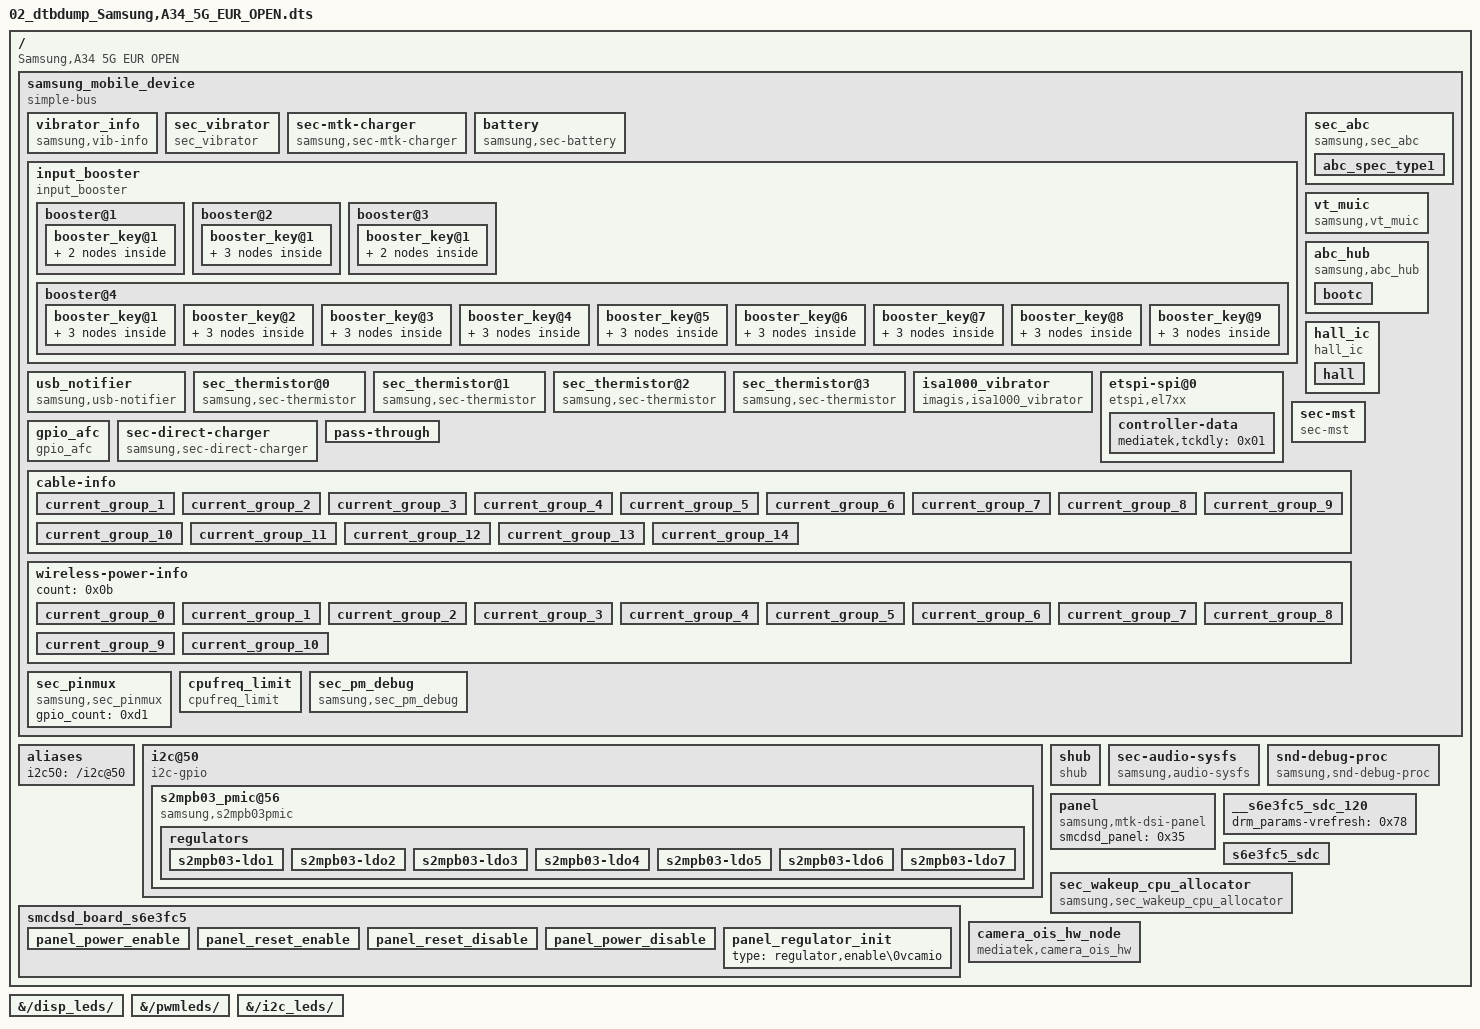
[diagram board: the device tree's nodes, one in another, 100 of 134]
/dts-v1/;

/ {
	compatible = "Samsung,A34 5G EUR OPEN\0Mediatek,MT6877";
	dtbo-hw_rev = <0x05>;
	dtbo-hw_rev_end = <0x20>;

	fragment@smd {
		target-path = "/";

		__overlay__ {

			samsung_mobile_device {
				compatible = "simple-bus";
				#address-cells = <0x01>;
				#size-cells = <0x00>;

				vibrator_info {
					status = "okay";
					compatible = "samsung,vib-info";
					functions = "INTENSITY\0HAPTIC_ENGINE";
					samsung,intensities = <0x00 0x7d0 0xfa0 0x1770 0x1f40 0x2710>;
					samsung,haptic_intensities = <0x00 0xbb8 0xfa0 0x1770 0x1f40 0x2710>;
				};

				sec_vibrator {
					status = "okay";
					compatible = "sec_vibrator";
					haptic,normal_ratio = <0x54>;
					haptic,high_temp_ref = <0x30>;
					haptic,high_temp_ratio = <0x47>;
				};

				sec-mtk-charger {
					compatible = "samsung,sec-mtk-charger";
					charger,vbus_min_charger_voltage = <0x432380>;
					charger,vbus_normal_mivr_voltage = <0x432380>;
					charger,gpio_chgenb = <0xffffffff 0x1b 0x00>;
					charger,max_icl = <0xc99>;
					charger,ib_fcc = <0x64>;
					charger,mt6360_charger = <0x01>;
				};

				battery {
					battery,otg_name = "mtk-otg";
					battery,fuelgauge_name = "mtk-fg-battery";
					status = "okay";
					compatible = "samsung,sec-battery";
					battery,vendor = "Battery";
					battery,charger_name = "sec-direct-charger";
					battery,technology = <0x02>;
					battery,chip_vendor = "MTK";
					battery,batt_data_version = <0x01>;
					battery,adc_check_count = <0x05>;
					battery,temp_check_type = <0x01>;
					battery,usb_temp_check_type = <0x00>;
					battery,chg_temp_check_type = <0x01>;
					battery,wpc_temp_check_type = <0x00>;
					battery,lrp_temp_check_type = <0x02>;
					battery,thermal_source = <0x05>;
					battery,usb_thermal_source = <0x00>;
					battery,chg_thermal_source = <0x02>;
					battery,wpc_thermal_source = <0x00>;
					battery,inbat_ocv_type = <0x04>;
					battery,polling_time = <0x0a 0x1e 0x1e 0x1e 0xe10>;
					battery,cable_check_type = <0x04>;
					battery,cable_source_type = <0x01>;
					battery,polling_type = <0x01>;
					battery,monitor_initial_count = <0x00>;
					battery,battery_check_type = <0x00>;
					battery,ovp_uvlo_check_type = <0x03>;
					battery,temp_check_count = <0x01>;
					battery,usb_protection_temp = <0x262>;
					battery,temp_gap_bat_usb = <0xc8>;
					battery,overheatlimit_threshold = <0x2bc>;
					battery,overheatlimit_recovery = <0x2a8>;
					battery,wire_warm_overheat_thresh = <0x1f4>;
					battery,wire_normal_warm_thresh = <0x1a4>;
					battery,wire_cool1_normal_thresh = <0xb4>;
					battery,wire_cool2_cool1_thresh = <0x96>;
					battery,wire_cool3_cool2_thresh = <0x32>;
					battery,wire_cold_cool3_thresh = <0x00>;
					battery,wireless_warm_overheat_thresh = <0x1f4>;
					battery,wireless_normal_warm_thresh = <0x1a4>;
					battery,wireless_cool1_normal_thresh = <0xb4>;
					battery,wireless_cool2_cool1_thresh = <0x96>;
					battery,wireless_cool3_cool2_thresh = <0x32>;
					battery,wireless_cold_cool3_thresh = <0x00>;
					battery,tx_high_threshold = <0x1f4>;
					battery,tx_high_recovery = <0x1c2>;
					battery,tx_low_threshold = <0x00>;
					battery,tx_low_recovery = <0x32>;
					battery,wire_warm_current = <0xdac>;
					battery,wire_cool1_current = <0xbb8>;
					battery,wire_cool2_current = <0x47e>;
					battery,wire_cool3_current = <0x1c2>;
					battery,wireless_warm_current = <0x418>;
					battery,wireless_cool1_current = <0xc4a>;
					battery,wireless_cool2_current = <0x418>;
					battery,wireless_cool3_current = <0x1b5>;
					battery,full_check_type = <0x02>;
					battery,full_check_type_2nd = <0x02>;
					battery,full_check_count = <0x01>;
					battery,chg_gpio_full_check = <0x00>;
					battery,chg_polarity_full_check = <0x01>;
					battery,chg_high_temp = <0x24e>;
					battery,chg_high_temp_recovery = <0x226>;
					battery,chg_input_limit_current = <0x3e8>;
					battery,chg_charging_limit_current = <0x76c>;
					battery,dchg_high_temp = <0x3e8 0x3e8 0x24e 0x24e>;
					battery,dchg_high_temp_recovery = <0x3e8 0x3e8 0x226 0x226>;
					battery,dchg_high_batt_temp = <0x3e8 0x3e8 0x3e8 0x3e8>;
					battery,dchg_high_batt_temp_recovery = <0x3e8 0x3e8 0x3e8 0x3e8>;
					battery,dchg_input_limit_current = <0x44c>;
					battery,dchg_charging_limit_current = <0x898>;
					battery,wpc_temp_control_source = <0x01>;
					battery,wpc_high_temp = <0x190>;
					battery,wpc_high_temp_recovery = <0x17c>;
					battery,wpc_input_limit_current = <0x320>;
					battery,wpc_charging_limit_current = <0x3e8>;
					battery,wpc_temp_lcd_on_control_source = <0x01>;
					battery,wpc_lcd_on_input_limit_current = <0x320>;
					battery,wpc_store_high_temp = <0x168>;
					battery,wpc_store_high_temp_recovery = <0x154>;
					battery,wpc_store_charging_limit_current = <0x190>;
					battery,wpc_store_lcd_on_high_temp = <0x168>;
					battery,wpc_store_lcd_on_high_temp_rec = <0x12c>;
					battery,wpc_store_lcd_on_charging_limit_current = <0x190>;
					battery,fcc_by_tx = <0x4b0>;
					battery,sleep_mode_limit_current = <0x320>;
					battery,wc_full_input_limit_current = <0x64>;
					battery,ta_alert_wa;
					battery,mix_high_temp = <0x1a4>;
					battery,mix_high_chg_temp = <0x1f4>;
					battery,mix_high_temp_recovery = <0x186>;
					battery,mix_v2_lrp_recov = <0x1cc>;
					battery,mix_v2_lrp_cond = <0x1e0>;
					battery,mix_v2_bat_cond = <0x1e0>;
					battery,mix_v2_chg_cond = <0x00>;
					battery,mix_v2_dchg_cond = <0x00>;
					battery,full_condition_type = <0x09>;
					battery,full_condition_soc = <0x5d>;
					battery,recharge_check_count = <0x01>;
					battery,recharge_condition_type = <0x04>;
					battery,recharge_condition_soc = <0x62>;
					battery,charging_reset_time = <0x00>;
					battery,chg_float_voltage = <0x1144>;
					battery,pre_afc_work_delay = <0x7d0>;
					battery,pre_wc_afc_work_delay = <0xfa0>;
					battery,pre_afc_input_current = <0x1f4>;
					battery,pre_wc_afc_input_current = <0x1f4>;
					battery,swelling_high_rechg_voltage = <0xfd2>;
					battery,siop_icl = <0x4b0>;
					battery,siop_fcc = <0x708>;
					battery,siop_hv_icl = <0x2bc>;
					battery,siop_hv_icl_2nd = <0x226>;
					battery,siop_hv_fcc = <0x708>;
					battery,siop_apdo_icl = <0x3e8>;
					battery,siop_apdo_fcc = <0x7d0>;
					battery,siop_wpc_icl = <0x258>;
					battery,siop_wpc_fcc = <0x3e8 0x1f4 0x64>;
					battery,siop_hv_wpc_icl = <0x2bc>;
					battery,siop_hv_wpc_fcc = <0x3e8 0x1f4 0x64>;
					battery,siop_store_hv_wpc_icl = <0x1c2>;
					battery,store_mode_buckoff;
					battery,temp_table_LRP_45W = <0x181 0x16d>;
					battery,rp_current_rp1 = <0x1f4>;
					battery,rp_current_rp2 = <0x5dc>;
					battery,rp_current_rp3 = <0xbb8>;
					battery,rp_current_rdu_rp3 = <0x834>;
					battery,rp_current_abnormal_rp3 = <0x708>;
					battery,pd_charging_charge_power = <0x3a98>;
					battery,max_charging_current = <0xbb8>;
					battery,store_mode_charging_max = <0x46>;
					battery,store_mode_charging_min = <0x3c>;
					battery,wireless_cc_cv = <0x55>;
					battery,wireless_otg_input_current = <0x384>;
					battery,age_data_cycle = <0x00 0x12c 0x190 0x2bc 0x3e9>;
					battery,age_data_full_condition_soc = <0x5d 0x5c 0x5b 0x5a 0x59>;
					battery,age_data_common_offset = <0x00 0x14 0x28 0x3c 0x6e>;
					battery,age_data = <0x00 0x10fe 0x10b8 0x109a 0x5d 0x12c 0x10ea 0x10a4 0x1086 0x5c 0x190 0x10d6 0x1090 0x1072 0x5b 0x2bc 0x10c2 0x107c 0x105e 0x5a 0x3e8 0x1090 0x104a 0x102c 0x59>;
					battery,health_condition_cycle = <0x384 0x4b0 0x5dc>;
					battery,health_condition_asoc = <0x00 0x00 0x00>;
					battery,max_input_voltage = <0x2328>;
					battery,max_input_current = <0xbb8>;
					battery,cisd_alg_index = <0x08>;
					battery,cisd_max_voltage_thr = <0x1388>;
					battery,ignore_cisd_index = <0x00 0x00>;
					battery,ignore_cisd_index_d = <0x00 0x50>;
					battery,expired_time = <0x2670>;
					battery,recharging_expired_time = <0x1518>;
					battery,battery_full_capacity = <0x1388>;
					battery,ttf_capacity = <0xf23>;
					battery,cv_data = <0xe06 0x33e 0x6b1 0xcaf 0x352 0x63f 0xaa0 0x366 0x5c3 0x876 0x37a 0x527 0x6a5 0x38e 0x477 0x4ed 0x3a2 0x39e 0x3ac 0x3b6 0x2a4 0x29f 0x3ca 0x17d 0x22a 0x3de 0x5d 0x205 0x3e8 0x00>;
					io-channels = <0xffffffff 0x03>;
					io-channel-names = "adc-chg-temp\0n/a\0n/a\0n/a\0n/a\0n/a\0n/a\0n/a";
					pinctrl-names = "default";
					battery,adc_read_type = <0x01>;
					battery,dchg_temp_check_type = <0x02>;
					battery,dchg_thermal_source = <0x02>;
					battery,dctp_by_cgtp;
					battery,temp_table_adc = <0xe5 0xff 0x119 0x14c 0x17c 0x1bd 0x1f9 0x24f 0x2b2 0x33f 0x3a5 0x420 0x4b2 0x54b 0x5e7 0x69f 0x72a 0x7cb 0x855 0x8d5 0x93f 0x9a0 0x9fe>;
					battery,temp_table_data = <0x384 0x352 0x320 0x2ee 0x2bc 0x28a 0x258 0x226 0x1f4 0x1c2 0x190 0x15e 0x12c 0xfa 0xc8 0x96 0x64 0x32 0x00 0xffffffce 0xffffff9c 0xffffff6a 0xffffff38>;
					battery,chg_temp_table_adc = <0x140 0x182 0x1cc 0x221 0x25f 0x2d0 0x326 0x3a9 0x473 0x52c 0x614 0x6f4 0x7ed 0x8ed 0xa1d 0xb4c 0xc53 0xd00 0xe06 0xef4 0xfbd 0xff1 0xfff>;
					battery,chg_temp_table_data = <0x384 0x352 0x320 0x2ee 0x2bc 0x28a 0x258 0x226 0x1f4 0x1c2 0x190 0x15e 0x12c 0xfa 0xc8 0x96 0x64 0x32 0x00 0xffffffce 0xffffff9c 0xffffff6a 0xffffff38>;
					battery,usb_protection;
					battery,high_temp_topoff = <0xfa>;
					battery,low_temp_topoff = <0xfa>;
					battery,high_temp_float = <0x1068>;
					battery,low_temp_float = <0x1144>;
					battery,dchg_dc_in_swelling;
					battery,temp_table_LRP_NORMAL = <0x190 0x186 0x186 0x17c 0x186 0x17c 0x17c 0x172 0x3e8 0x960 0x4b0 0x708>;
					battery,temp_table_LRP_25W = <0x19a 0x190 0x186 0x17c 0x190 0x186 0x17c 0x172 0x6a4 0xd48 0x44c 0x898>;
					battery,swelling_low_rechg_voltage = <0x10ae>;
					battery,max_charging_charge_power = <0x61a8>;
					battery,age_data_by_common_offset;
					battery,dc_step_chg_type = <0xe9>;
					battery,dc_step_chg_charge_power = <0x55f0>;
					battery,dc_step_chg_step = <0x03>;
					battery,dc_step_chg_cond_v_margin = <0x50>;
					battery,dc_step_chg_cond_vol = <0x1022 0x109a 0x1144>;
					battery,dc_step_chg_cond_iin = <0x8f2 0x721 0x00>;
					battery,dc_step_chg_iin_check_cnt = <0x03>;
					battery,dc_step_chg_cond_soc = <0x2f 0x41 0x64>;
					battery,dc_step_chg_val_vfloat = <0x1022 0x109a 0x1144>;
					battery,dc_step_chg_val_iout = <0x15a4 0x11e4 0xe42>;
					battery,siop_scenarios = <0x14 0x00>;
					battery,siop_curr_type_num = <0x03>;
					battery,siop_icl_20 = <0x3e8 0x3e8 0x3e8>;
					battery,siop_fcc_20 = <0xffff 0xffff 0xffff>;
					battery,siop_icl_0 = <0x3e8 0x3e8 0x3e8>;
					battery,siop_fcc_0 = <0xffff 0xffff 0xffff>;
					battery,standard_curr = <0xe6a>;
					battery,slowcharging_usb_bootcomplete;
					battery,dynamic_cv_factor;
					battery,change_FV_after_full = <0x1144>;
					battery,ttf_hv_charge_current = <0x825>;
					battery,ttf_dc25_charge_current = <0xe10>;
					battery,boosting_voltage_aicl;
				};

				input_booster {
					status = "okay";
					compatible = "input_booster";
					resValcount = "2";
					max_resource_count = "2";
					max_cluster_count = "3";
					#address-cells = <0x01>;
					#size-cells = <0x00>;
					cpu_cluster_policy = "6,0";
					ib_release_values = "-1,16";
					allowed_resources = "0,1";

					booster@1 {
						booster,label = "Disable_Mode";
						booster,mode = "1";

						booster_key@1 {
							input_booster,label = "Touch_Disable";
							input_booster,type = <0x02>;
							input_booster,head_time = <0x00>;
							input_booster,tail_time = <0x00>;

							input_booster,resource {
								compatible = "resource";

								resource@1 {
									resource,label = "CPU";
									resource,id = "0";
									resource,value = <0x00 0x00>;
								};
							};
						};
					};

					booster@2 {
						booster,label = "Sip_Mode";
						booster,mode = "2";

						booster_key@1 {
							input_booster,label = "sip_touch";
							input_booster,type = <0x02>;
							input_booster,head_time = <0x78>;
							input_booster,tail_time = <0x00>;

							input_booster,resource {
								compatible = "resource";

								resource@1 {
									resource,label = "CPU";
									resource,id = "0";
									resource,value = <0x116520 0x00>;
								};

								resource@2 {
									resource,label = "DDR";
									resource,id = "1";
									resource,value = <0x10aa 0x10aa>;
								};
							};
						};
					};

					booster@3 {
						booster,label = "Game_Mode";
						booster,mode = "3";

						booster_key@1 {
							input_booster,label = "GAME_MT";
							input_booster,type = <0x03>;
							input_booster,head_time = <0x00>;
							input_booster,tail_time = <0x00>;

							input_booster,resource {
								compatible = "resource";

								resource@1 {
									resource,label = "CPU";
									resource,id = "0";
									resource,value = <0x00 0x00>;
								};
							};
						};
					};

					booster@4 {
						booster,label = "input_booster";
						booster,mode = "0";

						booster_key@1 {
							input_booster,label = "key";
							input_booster,type = <0x00>;
							input_booster,head_time = <0xc8>;
							input_booster,tail_time = <0x00>;

							inputbooster,resource {
								compatible = "resource";

								resource@1 {
									resource,label = "CPU";
									resource,id = "0";
									resource,value = <0x177fa0 0x00>;
								};

								resource@2 {
									resource,label = "DDR";
									resource,id = "1";
									resource,value = <0x00 0x00>;
								};
							};
						};

						booster_key@2 {
							input_booster,label = "touchkey";
							input_booster,type = <0x01>;
							input_booster,head_time = <0x01>;
							input_booster,tail_time = <0x12c>;

							inputbooster,resource {
								compatible = "resource";

								resource@1 {
									resource,label = "CPU";
									resource,id = "0";
									resource,value = <0x00 0x00>;
								};

								resource@2 {
									resource,label = "DDR";
									resource,id = "1";
									resource,value = <0x00 0x00>;
								};
							};
						};

						booster_key@3 {
							input_booster,label = "touch";
							input_booster,type = <0x02>;
							input_booster,head_time = <0x82>;
							input_booster,tail_time = <0x1f4>;

							inputbooster,resource {
								compatible = "resource";

								resource@1 {
									resource,label = "CPU";
									resource,id = "0";
									resource,value = <0x116520 0x106800>;
								};

								resource@2 {
									resource,label = "DDR";
									resource,id = "1";
									resource,value = <0x10aa 0x10aa>;
								};
							};
						};

						booster_key@4 {
							input_booster,label = "multitouch";
							input_booster,type = <0x03>;
							input_booster,head_time = <0x3e8>;
							input_booster,tail_time = <0x1f4>;

							inputbooster,resource {
								compatible = "resource";

								resource@1 {
									resource,label = "CPU";
									resource,id = "0";
									resource,value = <0x116520 0x106800>;
								};

								resource@2 {
									resource,label = "DDR";
									resource,id = "1";
									resource,value = <0x10aa 0x10aa>;
								};
							};
						};

						booster_key@5 {
							input_booster,label = "keyboard";
							input_booster,type = <0x04>;
							input_booster,head_time = <0x82>;
							input_booster,tail_time = <0x82>;

							inputbooster,resource {
								compatible = "resource";

								resource@1 {
									resource,label = "CPU";
									resource,id = "0";
									resource,value = <0x15d1f0 0xfde80>;
								};

								resource@2 {
									resource,label = "DDR";
									resource,id = "1";
									resource,value = <0x10aa 0x10aa>;
								};
							};
						};

						booster_key@6 {
							input_booster,label = "MOUSE";
							input_booster,type = <0x05>;
							input_booster,head_time = <0xc8>;
							input_booster,tail_time = <0x12c>;

							inputbooster,resource {
								compatible = "resource";

								resource@1 {
									resource,label = "CPU";
									resource,id = "0";
									resource,value = <0x15d1f0 0xfde80>;
								};

								resource@2 {
									resource,label = "DDR";
									resource,id = "1";
									resource,value = <0x10aa 0x10aa>;
								};
							};
						};

						booster_key@7 {
							input_booster,label = "mouse_wheel";
							input_booster,type = <0x06>;
							input_booster,head_time = <0xc8>;
							input_booster,tail_time = <0x00>;

							inputbooster,resource {
								compatible = "resource";

								resource@1 {
									resource,label = "CPU";
									resource,id = "0";
									resource,value = <0x15d1f0 0x00>;
								};

								resource@2 {
									resource,label = "DDR";
									resource,id = "1";
									resource,value = <0x10aa 0x00>;
								};
							};
						};

						booster_key@8 {
							input_booster,label = "pen_hover";
							input_booster,type = <0x07>;
							input_booster,head_time = <0xc8>;
							input_booster,tail_time = <0x12c>;

							inputbooster,resource {
								compatible = "resource";

								resource@1 {
									resource,label = "CPU";
									resource,id = "0";
									resource,value = <0x15d1f0 0xfde80>;
								};

								resource@2 {
									resource,label = "DDR";
									resource,id = "1";
									resource,value = <0x00 0x00>;
								};
							};
						};

						booster_key@9 {
							input_booster,label = "pen";
							input_booster,type = <0x08>;
							input_booster,head_time = <0xc8>;
							input_booster,tail_time = <0x258>;

							inputbooster,resource {
								compatible = "resource";

								resource@1 {
									resource,label = "CPU";
									resource,id = "0";
									resource,value = <0x1b7740 0xfde80>;
								};

								resource@2 {
									resource,label = "DDR";
									resource,id = "1";
									resource,value = <0x10aa 0x10aa>;
								};
							};
						};
					};
				};

				sec_abc {
					compatible = "samsung,sec_abc";
					status = "okay";

					abc_spec_type1 {
						module_list = "gpu\0gpu_qc\0gpu_qc\0camera\0camera\0vib\0tsp\0tsp_sub\0mm\0camera\0camera\0camera\0camera\0camera\0camera\0camera\0camera\0camera\0gpu";
						name_list = "gpu_fault\0gpu_fault\0gpu_page_fault\0mipi_overflow\0i2c_fail\0int_gnd_short\0tsp_int_fault\0tsp_int_fault\0venus_hung\0mipi_error_rw1\0mipi_error_rs1\0mipi_error_rt1\0mipi_error_fw1\0mipi_error_rt2\0mipi_error_uw1\0mipi_error_rm1\0mipi_error_rb1\0mipi_error_fs1\0gpu_job_timeout";
						threshold_cnt = <0x14 0x02 0x14 0x01 0x01 0x19 0x02 0x02 0x0a 0x01 0x01 0x01 0x01 0x01 0x01 0x01 0x01 0x01 0x01>;
						threshold_time = <0x4b0 0x4b0 0x4b0 0x00 0x00 0x05 0x05 0x05 0x03 0x00 0x00 0x00 0x00 0x00 0x00 0x00 0x00 0x00 0x00>;
					};
				};

				vt_muic {
					compatible = "samsung,vt_muic";
					status = "okay";
					use_battery_notifier_callback;
					use_manager_notifier_callback;
				};

				abc_hub {
					compatible = "samsung,abc_hub";
					status = "okay";

					bootc {
						bootc,time_spec_user = <0x186a0>;
						bootc,time_spec_eng = <0x249f0>;
						bootc,time_spec_fac = <0x186a0>;
					};
				};

				usb_notifier {
					compatible = "samsung,usb-notifier";
					status = "okay";
				};

				sec_thermistor@0 {
					compatible = "samsung,sec-thermistor";
					status = "okay";
					thermistor_name = "sec-cp-thermistor";
					id = <0x00>;
					io-channels = <0xffffffff 0x02>;
					io-channel-names = "cp_therm";
					io-channel-ranges;
					adc_array = <0x14f 0x18f 0x1d5 0x22d 0x27c 0x2f2 0x34e 0x3d1 0x472 0x525 0x60c 0x6e4 0x7d9 0x8e5 0x984 0xad2 0xbd5 0xd50 0xe51 0xf37 0xfba 0xfff 0xfff>;
					temp_array = <0x384 0x352 0x320 0x2ee 0x2bc 0x28a 0x258 0x226 0x1f4 0x1c2 0x190 0x15e 0x12c 0xfa 0xc8 0x96 0x64 0x32 0x00 0xffffffce 0xffffff9c 0xffffff6a 0xffffff38>;
				};

				sec_thermistor@1 {
					compatible = "samsung,sec-thermistor";
					status = "okay";
					thermistor_name = "sec-pa-thermistor";
					id = <0x01>;
					io-channels = <0xffffffff 0x01>;
					io-channel-names = "pa_therm";
					io-channel-ranges;
					adc_array = <0x14c 0x18d 0x1d4 0x22b 0x27a 0x2f0 0x36f 0x3d1 0x470 0x524 0x608 0x6e6 0x7e3 0x8e4 0xa07 0xb36 0xc45 0xd52 0xe4c 0xf34 0xfba 0xfff 0xfff>;
					temp_array = <0x384 0x352 0x320 0x2ee 0x2bc 0x28a 0x258 0x226 0x1f4 0x1c2 0x190 0x15e 0x12c 0xfa 0xc8 0x96 0x64 0x32 0x00 0xffffffce 0xffffff9c 0xffffff6a 0xffffff38>;
				};

				sec_thermistor@2 {
					compatible = "samsung,sec-thermistor";
					status = "okay";
					thermistor_name = "sec-ap-thermistor";
					id = <0x02>;
					io-channels = <0xffffffff 0x00>;
					io-channel-names = "ap_therm";
					io-channel-ranges;
					adc_array = <0x54 0x66 0x7c 0x95 0xae 0xd2 0xf0 0x11f 0x164 0x19b 0x1fb 0x25d 0x2dd 0x36b 0x425 0x505 0x5ef 0x6f9 0x826 0x968 0xab5 0xba6 0xd26>;
					temp_array = <0x384 0x352 0x320 0x2ee 0x2bc 0x28a 0x258 0x226 0x1f4 0x1c2 0x190 0x15e 0x12c 0xfa 0xc8 0x96 0x64 0x32 0x00 0xffffffce 0xffffff9c 0xffffff6a 0xffffff38>;
				};

				sec_thermistor@3 {
					compatible = "samsung,sec-thermistor";
					status = "okay";
					thermistor_name = "sec-lp-thermistor";
					id = <0x03>;
					io-channels = <0xffffffff 0x04>;
					io-channel-names = "lp_therm";
					io-channel-ranges;
					adc_array = <0x144 0x186 0x1cf 0x224 0x250 0x2bd 0x322 0x392 0x433 0x4c9 0x5aa 0x67e 0x774 0x86b 0x993 0xac2 0xbd2 0xcc8 0xdcd 0xec0 0xf94 0xfff 0xfff>;
					temp_array = <0x384 0x352 0x320 0x2ee 0x2bc 0x28a 0x258 0x226 0x1f4 0x1c2 0x190 0x15e 0x12c 0xfa 0xc8 0x96 0x64 0x32 0x00 0xffffffce 0xffffff9c 0xffffff6a 0xffffff38>;
				};

				isa1000_vibrator {
					status = "okay";
					compatible = "imagis,isa1000_vibrator";
					isa1000,duty_ratio = <0x54>;
					isa1000,gpio_en = <0xffffffff 0xc3 0x00>;
					isa1000,motor_type = "LINEAR_1040";
					isa1000,multi_frequency = <0x01>;
					isa1000,frequency = <0x802>;
					pinctrl-names = "default";
					pinctrl-0 = <0x01 0x02>;
					samsung,steps = <0x06>;
					samsung,intensities = <0x00 0xbb8 0xfa0 0x1770 0x1f40 0x2710>;
					samsung,haptic_intensities = <0x00 0x7d0 0xfa0 0x1770 0x1f40 0x2710>;
				};

				hall_ic {
					status = "okay";
					compatible = "hall_ic";
					pinctrl-names = "default";
					pinctrl-0 = <0x03>;
					hall_ic,debounce-interval = <0x32>;

					hall {
						event = <0x15>;
						gpios = <0xffffffff 0x06 0x01>;
						flags = <0x01>;
					};
				};

				etspi-spi@0 {
					compatible = "etspi,el7xx";
					reg = <0x00>;
					spi-max-frequency = <0x17d7840>;
					clocks = <0xffffffff 0x09 0xffffffff 0x90 0xffffffff 0x2f>;
					clock-names = "parent-clk\0sel-clk\0spi-clk";
					pinctrl-names = "default\0pins_poweron\0pins_poweroff";
					pinctrl-0 = <0x04 0x05>;
					pinctrl-1 = <0x06 0x07 0x08 0x09>;
					pinctrl-2 = <0x0a 0x0b 0x0c 0x0d>;
					gpio-controller;
					#gpio-cells = <0x02>;
					etspi-sleepPin = <0xffffffff 0x79 0x00>;
					etspi-ldoPin = <0xffffffff 0x60 0x00>;
					etspi-chipid = "EL721";
					etspi-modelinfo = "A346";
					etspi-position = "11.69,0.00,9.10,9.10,14.80,14.80,12.00,12.00,5.00";
					etspi-rb = "588,-1,-1,FFFFFF";

					controller-data {
						mediatek,tckdly = <0x01>;
					};
				};

				sec-mst {
					compatible = "sec-mst";
					sec-mst,mst-pwr-gpio = <0xffffffff 0x6d 0x00>;
					pinctrl-names = "default";
					pinctrl-0 = <0x0e>;
				};

				gpio_afc {
					compatible = "gpio_afc";
					pinctrl-names = "default";
					pinctrl-0 = <0x0f 0x10 0x11>;
					status = "okay";
					gpio_afc_data = <0xffffffff 0x0c 0x00>;
					gpio_afc_switch = <0xffffffff 0x4c 0x00>;
					gpio_hiccup = <0xffffffff 0x61 0x00>;
				};

				sec-direct-charger {
					status = "okay";
					compatible = "samsung,sec-direct-charger";
					charger,battery_name = "battery";
					charger,main_charger = "sec-mtk-charger";
					charger,direct_charger = "sm5451-charger";
					charger,dchg_min_current = <0x7d0>;
					charger,ta_alert_wa;
				};

				pass-through {
					start_delay = <0x1388>;
					init_delay = <0x1388>;
					min_cap = <0xc8>;
					fixed_sc_cap = <0x384>;
					max_icl = <0xbb8>;
				};

				cable-info {
					default_input_current = <0x708>;
					default_charging_current = <0x834>;
					full_check_current_1st = <0x1ea>;
					full_check_current_2nd = <0xfa>;

					current_group_1 {
						cable_number = <0x02 0x13 0x15 0x16 0x17>;
						input_current = <0x1f4>;
						charging_current = <0x1f4>;
					};

					current_group_2 {
						cable_number = <0x19 0x1f>;
						input_current = <0x3e8>;
						charging_current = <0x3e8>;
					};

					current_group_3 {
						cable_number = <0x05 0x20>;
						input_current = <0x5dc>;
						charging_current = <0x5dc>;
					};

					current_group_4 {
						cable_number = <0x06 0x07 0x08 0x11 0x12>;
						input_current = <0x672>;
						charging_current = <0xbb8>;
					};

					current_group_5 {
						cable_number = <0x09>;
						input_current = <0x672>;
						charging_current = <0xbb8>;
					};

					current_group_6 {
						cable_number = <0x0a 0x0c 0x0f 0x1b 0x24>;
						input_current = <0x320>;
						charging_current = <0xbb8>;
					};

					current_group_7 {
						cable_number = <0x0d>;
						input_current = <0x2bc>;
						charging_current = <0xbb8>;
					};

					current_group_8 {
						cable_number = <0x18>;
						input_current = <0x3e8>;
						charging_current = <0x1c2>;
					};

					current_group_9 {
						cable_number = <0x1a>;
						input_current = <0x708>;
						charging_current = <0x708>;
					};

					current_group_10 {
						cable_number = <0x0b 0x0e 0x10 0x1c 0x23>;
						input_current = <0x28a>;
						charging_current = <0xbb8>;
					};

					current_group_11 {
						cable_number = <0x1d 0x25>;
						input_current = <0x1f4>;
						charging_current = <0x4b0>;
					};

					current_group_12 {
						cable_number = <0x01 0x04 0x1e>;
						input_current = <0x1db>;
						charging_current = <0x226>;
					};

					current_group_13 {
						cable_number = <0x22>;
						input_current = <0x4b0>;
						charging_current = <0x92e>;
					};

					current_group_14 {
						cable_number = <0x21>;
						input_current = <0x320>;
						charging_current = <0x92e>;
					};
				};

				wireless-power-info {
					count = <0x0b>;

					current_group_0 {
						wireless_power_class = <0x02>;
						vout = <0x2328>;
						input_current_limit = <0x33e>;
						fast_charging_current = <0xc4e>;
						ttf_charge_current = <0x5dc>;
						rx_power = <0x1d4c>;
					};

					current_group_1 {
						wireless_power_class = <0x02>;
						vout = <0x2710>;
						input_current_limit = <0x2ee>;
						fast_charging_current = <0xc4e>;
						ttf_charge_current = <0x5dc>;
						rx_power = <0x1d4c>;
					};

					current_group_2 {
						wireless_power_class = <0x02>;
						vout = <0x2af8>;
						input_current_limit = <0x2a8>;
						fast_charging_current = <0xc4e>;
						ttf_charge_current = <0x5dc>;
						rx_power = <0x1d4c>;
					};

					current_group_3 {
						wireless_power_class = <0x02>;
						vout = <0x2ee0>;
						input_current_limit = <0x271>;
						fast_charging_current = <0xc4e>;
						ttf_charge_current = <0x5dc>;
						rx_power = <0x1d4c>;
					};

					current_group_4 {
						wireless_power_class = <0x02>;
						vout = <0x2328>;
						input_current_limit = <0x532>;
						fast_charging_current = <0xc4e>;
						ttf_charge_current = <0x87f>;
						rx_power = <0x2ee0>;
					};

					current_group_5 {
						wireless_power_class = <0x02>;
						vout = <0x2af8>;
						input_current_limit = <0x442>;
						fast_charging_current = <0xc4e>;
						ttf_charge_current = <0x834>;
						rx_power = <0x2ee0>;
					};

					current_group_6 {
						wireless_power_class = <0x02>;
						vout = <0x2ee0>;
						input_current_limit = <0x3e8>;
						fast_charging_current = <0xc4e>;
						ttf_charge_current = <0x834>;
						rx_power = <0x2ee0>;
					};

					current_group_7 {
						wireless_power_class = <0x02>;
						vout = <0x2af8>;
						input_current_limit = <0x550>;
						fast_charging_current = <0xc4e>;
						ttf_charge_current = <0x8fc>;
						rx_power = <0x3a98>;
					};

					current_group_8 {
						wireless_power_class = <0x02>;
						vout = <0x2ee0>;
						input_current_limit = <0x4e2>;
						fast_charging_current = <0xc4e>;
						ttf_charge_current = <0x8fc>;
						rx_power = <0x3a98>;
					};

					current_group_9 {
						wireless_power_class = <0x02>;
						vout = <0x32c8>;
						input_current_limit = <0x47e>;
						fast_charging_current = <0xc4e>;
						ttf_charge_current = <0x8fc>;
						rx_power = <0x3a98>;
					};

					current_group_10 {
						wireless_power_class = <0x02>;
						vout = <0x2710>;
						input_current_limit = <0x44c>;
						fast_charging_current = <0xc4e>;
						ttf_charge_current = <0x8fc>;
						rx_power = <0x2af8>;
					};
				};

				sec_pinmux {
					status = "okay";
					compatible = "samsung,sec_pinmux";
					gpio_count = <0xd1>;
				};

				cpufreq_limit {
					status = "okay";
					compatible = "cpufreq_limit";
					num_cpu = <0x08>;
					ltl_cpu_start = <0x00>;
					big_cpu_start = <0x06>;
					ltl_min_lock_freq = <0x118c30>;
					big_max_lock_freq = <0xde2b0>;
					ltl_divider = <0x04>;
					ltl_limit_table = <0x1e8480 0x1e8480 0x1cfde0 0x1d0998 0x195460 0x1b7740 0x177fa0 0x19fc58 0x9eb10 0x186a00>;
				};

				sec_pm_debug {
					status = "okay";
					compatible = "samsung,sec_pm_debug";
					thermal_zones = "mtktscpu\0mtktspmic\0mtktsbtsnrpa\0mtktsbattery\0mtktsAP\0mtktsbtsmdpa\0mtktspa\0mtktscharger\0mtktsdctm\0mtktswmt";
				};
			};
		};
	};

	fragment@0 {
		target = <0xffffffff>;

		__overlay__ {
			RBAT_TYPE = <0x64>;
			RBAT_PULL_UP_R = <0x186a0>;
			rbat_temperature_table_num = <0x15>;
			rbat_battery_temperature = <0xffffffd8 0x43183f 0xffffffdd 0x2f20d6 0xffffffe2 0x2186e9 0xffffffe7 0x182338 0xffffffec 0x11903c 0xfffffff1 0xceaf2 0xfffffff6 0x998fc 0xfffffffb 0x73250 0x00 0x57293 0x05 0x42873 0x0a 0x3332d 0x0f 0x27b5a 0x14 0x1f068 0x19 0x186a0 0x1e 0x13575 0x23 0xf6bf 0x28 0xc5f4 0x2d 0x9fc7 0x32 0x81aa 0x37 0x69d2 0x3c 0x56d0>;
			batteryid-gpio1 = <0xffffffff 0x15 0x00>;
			batteryid-gpio = <0xffffffff 0x16 0x00>;
			difference-fullocv-ith = <0x12c>;
			shutdown-1-time = <0x3c>;
			car-tune-value = <0x62>;
			shutdown-gauge0 = <0x00>;
			temperature-t0 = <0x32>;
			temperature-t1 = <0x19>;
			temperature-t2 = <0x0a>;
			temperature-t3 = <0x00>;
			temperature-t4 = <0xfffffff6>;
			temperature-t5 = <0xffffffec>;
			enable_tmp_intr_suspend = <0x00>;
			active-table = <0x06>;
			HWOCV_OLDOCV_DIFF = <0x64>;
			UI_FULL_LIMIT_EN = <0x01>;
			UI_FULL_LIMIT_SOC0 = <0x2549>;
			UI_FULL_LIMIT_ITH0 = <0x2ee0>;
			UI_FULL_LIMIT_SOC1 = <0x25ad>;
			UI_FULL_LIMIT_ITH1 = <0x2710>;
			UI_FULL_LIMIT_SOC2 = <0x2611>;
			UI_FULL_LIMIT_ITH2 = <0x1f40>;
			UI_FULL_LIMIT_SOC3 = <0x2675>;
			UI_FULL_LIMIT_ITH3 = <0x1964>;
			UI_FULL_LIMIT_SOC4 = <0x26d9>;
			UI_FULL_LIMIT_ITH4 = <0x14b4>;
			UI_LOW_LIMIT_EN = <0x01>;
			UI_LOW_LIMIT_SOC0 = <0x64>;
			UI_LOW_LIMIT_VTH0 = <0x84d0>;
			UI_LOW_LIMIT_SOC1 = <0x64>;
			UI_LOW_LIMIT_VTH1 = <0x84d0>;
			UI_LOW_LIMIT_SOC2 = <0x64>;
			UI_LOW_LIMIT_VTH2 = <0x84d0>;
			UI_LOW_LIMIT_SOC3 = <0x64>;
			UI_LOW_LIMIT_VTH3 = <0x84d0>;
			UI_LOW_LIMIT_SOC4 = <0x64>;
			UI_LOW_LIMIT_VTH4 = <0x84d0>;
			DYNAMIC_CV_FACTOR = <0x64>;
			CHARGER_IEOC = <0xfa>;
			nouse-baton-undet;
			battery0_profile_t0_num = <0x64>;
			battery0_profile_t0_col = <0x03>;
			battery0_profile_t0 = <0x00 0xabe0 0x22b 0x1ec 0xab74 0x22b 0x3d9 0xab07 0x23b 0x5c5 0xaaa1 0x23f 0x7b1 0xaa38 0x23f 0x99e 0xa9cc 0x23f 0xb8a 0xa960 0x23f 0xd76 0xa8f4 0x23f 0xf63 0xa888 0x23f 0x114f 0xa816 0x23f 0x133b 0xa7a0 0x23f 0x1528 0xa72a 0x23f 0x1714 0xa6b4 0x23f 0x1900 0xa63e 0x240 0x1aec 0xa5c7 0x252 0x1cd9 0xa551 0x258 0x1ec5 0xa4d6 0x258 0x20b1 0xa45b 0x258 0x229e 0xa3e3 0x246 0x248a 0xa36c 0x23f 0x2676 0xa2fb 0x23f 0x2863 0xa289 0x242 0x2a4f 0xa214 0x260 0x2c3b 0xa1a2 0x262 0x2e28 0xa134 0x258 0x3014 0xa0c4 0x259 0x3200 0xa053 0x265 0x33ed 0x9fe5 0x264 0x35d9 0x9f7d 0x258 0x37c5 0x9f16 0x25a 0x39b2 0x9ead 0x264 0x3b9e 0x9e4a 0x271 0x3d8a 0x9de8 0x272 0x3f77 0x9d85 0x27c 0x4163 0x9d24 0x28a 0x434f 0x9ccb 0x28a 0x453b 0x9c73 0x297 0x4728 0x9c1a 0x2a2 0x4914 0x9bc1 0x2af 0x4b00 0x9b69 0x2ba 0x4ced 0x9b10 0x2bc 0x4ed9 0x9ab2 0x2c7 0x50c5 0x9a31 0x2de 0x52b2 0x9989 0x2e3 0x549e 0x9909 0x2a3 0x568a 0x989e 0x269 0x5877 0x984c 0x24a 0x5a63 0x9803 0x240 0x5c4f 0x97bf 0x243 0x5e3c 0x9782 0x24e 0x6028 0x9747 0x24d 0x6214 0x970c 0x253 0x6401 0x96d1 0x258 0x65ed 0x9697 0x258 0x67d9 0x9662 0x24f 0x69c6 0x9630 0x245 0x6bb2 0x95ff 0x258 0x6d9e 0x95ce 0x258 0x6f8a 0x95a5 0x258 0x7177 0x957b 0x258 0x7363 0x9550 0x25f 0x754f 0x9526 0x26a 0x773c 0x9505 0x25c 0x7928 0x94e0 0x25e 0x7b14 0x94be 0x26a 0x7d01 0x949d 0x271 0x7eed 0x947a 0x271 0x80d9 0x945d 0x278 0x82c6 0x943f 0x284 0x84b2 0x941b 0x290 0x869e 0x93e2 0x29d 0x888b 0x9391 0x28b 0x8a77 0x9344 0x25b 0x8c63 0x930c 0x248 0x8e50 0x92d9 0x24c 0x903c 0x92a8 0x257 0x9228 0x9277 0x258 0x9415 0x9249 0x252 0x9601 0x9220 0x24c 0x97ed 0x91f5 0x24f 0x99d9 0x91d3 0x245 0x9bc6 0x91a8 0x250 0x9db2 0x9173 0x258 0x9f9e 0x9138 0x257 0xa18b 0x90f9 0x245 0xa377 0x90b7 0x24c 0xa563 0x9076 0x248 0xa750 0x9027 0x241 0xa93c 0x8ffb 0x241 0xab28 0x8fe9 0x240 0xad15 0x8fd7 0x240 0xaf01 0x8fc2 0x244 0xb0ed 0x8fa6 0x256 0xb2da 0x8f89 0x267 0xb4c6 0x8f34 0x271 0xb6b2 0x8e26 0x28f 0xb89f 0x8c62 0x283 0xba8b 0x8a1d 0x281 0xbc77 0x86f8 0x298 0xbe64 0x8296 0x2cb>;
			battery0_profile_t1_num = <0x64>;
			battery0_profile_t1_col = <0x03>;
			battery0_profile_t1 = <0x00 0xab68 0x322 0x1ec 0xaafc 0x322 0x3d9 0xaa97 0x335 0x5c5 0xaa2d 0x339 0x7b1 0xa9c8 0x339 0x99e 0xa958 0x33b 0xb8a 0xa8e8 0x350 0xd76 0xa875 0x33c 0xf63 0xa7ff 0x339 0x114f 0xa790 0x339 0x133b 0xa717 0x339 0x1528 0xa69d 0x34e 0x1714 0xa627 0x33d 0x1900 0xa5b1 0x339 0x1aec 0xa53b 0x339 0x1cd9 0xa4bf 0x339 0x1ec5 0xa445 0x34c 0x20b1 0xa3cd 0x33e 0x229e 0xa356 0x339 0x248a 0xa2df 0x34b 0x2676 0xa269 0x352 0x2863 0xa1f8 0x340 0x2a4f 0xa186 0x339 0x2c3b 0xa116 0x34a 0x2e28 0xa0a8 0x352 0x3014 0xa03c 0x353 0x3200 0x9fd0 0x360 0x33ed 0x9f63 0x36b 0x35d9 0x9efb 0x36b 0x37c5 0x9e98 0x36d 0x39b2 0x9e35 0x379 0x3b9e 0x9dd3 0x390 0x3d8a 0x9d70 0x39f 0x3f77 0x9d10 0x3a8 0x4163 0x9cb8 0x3b7 0x434f 0x9c5f 0x3c2 0x453b 0x9c07 0x3db 0x4728 0x9bae 0x3f3 0x4914 0x9b55 0x40c 0x4b00 0x9af9 0x41a 0x4ced 0x9a8b 0x424 0x4ed9 0x9a03 0x433 0x50c5 0x996e 0x41d 0x52b2 0x98ec 0x3d5 0x549e 0x9883 0x38a 0x568a 0x982c 0x343 0x5877 0x97e5 0x33a 0x5a63 0x97a0 0x331 0x5c4f 0x975f 0x325 0x5e3c 0x9723 0x32d 0x6028 0x96e9 0x323 0x6214 0x96b6 0x320 0x6401 0x9685 0x320 0x65ed 0x9653 0x321 0x67d9 0x9621 0x326 0x69c6 0x95f0 0x332 0x6bb2 0x95c6 0x325 0x6d9e 0x9599 0x329 0x6f8a 0x956f 0x329 0x7177 0x954a 0x32a 0x7363 0x9529 0x337 0x754f 0x9503 0x33f 0x773c 0x94e4 0x33d 0x7928 0x94c6 0x33e 0x7b14 0x94a8 0x354 0x7d01 0x9483 0x367 0x7eed 0x9469 0x362 0x80d9 0x9450 0x360 0x82c6 0x9432 0x36b 0x84b2 0x940d 0x380 0x869e 0x93df 0x383 0x888b 0x93ae 0x36b 0x8a77 0x9384 0x33d 0x8c63 0x935c 0x339 0x8e50 0x9330 0x339 0x903c 0x9303 0x337 0x9228 0x92d6 0x323 0x9415 0x92b1 0x336 0x9601 0x928d 0x324 0x97ed 0x926a 0x320 0x99d9 0x9243 0x323 0x9bc6 0x920d 0x332 0x9db2 0x91d2 0x337 0x9f9e 0x9196 0x326 0xa18b 0x915b 0x32f 0xa377 0x911b 0x329 0xa563 0x90ce 0x321 0xa750 0x9090 0x32e 0xa93c 0x906d 0x33a 0xab28 0x905d 0x33d 0xad15 0x904d 0x340 0xaf01 0x903c 0x343 0xb0ed 0x9025 0x347 0xb2da 0x8fe1 0x350 0xb4c6 0x8f2a 0x361 0xb6b2 0x8d94 0x36b 0xb89f 0x8b63 0x36c 0xba8b 0x885e 0x388 0xbc77 0x83c4 0x408 0xbe64 0x7e0e 0x58a>;
			battery0_profile_t2_num = <0x64>;
			battery0_profile_t2_col = <0x03>;
			battery0_profile_t2 = <0x00 0xaac8 0x57a 0x1ec 0xaa5c 0x57a 0x3d9 0xa9ef 0x5a2 0x5c5 0xa97e 0x5d0 0x7b1 0xa909 0x5dc 0x99e 0xa898 0x5dc 0xb8a 0xa825 0x5dc 0xd76 0xa7b0 0x5dc 0xf63 0xa736 0x5df 0x114f 0xa6bb 0x5ed 0x133b 0xa644 0x5e7 0x1528 0xa5ce 0x5ed 0x1714 0xa554 0x5f8 0x1900 0xa4d9 0x605 0x1aec 0xa45d 0x5fd 0x1cd9 0xa3e3 0x5f5 0x1ec5 0xa36b 0x5f5 0x20b1 0xa2f4 0x5f8 0x229e 0xa27d 0x605 0x248a 0xa20a 0x60b 0x2676 0xa198 0x606 0x2863 0xa127 0x612 0x2a4f 0xa0b9 0x627 0x2c3b 0xa04a 0x629 0x2e28 0x9fdb 0x631 0x3014 0x9f73 0x636 0x3200 0x9f08 0x637 0x33ed 0x9e9d 0x64d 0x35d9 0x9e3a 0x65b 0x37c5 0x9dd7 0x667 0x39b2 0x9d75 0x680 0x3b9e 0x9d12 0x68b 0x3d8a 0x9cb9 0x699 0x3f77 0x9c58 0x6b1 0x4163 0x9bfe 0x6bc 0x434f 0x9ba4 0x6d9 0x453b 0x9b43 0x6ed 0x4728 0x9ad8 0x6fa 0x4914 0x9a5f 0x708 0x4b00 0x99cb 0x6f3 0x4ced 0x993b 0x69c 0x4ed9 0x98c2 0x639 0x50c5 0x985e 0x5e4 0x52b2 0x980d 0x5bf 0x549e 0x97c2 0x5ab 0x568a 0x977e 0x5aa 0x5877 0x973c 0x5aa 0x5a63 0x96ff 0x5aa 0x5c4f 0x96c5 0x5aa 0x5e3c 0x9690 0x5a2 0x6028 0x965f 0x597 0x6214 0x962d 0x5b0 0x6401 0x95fc 0x5bf 0x65ed 0x95cb 0x5c3 0x67d9 0x9599 0x5c3 0x69c6 0x956e 0x5b9 0x6bb2 0x9547 0x5b6 0x6d9e 0x951f 0x5c6 0x6f8a 0x94f8 0x5d9 0x7177 0x94d6 0x5dc 0x7363 0x94b4 0x5e3 0x754f 0x9491 0x5f2 0x773c 0x9474 0x5f5 0x7928 0x9456 0x5fe 0x7b14 0x9439 0x607 0x7d01 0x941c 0x60e 0x7eed 0x9402 0x60e 0x80d9 0x93e8 0x617 0x82c6 0x93cd 0x621 0x84b2 0x93af 0x627 0x869e 0x938d 0x627 0x888b 0x9366 0x626 0x8a77 0x933b 0x610 0x8c63 0x930d 0x5f7 0x8e50 0x92e6 0x5e5 0x903c 0x92be 0x5ee 0x9228 0x929c 0x5f5 0x9415 0x9276 0x5f9 0x9601 0x9245 0x607 0x97ed 0x920d 0x60e 0x99d9 0x91cc 0x622 0x9bc6 0x9191 0x627 0x9db2 0x9153 0x629 0x9f9e 0x910a 0x639 0xa18b 0x90b8 0x642 0xa377 0x9086 0x652 0xa563 0x9062 0x66b 0xa750 0x9044 0x691 0xa93c 0x9029 0x6bd 0xab28 0x900d 0x6e9 0xad15 0x8fe5 0x724 0xaf01 0x8f94 0x77a 0xb0ed 0x8e75 0x80c 0xb2da 0x8c83 0x8ca 0xb4c6 0x89e6 0xa10 0xb6b2 0x861e 0xcfa 0xb89f 0x803c 0x15a8 0xba8b 0x7fb2 0x1678 0xbc77 0x7fb2 0x1678 0xbe64 0x7fb2 0x1678>;
			battery0_profile_t3_num = <0x64>;
			battery0_profile_t3_col = <0x03>;
			battery0_profile_t3 = <0x00 0xa9a6 0x946 0x1ec 0xa91f 0x946 0x3d9 0xa8a0 0x97a 0x5c5 0xa824 0x9c2 0x7b1 0xa7a7 0x9e9 0x99e 0xa729 0x9f6 0xb8a 0xa6ae 0x9fb 0xd76 0xa633 0xa08 0xf63 0xa5b8 0xa14 0x114f 0xa53d 0xa1c 0x133b 0xa4c2 0xa1c 0x1528 0xa446 0xa20 0x1714 0xa3ce 0xa28 0x1900 0xa357 0xa28 0x1aec 0xa2e1 0xa2b 0x1cd9 0xa26b 0xa39 0x1ec5 0xa1f5 0xa41 0x20b1 0xa180 0xa41 0x229e 0xa10e 0xa42 0x248a 0xa09a 0xa52 0x2676 0xa02c 0xa5b 0x2863 0x9fbf 0xa6c 0x2a4f 0x9f53 0xa73 0x2c3b 0x9ee7 0xa73 0x2e28 0x9e82 0xa84 0x3014 0x9e1f 0xa9c 0x3200 0x9dbd 0xab5 0x33ed 0x9d54 0xacd 0x35d9 0x9cee 0xad6 0x37c5 0x9c92 0xae7 0x39b2 0x9c34 0xb0b 0x3b9e 0x9bd6 0xb23 0x3d8a 0x9b72 0xb3c 0x3f77 0x9b06 0xb46 0x4163 0x9a8e 0xb3c 0x434f 0x9a08 0xb23 0x453b 0x997b 0xaef 0x4728 0x98f6 0xaad 0x4914 0x988c 0xa64 0x4b00 0x982d 0xa47 0x4ced 0x97d9 0xa39 0x4ed9 0x978e 0xa28 0x50c5 0x9749 0xa35 0x52b2 0x9709 0xa3d 0x549e 0x96ce 0xa4a 0x568a 0x9695 0xa5d 0x5877 0x9660 0xa6e 0x5a63 0x962b 0xa86 0x5c4f 0x95f8 0xa97 0x5e3c 0x95c7 0xaac 0x6028 0x9596 0xaba 0x6214 0x9568 0xac5 0x6401 0x9540 0xadd 0x65ed 0x9519 0xaf5 0x67d9 0x94f1 0xb0e 0x69c6 0x94c9 0xb27 0x6bb2 0x94a4 0xb41 0x6d9e 0x9487 0xb5e 0x6f8a 0x9469 0xb84 0x7177 0x944c 0xba2 0x7363 0x942e 0xbbb 0x754f 0x9411 0xbd4 0x773c 0x93f8 0xbec 0x7928 0x93e1 0xc06 0x7b14 0x93cd 0xc25 0x7d01 0x93ba 0xc47 0x7eed 0x93a6 0xc69 0x80d9 0x9390 0xc95 0x82c6 0x9372 0xcb2 0x84b2 0x934c 0xccc 0x869e 0x9325 0xcf9 0x888b 0x92fc 0xd17 0x8a77 0x92cc 0xd45 0x8c63 0x92a3 0xd7a 0x8e50 0x9273 0xdc2 0x903c 0x9240 0xe1e 0x9228 0x91fe 0xe80 0x9415 0x91b9 0xee4 0x9601 0x9174 0xf5a 0x97ed 0x912e 0xfd6 0x99d9 0x90d9 0x1067 0x9bc6 0x9085 0x1112 0x9db2 0x9048 0x11eb 0x9f9e 0x9019 0x12df 0xa18b 0x8fee 0x141d 0xa377 0x8fc5 0x1592 0xa563 0x8f95 0x1762 0xa750 0x8f58 0x19f5 0xa93c 0x8ece 0x1dbf 0xab28 0x8d90 0x2416 0xad15 0x8b3e 0x2f2c 0xaf01 0x8674 0x3c3a 0xb0ed 0x7b8e 0x43b0 0xb2da 0x7b8e 0x43b0 0xb4c6 0x7b8e 0x43b0 0xb6b2 0x7b8e 0x43b0 0xb89f 0x7b8e 0x43b0 0xba8b 0x7b8e 0x43b0 0xbc77 0x7b8e 0x43b0 0xbe64 0x7b8e 0x43b0>;
			battery0_profile_t4_num = <0x64>;
			battery0_profile_t4_col = <0x03>;
			battery0_profile_t4 = <0x00 0xa726 0x139c 0x1ec 0xa660 0x139c 0x3d9 0xa5b7 0x144e 0x5c5 0xa521 0x1516 0x7b1 0xa493 0x1589 0x99e 0xa409 0x15da 0xb8a 0xa380 0x161c 0xd76 0xa2fd 0x1645 0xf63 0xa282 0x1670 0x114f 0xa206 0x16a1 0x133b 0xa18c 0x16d2 0x1528 0xa116 0x1704 0x1714 0xa0a0 0x1720 0x1900 0xa02a 0x174d 0x1aec 0x9fba 0x176a 0x1cd9 0x9f47 0x1797 0x1ec5 0x9ed7 0x17a2 0x20b1 0x9e6a 0x17c8 0x229e 0x9e02 0x17fa 0x248a 0x9d99 0x1838 0x2676 0x9d32 0x1865 0x2863 0x9cca 0x188b 0x2a4f 0x9c63 0x18af 0x2c3b 0x9c00 0x18d6 0x2e28 0x9b9e 0x1908 0x3014 0x9b33 0x1936 0x3200 0x9ac2 0x193b 0x33ed 0x9a47 0x1942 0x35d9 0x99c0 0x192d 0x37c5 0x993a 0x18fc 0x39b2 0x98be 0x18db 0x3b9e 0x9850 0x18c1 0x3d8a 0x97ef 0x18c2 0x3f77 0x9797 0x18db 0x4163 0x9749 0x18f3 0x434f 0x96fe 0x18fd 0x453b 0x96bc 0x191c 0x4728 0x967f 0x1946 0x4914 0x9644 0x196e 0x4b00 0x960c 0x197a 0x4ced 0x95d9 0x1998 0x4ed9 0x95a8 0x19c3 0x50c5 0x9577 0x19f2 0x52b2 0x9547 0x1a1e 0x549e 0x951f 0x1a4a 0x568a 0x94f8 0x1a83 0x5877 0x94d1 0x1ab9 0x5a63 0x94ad 0x1ae9 0x5c4f 0x9491 0x1b16 0x5e3c 0x9476 0x1b53 0x6028 0x945b 0x1b9d 0x6214 0x9444 0x1bf4 0x6401 0x942e 0x1c4b 0x65ed 0x941a 0x1ca0 0x67d9 0x9406 0x1cf4 0x69c6 0x93f0 0x1d47 0x6bb2 0x93db 0x1da5 0x6d9e 0x93c7 0x1e11 0x6f8a 0x93b4 0x1e8b 0x7177 0x9397 0x1f06 0x7363 0x9382 0x1f86 0x754f 0x935d 0x2017 0x773c 0x933e 0x20b0 0x7928 0x9318 0x215a 0x7b14 0x92e9 0x2209 0x7d01 0x92c0 0x22e6 0x7eed 0x9289 0x23c6 0x80d9 0x9255 0x24c3 0x82c6 0x9214 0x25e1 0x84b2 0x91d0 0x2701 0x869e 0x918b 0x284c 0x888b 0x9146 0x29d6 0x8a77 0x90fa 0x2ba1 0x8c63 0x90ab 0x2da7 0x8e50 0x9057 0x3015 0x903c 0x900d 0x32f2 0x9228 0x8fd3 0x3648 0x9415 0x8fa1 0x3a40 0x9601 0x8f6f 0x3e5b 0x97ed 0x8f3e 0x43f8 0x99d9 0x8ef6 0x4b2f 0x9bc6 0x8e85 0x5866 0x9db2 0x8d64 0x65d3 0x9f9e 0x8250 0x6361 0xa18b 0x8250 0x6361 0xa377 0x8250 0x6361 0xa563 0x8250 0x6361 0xa750 0x8250 0x6361 0xa93c 0x8250 0x6361 0xab28 0x8250 0x6361 0xad15 0x8250 0x6361 0xaf01 0x8250 0x6361 0xb0ed 0x8250 0x6361 0xb2da 0x8250 0x6361 0xb4c6 0x8250 0x6361 0xb6b2 0x8250 0x6361 0xb89f 0x8250 0x6361 0xba8b 0x8250 0x6361 0xbc77 0x8250 0x6361 0xbe64 0x8250 0x6361>;
			battery0_profile_t5_num = <0x64>;
			battery0_profile_t5_col = <0x03>;
			battery0_profile_t5 = <0x00 0xa3e8 0x1ee0 0x1ec 0xa2d8 0x1ee0 0x3d9 0xa1dd 0x2061 0x5c5 0xa110 0x2224 0x7b1 0xa062 0x23a7 0x99e 0x9fca 0x24c3 0xb8a 0x9f3b 0x256b 0xd76 0x9eb2 0x25d7 0xf63 0x9e31 0x2626 0x114f 0x9db6 0x2686 0x133b 0x9d3b 0x26e8 0x1528 0x9cc5 0x2735 0x1714 0x9c4f 0x276b 0x1900 0x9bd9 0x279c 0x1aec 0x9b68 0x27cd 0x1cd9 0x9af5 0x27fd 0x1ec5 0x9a85 0x281e 0x20b1 0x9a13 0x2846 0x229e 0x999d 0x2867 0x248a 0x9925 0x2880 0x2676 0x98b4 0x2887 0x2863 0x9846 0x2887 0x2a4f 0x97e3 0x288f 0x2c3b 0x9789 0x289d 0x2e28 0x9735 0x28a9 0x3014 0x96ec 0x28d6 0x3200 0x96a8 0x28fd 0x33ed 0x9669 0x292e 0x35d9 0x962f 0x296c 0x37c5 0x95f6 0x299e 0x39b2 0x95c4 0x29df 0x3b9e 0x9593 0x2a25 0x3d8a 0x9565 0x2a63 0x3f77 0x953f 0x2a95 0x4163 0x951b 0x2ae5 0x434f 0x94fa 0x2b41 0x453b 0x94db 0x2ba4 0x4728 0x94bd 0x2bff 0x4914 0x94a0 0x2c5b 0x4b00 0x9488 0x2cd5 0x4ced 0x9471 0x2d49 0x4ed9 0x945b 0x2db3 0x50c5 0x9441 0x2e2e 0x52b2 0x942a 0x2eac 0x549e 0x9416 0x2f2d 0x568a 0x93f9 0x2fc0 0x5877 0x93e2 0x3060 0x5a63 0x93c8 0x3100 0x5c4f 0x93aa 0x319d 0x5e3c 0x938d 0x324e 0x6028 0x936f 0x330d 0x6214 0x9352 0x33c8 0x6401 0x932b 0x349d 0x65ed 0x9304 0x3569 0x67d9 0x92dc 0x364a 0x69c6 0x92ac 0x3741 0x6bb2 0x927b 0x383b 0x6d9e 0x9249 0x3938 0x6f8a 0x9210 0x3a56 0x7177 0x91d5 0x3bc4 0x7363 0x9193 0x3d35 0x754f 0x914e 0x3ec0 0x773c 0x9101 0x4085 0x7928 0x90ba 0x4260 0x7b14 0x9075 0x449c 0x7d01 0x9038 0x4741 0x7eed 0x9002 0x4a48 0x80d9 0x8fd0 0x4dcf 0x82c6 0x8f99 0x5240 0x84b2 0x8f52 0x58fe 0x869e 0x8ef7 0x62a0 0x888b 0x8e4c 0x670c 0x8a77 0x8cb2 0x64f3 0x8c63 0x87e3 0x5f47 0x8e50 0x8738 0x5db5 0x903c 0x8729 0x5c9b 0x9228 0x8719 0x5b82 0x9415 0x870a 0x5a68 0x9601 0x86fb 0x594e 0x97ed 0x86eb 0x5834 0x99d9 0x86dc 0x571a 0x9bc6 0x86cd 0x5600 0x9db2 0x86bd 0x54e7 0x9f9e 0x83f4 0x5b44 0xa18b 0x83f4 0x5b44 0xa377 0x83f4 0x5b44 0xa563 0x83f4 0x5b44 0xa750 0x83f4 0x5b44 0xa93c 0x83f4 0x5b44 0xab28 0x83f4 0x5b44 0xad15 0x83f4 0x5b44 0xaf01 0x83f4 0x5b44 0xb0ed 0x83f4 0x5b44 0xb2da 0x83f4 0x5b44 0xb4c6 0x83f4 0x5b44 0xb6b2 0x83f4 0x5b44 0xb89f 0x83f4 0x5b44 0xba8b 0x83f4 0x5b44 0xbc77 0x83f4 0x5b44 0xbe64 0x83f4 0x5b44>;
			battery1_profile_t0_num = <0x64>;
			battery1_profile_t0_col = <0x03>;
			battery1_profile_t0 = <0x00 0xabe0 0x226 0x1e5 0xab62 0x226 0x3c9 0xaaed 0x226 0x5ae 0xaa79 0x226 0x792 0xaa0e 0x23c 0x977 0xa99b 0x23f 0xb5b 0xa926 0x22b 0xd40 0xa8ba 0x23a 0xf24 0xa846 0x23f 0x1109 0xa7d1 0x23f 0x12ed 0xa75d 0x251 0x14d2 0xa6e2 0x247 0x16b7 0xa66a 0x23f 0x189b 0xa5f6 0x24e 0x1a80 0xa57c 0x249 0x1c64 0xa503 0x23f 0x1e49 0xa48f 0x23f 0x202d 0xa41b 0x24b 0x2212 0xa3a6 0x258 0x23f6 0xa331 0x258 0x25db 0xa2bb 0x263 0x27bf 0xa247 0x267 0x29a4 0xa1d6 0x258 0x2b89 0xa169 0x258 0x2d6d 0xa0f7 0x25f 0x2f52 0xa08a 0x26a 0x3136 0xa018 0x258 0x331b 0x9faf 0x25d 0x34ff 0x9f4d 0x271 0x36e4 0x9ee4 0x271 0x38c8 0x9e82 0x271 0x3aad 0x9e18 0x271 0x3c91 0x9db7 0x271 0x3e76 0x9d56 0x272 0x405b 0x9cff 0x28a 0x423f 0x9c9e 0x28a 0x4424 0x9c47 0x2a1 0x4608 0x9bef 0x2a3 0x47ed 0x9b98 0x2a3 0x49d1 0x9b41 0x2cd 0x4bb6 0x9aea 0x2d5 0x4d9a 0x9a83 0x2d5 0x4f7f 0x99fb 0x29d 0x5163 0x996e 0x278 0x5348 0x98f4 0x260 0x552d 0x9894 0x258 0x5711 0x9843 0x248 0x58f6 0x97f5 0x23f 0x5ada 0x97b3 0x24d 0x5cbf 0x9774 0x24a 0x5ea3 0x9735 0x23f 0x6088 0x96fb 0x23f 0x626c 0x96c5 0x23f 0x6451 0x9695 0x24a 0x6635 0x9661 0x24e 0x681a 0x962a 0x248 0x69ff 0x95fa 0x258 0x6be3 0x95c9 0x251 0x6dc8 0x959b 0x246 0x6fac 0x9575 0x258 0x7191 0x954e 0x25d 0x7375 0x9527 0x26d 0x755a 0x9500 0x258 0x773e 0x94db 0x25b 0x7923 0x94bd 0x271 0x7b07 0x9496 0x272 0x7cec 0x9479 0x28a 0x7ed1 0x945c 0x28a 0x80b5 0x9436 0x28a 0x829a 0x9418 0x2a1 0x847e 0x93e0 0x276 0x8663 0x938c 0x246 0x8847 0x933c 0x23f 0x8a2c 0x9307 0x254 0x8c10 0x92d6 0x258 0x8df5 0x92a6 0x258 0x8fd9 0x926e 0x246 0x91be 0x9242 0x251 0x93a3 0x9215 0x258 0x9587 0x91f1 0x258 0x976c 0x91ce 0x258 0x9950 0x91a7 0x266 0x9b35 0x9175 0x263 0x9d19 0x913b 0x258 0x9efe 0x90fc 0x24c 0xa0e2 0x90c1 0x256 0xa2c7 0x9088 0x266 0xa4ab 0x903d 0x24e 0xa690 0x8ffb 0x248 0xa875 0x8fe5 0x258 0xaa59 0x8fdb 0x258 0xac3e 0x8fcf 0x258 0xae22 0x8fbb 0x25e 0xb007 0x8fa1 0x277 0xb1eb 0x8f57 0x285 0xb3d0 0x8e86 0x275 0xb5b4 0x8cfc 0x291 0xb799 0x8afc 0x2bc 0xb97d 0x884b 0x2c1 0xbb62 0x84bc 0x307>;
			battery1_profile_t1_num = <0x64>;
			battery1_profile_t1_col = <0x03>;
			battery1_profile_t1 = <0x00 0xab7c 0x339 0x1e5 0xaafe 0x339 0x3c9 0xaa89 0x339 0x5ae 0xaa1e 0x350 0x792 0xa9b4 0x33c 0x977 0xa941 0x339 0xb5b 0xa8d4 0x339 0xd40 0xa85a 0x325 0xf24 0xa7eb 0x346 0x1109 0xa772 0x340 0x12ed 0xa6fb 0x339 0x14d2 0xa687 0x339 0x16b7 0xa60c 0x339 0x189b 0xa594 0x348 0x1a80 0xa51a 0x344 0x1c64 0xa4a2 0x339 0x1e49 0xa42d 0x339 0x202d 0xa3b9 0x345 0x2212 0xa344 0x352 0x23f6 0xa2ce 0x352 0x25db 0xa25a 0x352 0x27bf 0xa1e5 0x349 0x29a4 0xa175 0x342 0x2b89 0xa10a 0x35a 0x2d6d 0xa09f 0x372 0x2f52 0xa035 0x37e 0x3136 0x9fca 0x370 0x331b 0x9f60 0x37f 0x34ff 0x9ef7 0x373 0x36e4 0x9e96 0x39d 0x38c8 0x9e34 0x39d 0x3aad 0x9dca 0x3a0 0x3c91 0x9d73 0x3cf 0x3e76 0x9d12 0x3cf 0x405b 0x9cb1 0x3cf 0x423f 0x9c5a 0x3e6 0x4424 0x9c02 0x3ff 0x4608 0x9ba2 0x3eb 0x47ed 0x9b4a 0x3fd 0x49d1 0x9aeb 0x415 0x4bb6 0x9a7a 0x406 0x4d9a 0x99f7 0x3c9 0x4f7f 0x996f 0x380 0x5163 0x98fc 0x35a 0x5348 0x9898 0x341 0x552d 0x9844 0x339 0x5711 0x97f6 0x32a 0x58f6 0x97ae 0x320 0x5ada 0x9770 0x320 0x5cbf 0x9736 0x320 0x5ea3 0x96fc 0x320 0x6088 0x96c6 0x320 0x626c 0x9695 0x32a 0x6451 0x9661 0x32f 0x6635 0x962d 0x329 0x681a 0x9603 0x339 0x69ff 0x95d3 0x331 0x6be3 0x95a5 0x327 0x6dc8 0x957e 0x339 0x6fac 0x955a 0x33e 0x7191 0x953b 0x352 0x7375 0x9514 0x352 0x755a 0x94ee 0x352 0x773e 0x94d1 0x354 0x7923 0x94b4 0x36b 0x7b07 0x948d 0x36c 0x7cec 0x947a 0x384 0x7ed1 0x9453 0x36c 0x80b5 0x9436 0x36b 0x829a 0x9419 0x36b 0x847e 0x93ea 0x355 0x8663 0x93ba 0x33d 0x8847 0x9389 0x339 0x8a2c 0x9361 0x339 0x8c10 0x9332 0x326 0x8df5 0x9302 0x320 0x8fd9 0x92d8 0x320 0x91be 0x92b2 0x320 0x93a3 0x9291 0x330 0x9587 0x926e 0x32a 0x976c 0x9247 0x32e 0x9950 0x921b 0x339 0x9b35 0x91e6 0x339 0x9d19 0x91ac 0x32d 0x9efe 0x9176 0x32b 0xa0e2 0x913d 0x339 0xa2c7 0x90f5 0x339 0xa4ab 0x90ab 0x339 0xa690 0x9078 0x339 0xa875 0x9067 0x339 0xaa59 0x905b 0x339 0xac3e 0x904a 0x345 0xae22 0x9039 0x36b 0xb007 0x900b 0x36b 0xb1eb 0x8f9c 0x36b 0xb3d0 0x8e65 0x371 0xb5b4 0x8c99 0x3a4 0xb799 0x8a3c 0x3ee 0xb97d 0x86fe 0x455 0xbb62 0x81e2 0x578>;
			battery1_profile_t2_num = <0x64>;
			battery1_profile_t2_col = <0x03>;
			battery1_profile_t2 = <0x00 0xaa78 0x5aa 0x1e5 0xa9e7 0x5aa 0x3c9 0xa95f 0x5c1 0x5ae 0xa8e9 0x5f0 0x792 0xa875 0x5f5 0x977 0xa7f8 0x5e0 0xb5b 0xa77a 0x5dc 0xd40 0xa704 0x5dc 0xf24 0xa688 0x5dc 0x1109 0xa611 0x5ee 0x12ed 0xa596 0x5f5 0x14d2 0xa51f 0x5f5 0x16b7 0xa4a4 0x5e5 0x189b 0xa42b 0x5dc 0x1a80 0xa3b6 0x5eb 0x1c64 0xa341 0x5f5 0x1e49 0xa2cd 0x5f5 0x202d 0xa259 0x5f5 0x2212 0xa1e9 0x601 0x23f6 0xa17a 0x60e 0x25db 0xa10a 0x618 0x27bf 0xa09b 0x61e 0x29a4 0xa02b 0x60e 0x2b89 0x9fc0 0x60e 0x2d6d 0x9f58 0x61c 0x2f52 0x9ef5 0x646 0x3136 0x9e8a 0x659 0x331b 0x9e21 0x662 0x34ff 0x9dc1 0x68b 0x36e4 0x9d60 0x68b 0x38c8 0x9cff 0x68b 0x3aad 0x9c9e 0x68d 0x3c91 0x9c3d 0x6a5 0x3e76 0x9be6 0x6bd 0x405b 0x9b85 0x6bd 0x423f 0x9b24 0x6d4 0x4424 0x9ab1 0x6a9 0x4608 0x9a3d 0x68e 0x47ed 0x99b8 0x64c 0x49d1 0x9936 0x602 0x4bb6 0x98d0 0x5e1 0x4d9a 0x986f 0x5c9 0x4f7f 0x9815 0x5b0 0x5163 0x97cc 0x5aa 0x5348 0x9788 0x5aa 0x552d 0x974b 0x5aa 0x5711 0x970b 0x5aa 0x58f6 0x96cd 0x5aa 0x5ada 0x9698 0x5aa 0x5cbf 0x9662 0x5aa 0x5ea3 0x9632 0x5b6 0x6088 0x9607 0x5c3 0x626c 0x95d6 0x5c3 0x6451 0x95a6 0x5c3 0x6635 0x9579 0x5cc 0x681a 0x9552 0x5e5 0x69ff 0x952c 0x5f5 0x6be3 0x9505 0x5f5 0x6dc8 0x94de 0x5f5 0x6fac 0x94b9 0x5fb 0x7191 0x949c 0x613 0x7375 0x947f 0x62b 0x755a 0x9462 0x640 0x773e 0x9443 0x63d 0x7923 0x941e 0x627 0x7b07 0x9400 0x627 0x7cec 0x93e4 0x627 0x7ed1 0x93d0 0x640 0x80b5 0x93aa 0x610 0x829a 0x938c 0x625 0x847e 0x936f 0x627 0x8663 0x9349 0x627 0x8847 0x9322 0x63c 0x8a2c 0x92f3 0x62b 0x8c10 0x92ca 0x627 0x8df5 0x92ab 0x64d 0x8fd9 0x9287 0x67e 0x91be 0x9259 0x69d 0x93a3 0x9222 0x6c5 0x9587 0x91e8 0x6f6 0x976c 0x91ae 0x726 0x9950 0x9173 0x757 0x9b35 0x9134 0x795 0x9d19 0x90e1 0x7c4 0x9efe 0x9093 0x7f4 0xa0e2 0x906b 0x854 0xa2c7 0x9058 0x8c2 0xa4ab 0x9044 0x937 0xa690 0x902d 0x9d1 0xa875 0x900d 0xa95 0xaa59 0x8fcf 0xb9a 0xac3e 0x8f28 0xcbd 0xae22 0x8dc1 0xe2d 0xb007 0x8baf 0x10b6 0xb1eb 0x88ef 0x14a1 0xb3d0 0x84ec 0x1c0c 0xb5b4 0x7fb2 0x28a0 0xb799 0x7fb2 0x28a0 0xb97d 0x7fb2 0x28a0 0xbb62 0x7fb2 0x28a0>;
			battery1_profile_t3_num = <0x64>;
			battery1_profile_t3_col = <0x03>;
			battery1_profile_t3 = <0x00 0xa942 0x8fc 0x1e5 0xa863 0x8fc 0x3c9 0xa7c6 0x971 0x5ae 0xa734 0x9a6 0x792 0xa6b4 0x9d7 0x977 0xa636 0x9dd 0xb5b 0xa5b8 0xa06 0xd40 0xa53a 0xa0f 0xf24 0xa4ba 0xa0f 0x1109 0xa443 0xa22 0x12ed 0xa3c8 0xa28 0x14d2 0xa350 0xa39 0x16b7 0xa2dc 0xa41 0x189b 0xa268 0xa50 0x1a80 0xa1f4 0xa5a 0x1c64 0xa185 0xa68 0x1e49 0xa115 0xa73 0x202d 0xa0a6 0xa7f 0x2212 0xa036 0xa8c 0x23f6 0x9fcb 0xaac 0x25db 0x9f66 0xad7 0x27bf 0x9efb 0xaea 0x29a4 0x9e91 0xb09 0x2b89 0x9e26 0xb11 0x2d6d 0x9dbe 0xb29 0x2f52 0x9d5b 0xb3b 0x3136 0x9cf2 0xb40 0x331b 0x9c91 0xb54 0x34ff 0x9c31 0xb58 0x36e4 0x9bd0 0xb6d 0x38c8 0x9b6e 0xb6b 0x3aad 0x9b03 0xb52 0x3c91 0x9a8e 0xb39 0x3e76 0x9a10 0xb09 0x405b 0x9992 0xad9 0x423f 0x9914 0xaa8 0x4424 0x98a8 0xa8e 0x4608 0x9846 0xa8c 0x47ed 0x97f6 0xa8c 0x49d1 0x97a9 0xaa0 0x4bb6 0x975b 0xa91 0x4d9a 0x971d 0xa9f 0x4f7f 0x96db 0xab7 0x5163 0x969f 0xacf 0x5348 0x9664 0xad7 0x552d 0x9630 0xae7 0x5711 0x95f9 0xaff 0x58f6 0x95c5 0xb18 0x5ada 0x959a 0xb3e 0x5cbf 0x956e 0xb54 0x5ea3 0x953d 0xb60 0x6088 0x9511 0xb84 0x626c 0x94eb 0xbaa 0x6451 0x94c4 0xbc2 0x6635 0x94a1 0xbe4 0x681a 0x9480 0xc0c 0x69ff 0x945d 0xc24 0x6be3 0x943d 0xc35 0x6dc8 0x941b 0xc41 0x6fac 0x9408 0xc72 0x7191 0x93f4 0xca2 0x7375 0x93e1 0xcd7 0x755a 0x93ce 0xd1f 0x773e 0x93b9 0xd66 0x7923 0x939c 0xd98 0x7b07 0x937f 0xde2 0x7cec 0x9362 0xe5b 0x7ed1 0x9345 0xeec 0x80b5 0x931e 0xf7e 0x829a 0x92ef 0xff8 0x847e 0x92c7 0x10c9 0x8663 0x9298 0x1179 0x8847 0x9267 0x124b 0x8a2c 0x9237 0x1325 0x8c10 0x91f7 0x13ff 0x8df5 0x91bb 0x14d9 0x8fd9 0x917a 0x15c5 0x91be 0x9136 0x16c8 0x93a3 0x90f2 0x17e2 0x9587 0x90a2 0x1904 0x976c 0x9050 0x1a48 0x9950 0x9018 0x1bd5 0x9b35 0x8ff6 0x1dcb 0x9d19 0x8fd4 0x2043 0x9efe 0x8fad 0x238c 0xa0e2 0x8f7e 0x2851 0xa2c7 0x8f30 0x2fad 0xa4ab 0x8e8e 0x3a43 0xa690 0x8d43 0x48b7 0xa875 0x8b36 0x59cd 0xaa59 0x8827 0x568c 0xac3e 0x84c6 0x4e84 0xae22 0x84c6 0x4e84 0xb007 0x84c6 0x4e84 0xb1eb 0x84c6 0x4e84 0xb3d0 0x84c6 0x4e84 0xb5b4 0x84c6 0x4e84 0xb799 0x84c6 0x4e84 0xb97d 0x84c6 0x4e84 0xbb62 0x84c6 0x4e84>;
			battery1_profile_t4_num = <0x64>;
			battery1_profile_t4_col = <0x03>;
			battery1_profile_t4 = <0x00 0xa708 0x1194 0x1e5 0xa5d2 0x1194 0x3c9 0xa4cb 0x12dc 0x5ae 0xa3e9 0x13d5 0x792 0xa32d 0x14b1 0x977 0xa28c 0x1564 0xb5b 0xa1f9 0x15cf 0xd40 0xa16f 0x161c 0xf24 0xa0f0 0x1665 0x1109 0xa079 0x169b 0x12ed 0xa005 0x16dd 0x14d2 0x9f8a 0x1715 0x16b7 0x9f12 0x1745 0x189b 0x9e98 0x1757 0x1a80 0x9e20 0x1774 0x1c64 0x9da6 0x1789 0x1e49 0x9d28 0x1789 0x202d 0x9caa 0x1789 0x2212 0x9c2c 0x177d 0x23f6 0x9bae 0x1765 0x25db 0x9b30 0x1757 0x27bf 0x9ab5 0x1757 0x29a4 0x9a3e 0x1746 0x2b89 0x99c6 0x172d 0x2d6d 0x995b 0x173e 0x2f52 0x98f3 0x1744 0x3136 0x9895 0x175c 0x331b 0x983f 0x1779 0x34ff 0x97ee 0x17a2 0x36e4 0x979a 0x17ad 0x38c8 0x9756 0x17f3 0x3aad 0x9712 0x1823 0x3c91 0x96ce 0x1852 0x3e76 0x968b 0x186b 0x405b 0x9651 0x189b 0x423f 0x9617 0x18e4 0x4424 0x95dc 0x1915 0x4608 0x95a2 0x1946 0x47ed 0x9570 0x198d 0x49d1 0x953f 0x19d6 0x4bb6 0x950f 0x1a0a 0x4d9a 0x94de 0x1a4e 0x4f7f 0x94b6 0x1a97 0x5163 0x948f 0x1ace 0x5348 0x946f 0x1b21 0x552d 0x9452 0x1b71 0x5711 0x9435 0x1bca 0x58f6 0x941e 0x1c49 0x5ada 0x9405 0x1ce9 0x5cbf 0x93e8 0x1d92 0x5ea3 0x93cb 0x1e56 0x6088 0x93ad 0x1f3c 0x626c 0x938c 0x2039 0x6451 0x9365 0x214f 0x6635 0x933e 0x227b 0x681a 0x9314 0x23bf 0x69ff 0x92e4 0x2512 0x6be3 0x92b0 0x2665 0x6dc8 0x9279 0x27bf 0x6fac 0x9246 0x2925 0x7191 0x920c 0x2a78 0x7375 0x91d2 0x2bcb 0x755a 0x9196 0x2d1e 0x773e 0x9153 0x2e71 0x7923 0x9118 0x2fc5 0x7b07 0x90d5 0x311b 0x7cec 0x9099 0x32a5 0x7ed1 0x9055 0x3411 0x80b5 0x901b 0x3594 0x829a 0x8feb 0x3747 0x847e 0x8fba 0x3929 0x8663 0x8f78 0x3ba9 0x8847 0x8f12 0x3e0c 0x8a2c 0x8e76 0x4093 0x8c10 0x8d72 0x4321 0x8df5 0x8bc8 0x46cd 0x8fd9 0x8948 0x4d46 0x91be 0x85ca 0x509c 0x93a3 0x846c 0x4d58 0x9587 0x846c 0x4d58 0x976c 0x846c 0x4d58 0x9950 0x846c 0x4d58 0x9b35 0x846c 0x4d58 0x9d19 0x846c 0x4d58 0x9efe 0x846c 0x4d58 0xa0e2 0x846c 0x4d58 0xa2c7 0x846c 0x4d58 0xa4ab 0x846c 0x4d58 0xa690 0x846c 0x4d58 0xa875 0x846c 0x4d58 0xaa59 0x846c 0x4d58 0xac3e 0x846c 0x4d58 0xae22 0x846c 0x4d58 0xb007 0x846c 0x4d58 0xb1eb 0x846c 0x4d58 0xb3d0 0x846c 0x4d58 0xb5b4 0x846c 0x4d58 0xb799 0x846c 0x4d58 0xb97d 0x846c 0x4d58 0xbb62 0x846c 0x4d58>;
			battery1_profile_t5_num = <0x64>;
			battery1_profile_t5_col = <0x03>;
			battery1_profile_t5 = <0x00 0xa172 0x21ca 0x1e5 0xa03c 0x21ca 0x3c9 0x9f3e 0x2443 0x5ae 0x9e54 0x2605 0x792 0x9d74 0x29c7 0x977 0x9caf 0x2b71 0xb5b 0x9bf5 0x2c9b 0xd40 0x9b55 0x2d83 0xf24 0x9ac1 0x2e4b 0x1109 0x9a37 0x2ed6 0x12ed 0x99bd 0x2f3e 0x14d2 0x9949 0x2f9f 0x16b7 0x98d5 0x2fe0 0x189b 0x9866 0x3011 0x1a80 0x97fc 0x3041 0x1c64 0x979c 0x3072 0x1e49 0x9744 0x30a3 0x202d 0x96f0 0x3105 0x2212 0x96a3 0x318b 0x23f6 0x965a 0x31f9 0x25db 0x961a 0x325a 0x27bf 0x95e0 0x32bb 0x29a4 0x95a6 0x3325 0x2b89 0x956f 0x339e 0x2d6d 0x953e 0x3409 0x2f52 0x9513 0x346a 0x3136 0x94f3 0x350f 0x331b 0x94ce 0x35ad 0x34ff 0x94b1 0x366b 0x36e4 0x9492 0x3714 0x38c8 0x946d 0x37c6 0x3aad 0x944f 0x38bb 0x3c91 0x9427 0x39c6 0x3e76 0x93f7 0x3aea 0x405b 0x93c7 0x3c3d 0x423f 0x9396 0x3dc0 0x4424 0x9366 0x3f44 0x4608 0x9323 0x40c8 0x47ed 0x92e8 0x4261 0x49d1 0x929d 0x43fd 0x4bb6 0x9258 0x4584 0x4d9a 0x9214 0x4708 0x4f7f 0x91c9 0x4879 0x5163 0x917b 0x49af 0x5348 0x912e 0x4ac1 0x552d 0x90e7 0x4bcc 0x5711 0x90a3 0x4c89 0x58f6 0x9065 0x4d29 0x5ada 0x9025 0x4e18 0x5cbf 0x8fe1 0x4ef9 0x5ea3 0x8f8a 0x4f8a 0x6088 0x8f0c 0x501a 0x626c 0x8e47 0x50c4 0x6451 0x8cfd 0x516d 0x6635 0x8af2 0x528f 0x681a 0x87eb 0x5378 0x69ff 0x8408 0x4c45 0x6be3 0x8408 0x4c45 0x6dc8 0x8408 0x4c45 0x6fac 0x8408 0x4c45 0x7191 0x8408 0x4c45 0x7375 0x8408 0x4c45 0x755a 0x8408 0x4c45 0x773e 0x8408 0x4c45 0x7923 0x8408 0x4c45 0x7b07 0x8408 0x4c45 0x7cec 0x8408 0x4c45 0x7ed1 0x8408 0x4c45 0x80b5 0x8408 0x4c45 0x829a 0x8408 0x4c45 0x847e 0x8408 0x4c45 0x8663 0x8408 0x4c45 0x8847 0x8408 0x4c45 0x8a2c 0x8408 0x4c45 0x8c10 0x8408 0x4c45 0x8df5 0x8408 0x4c45 0x8fd9 0x8408 0x4c45 0x91be 0x8408 0x4c45 0x93a3 0x8408 0x4c45 0x9587 0x8408 0x4c45 0x976c 0x8408 0x4c45 0x9950 0x8408 0x4c45 0x9b35 0x8408 0x4c45 0x9d19 0x8408 0x4c45 0x9efe 0x8408 0x4c45 0xa0e2 0x8408 0x4c45 0xa2c7 0x8408 0x4c45 0xa4ab 0x8408 0x4c45 0xa690 0x8408 0x4c45 0xa875 0x8408 0x4c45 0xaa59 0x8408 0x4c45 0xac3e 0x8408 0x4c45 0xae22 0x8408 0x4c45 0xb007 0x8408 0x4c45 0xb1eb 0x8408 0x4c45 0xb3d0 0x8408 0x4c45 0xb5b4 0x8408 0x4c45 0xb799 0x8408 0x4c45 0xb97d 0x8408 0x4c45 0xbb62 0x8408 0x4c45>;
			battery2_profile_t0_num = <0x64>;
			battery2_profile_t0_col = <0x03>;
			battery2_profile_t0 = <0x00 0xabea 0x226 0x1ea 0xab74 0x226 0x3d5 0xab08 0x23e 0x5bf 0xaa9c 0x23f 0x7a9 0xaa31 0x23f 0x994 0xa9c5 0x23f 0xb7e 0xa959 0x23f 0xd68 0xa8ed 0x255 0xf52 0xa879 0x243 0x113d 0xa80b 0x254 0x1327 0xa797 0x244 0x1511 0xa722 0x23f 0x16fc 0xa6ac 0x23f 0x18e6 0xa636 0x252 0x1ad0 0xa5c1 0x258 0x1cbb 0xa54b 0x258 0x1ea5 0xa4ce 0x247 0x208f 0xa45c 0x250 0x2279 0xa3e3 0x248 0x2464 0xa369 0x23f 0x264e 0xa2f8 0x24f 0x2838 0xa286 0x258 0x2a23 0xa217 0x258 0x2c0d 0xa1a5 0x258 0x2df7 0xa135 0x258 0x2fe2 0xa0c9 0x258 0x31cc 0xa05d 0x258 0x33b6 0x9ff1 0x264 0x35a0 0x9f86 0x265 0x378b 0x9f1a 0x258 0x3975 0x9eb2 0x258 0x3b5f 0x9e50 0x262 0x3d4a 0x9dee 0x271 0x3f34 0x9d90 0x27b 0x411e 0x9d34 0x28a 0x4309 0x9cd5 0x293 0x44f3 0x9c7d 0x2a3 0x46dd 0x9c25 0x2a3 0x48c8 0x9bcd 0x2aa 0x4ab2 0x9b74 0x2c3 0x4c9c 0x9b1a 0x2db 0x4e86 0x9aac 0x2e3 0x5071 0x9a17 0x2ad 0x525b 0x9980 0x268 0x5445 0x9907 0x243 0x5630 0x98b0 0x258 0x581a 0x9862 0x255 0x5a04 0x9814 0x23f 0x5bef 0x97d1 0x241 0x5dd9 0x9796 0x258 0x5fc3 0x975b 0x258 0x61ad 0x9720 0x257 0x6398 0x96e5 0x23f 0x6582 0x96b4 0x258 0x676c 0x967a 0x240 0x6957 0x9648 0x23f 0x6b41 0x9616 0x23f 0x6d2b 0x95e5 0x23f 0x6f16 0x95bd 0x256 0x7100 0x958d 0x242 0x72ea 0x9565 0x255 0x74d4 0x953e 0x258 0x76bf 0x9516 0x258 0x78a9 0x94f7 0x26c 0x7a93 0x94d2 0x271 0x7c7e 0x94b3 0x284 0x7e68 0x948e 0x277 0x8052 0x946e 0x284 0x823d 0x9450 0x29c 0x8427 0x9425 0x291 0x8611 0x93df 0x268 0x87fc 0x938a 0x247 0x89e6 0x933f 0x23f 0x8bd0 0x9307 0x23f 0x8dba 0x92d6 0x23f 0x8fa5 0x92ab 0x24e 0x918f 0x9278 0x24a 0x9379 0x9248 0x24d 0x9564 0x921c 0x24b 0x974e 0x91f5 0x24c 0x9938 0x91ce 0x24c 0x9b23 0x919d 0x23f 0x9d0d 0x9163 0x23f 0x9ef7 0x9122 0x24a 0xa0e1 0x90e7 0x258 0xa2cc 0x90a9 0x258 0xa4b6 0x905d 0x24f 0xa6a0 0x9012 0x248 0xa88b 0x8fef 0x258 0xaa75 0x8fe2 0x250 0xac5f 0x8fd1 0x246 0xae4a 0x8fc7 0x25f 0xb034 0x8fb8 0x277 0xb21e 0x8f8c 0x28a 0xb408 0x8f01 0x284 0xb5f3 0x8db8 0x276 0xb7dd 0x8bd7 0x294 0xb9c7 0x8958 0x2c5 0xbbb2 0x85cf 0x30e 0xbd9c 0x8160 0x3b6>;
			battery2_profile_t1_num = <0x64>;
			battery2_profile_t1_col = <0x03>;
			battery2_profile_t1 = <0x00 0xab86 0x339 0x1ea 0xab10 0x339 0x3d5 0xaaa4 0x339 0x5bf 0xaa42 0x351 0x7a9 0xa9d7 0x352 0x994 0xa96b 0x352 0xb7e 0xa8ff 0x352 0xd68 0xa88a 0x352 0xf52 0xa81d 0x352 0x113d 0xa7a9 0x352 0x1327 0xa733 0x352 0x1511 0xa6be 0x352 0x16fc 0xa640 0x33f 0x18e6 0xa5c8 0x34c 0x1ad0 0xa553 0x352 0x1cbb 0xa4dd 0x340 0x1ea5 0xa467 0x34a 0x208f 0xa3eb 0x341 0x2279 0xa372 0x349 0x2464 0xa301 0x362 0x264e 0xa28e 0x36b 0x2838 0xa218 0x35c 0x2a23 0xa1a9 0x361 0x2c0d 0xa137 0x35d 0x2df7 0xa0c7 0x360 0x2fe2 0xa05b 0x36b 0x31cc 0x9fef 0x36b 0x33b6 0x9f88 0x377 0x35a0 0x9f22 0x384 0x378b 0x9eba 0x38f 0x3975 0x9e58 0x39d 0x3b5f 0x9df6 0x3a7 0x3d4a 0x9d94 0x3b6 0x3f34 0x9d36 0x3c0 0x411e 0x9cde 0x3d8 0x4309 0x9c82 0x3e8 0x44f3 0x9c23 0x3f8 0x46dd 0x9bcb 0x422 0x48c8 0x9b70 0x433 0x4ab2 0x9b0b 0x433 0x4c9c 0x9a95 0x41b 0x4e86 0x9a00 0x3b9 0x5071 0x996b 0x366 0x525b 0x98f9 0x34d 0x5445 0x989b 0x339 0x5630 0x984c 0x335 0x581a 0x9800 0x323 0x5a04 0x97c4 0x339 0x5bef 0x9781 0x337 0x5dd9 0x9746 0x320 0x5fc3 0x970b 0x321 0x61ad 0x96da 0x338 0x6398 0x969f 0x320 0x6582 0x966e 0x339 0x676c 0x963d 0x321 0x6957 0x9616 0x350 0x6b41 0x95e4 0x33a 0x6d2b 0x95bd 0x350 0x6f16 0x958c 0x33b 0x7100 0x956d 0x34f 0x72ea 0x9547 0x352 0x74d4 0x9520 0x352 0x76bf 0x94f8 0x352 0x78a9 0x94d9 0x366 0x7a93 0x94bc 0x36b 0x7c7e 0x949f 0x37e 0x7e68 0x947a 0x371 0x8052 0x945a 0x37e 0x823d 0x943c 0x384 0x8427 0x9418 0x384 0x8611 0x93e3 0x362 0x87fc 0x93af 0x341 0x89e6 0x9384 0x349 0x8bd0 0x9357 0x342 0x8dba 0x9326 0x339 0x8fa5 0x92f5 0x339 0x918f 0x92c9 0x339 0x9379 0x92a8 0x347 0x9564 0x9285 0x345 0x974e 0x925e 0x339 0x9938 0x9232 0x345 0x9b23 0x91f7 0x346 0x9d0d 0x91b7 0x339 0x9ef7 0x9180 0x344 0xa0e1 0x9147 0x348 0xa2cc 0x90fb 0x339 0xa4b6 0x90aa 0x339 0xa6a0 0x9077 0x339 0xa88b 0x9067 0x341 0xaa75 0x905d 0x352 0xac5f 0x9050 0x352 0xae4a 0x903c 0x360 0xb034 0x9021 0x38a 0xb21e 0x8fc9 0x397 0xb408 0x8ec2 0x38a 0xb5f3 0x8cf4 0x3a8 0xb7dd 0x8a91 0x3de 0xb9c7 0x8741 0x447 0xbbb2 0x8198 0xa47 0xbd9c 0x7436 0x24d1>;
			battery2_profile_t2_num = <0x64>;
			battery2_profile_t2_col = <0x03>;
			battery2_profile_t2 = <0x00 0xaa96 0x5c3 0x1ea 0xaa0d 0x5c3 0x3d5 0xa997 0x5f3 0x5bf 0xa921 0x60d 0x7a9 0xa8ab 0x60e 0x994 0xa83d 0x625 0xb7e 0xa7c8 0x627 0xd68 0xa752 0x627 0xf52 0xa6d4 0x627 0x113d 0xa65d 0x627 0x1327 0xa5e7 0x627 0x1511 0xa571 0x627 0x16fc 0xa4fc 0x627 0x18e6 0xa47e 0x627 0x1ad0 0xa406 0x627 0x1cbb 0xa38f 0x627 0x1ea5 0xa318 0x615 0x208f 0xa2aa 0x632 0x2279 0xa237 0x640 0x2464 0xa1c8 0x640 0x264e 0xa156 0x630 0x2838 0xa0e6 0x637 0x2a23 0xa07b 0x640 0x2c0d 0xa00f 0x640 0x2df7 0x9fa3 0x640 0x2fe2 0x9f3b 0x65c 0x31cc 0x9ed8 0x680 0x33b6 0x9e76 0x698 0x35a0 0x9e0f 0x697 0x378b 0x9da8 0x697 0x3975 0x9d4b 0x6b0 0x3b5f 0x9cee 0x6c8 0x3d4a 0x9c90 0x6d6 0x3f34 0x9c38 0x6eb 0x411e 0x9bdb 0x708 0x4309 0x9b74 0x708 0x44f3 0x9b04 0x6fe 0x46dd 0x9a87 0x6dd 0x48c8 0x99fb 0x69b 0x4ab2 0x996e 0x641 0x4c9c 0x98f8 0x60e 0x4e86 0x9898 0x607 0x5071 0x9843 0x5ee 0x525b 0x97f7 0x5dc 0x5445 0x97b4 0x5e2 0x5630 0x9776 0x5f5 0x581a 0x9734 0x5f5 0x5a04 0x96fb 0x5fa 0x5bef 0x96c8 0x60e 0x5dd9 0x968f 0x60e 0x5fc3 0x965d 0x60e 0x61ad 0x962c 0x611 0x6398 0x95fb 0x627 0x6582 0x95cb 0x627 0x676c 0x95a3 0x627 0x6957 0x9572 0x628 0x6b41 0x954b 0x641 0x6d2b 0x9524 0x659 0x6f16 0x9506 0x672 0x7100 0x94df 0x672 0x72ea 0x94b8 0x672 0x74d4 0x949a 0x689 0x76bf 0x947c 0x68b 0x78a9 0x945f 0x68b 0x7a93 0x9441 0x68b 0x7c7e 0x9424 0x6a1 0x7e68 0x9406 0x6a4 0x8052 0x93e9 0x6b9 0x823d 0x93cb 0x6bd 0x8427 0x93a6 0x6a9 0x8611 0x937f 0x6a4 0x87fc 0x9350 0x691 0x89e6 0x9326 0x69e 0x8bd0 0x92f8 0x692 0x8dba 0x92cd 0x68b 0x8fa5 0x92ad 0x69d 0x918f 0x9289 0x6b5 0x9379 0x9254 0x6bd 0x9564 0x9219 0x6bd 0x974e 0x91d8 0x6cd 0x9938 0x91a0 0x6f4 0x9b23 0x9163 0x708 0x9d0d 0x9118 0x716 0x9ef7 0x90c3 0x72f 0xa0e1 0x908b 0x756 0xa2cc 0x906e 0x779 0xa4b6 0x905b 0x7ab 0xa6a0 0x9047 0x7e9 0xa88b 0x902a 0x831 0xaa75 0x9008 0x8aa 0xac5f 0x8fb5 0x932 0xae4a 0x8ecc 0x9ad 0xb034 0x8d1a 0xa59 0xb21e 0x8ab9 0xba6 0xb408 0x876e 0xe02 0xb5f3 0x81fd 0x1497 0xb7dd 0x7cd8 0x1ccf 0xb9c7 0x7cd8 0x1ccf 0xbbb2 0x7cd8 0x1ccf 0xbd9c 0x7cd8 0x1ccf>;
			battery2_profile_t3_num = <0x64>;
			battery2_profile_t3_col = <0x03>;
			battery2_profile_t3 = <0x00 0xa99c 0x992 0x1ea 0xa8eb 0x992 0x3d5 0xa858 0xa0a 0x5bf 0xa7d8 0xa3e 0x7a9 0xa758 0xa6f 0x994 0xa6d9 0xa73 0xb7e 0xa662 0xa89 0xd68 0xa5e4 0xa8c 0xf52 0xa56d 0xaa1 0x113d 0xa4ef 0xaba 0x1327 0xa477 0xabe 0x1511 0xa3fa 0xabe 0x16fc 0xa382 0xabe 0x18e6 0xa30c 0xad1 0x1ad0 0xa297 0xae9 0x1cbb 0xa228 0xb02 0x1ea5 0xa1b5 0xb09 0x208f 0xa146 0xb1a 0x2279 0xa0d4 0xb22 0x2464 0xa063 0xb32 0x264e 0x9ff6 0xb4b 0x2838 0x9f8b 0xb54 0x2a23 0x9f25 0xb63 0x2c0d 0x9ebd 0xb7b 0x2df7 0x9e57 0xb94 0x2fe2 0x9def 0xb9f 0x31cc 0x9d88 0xbb9 0x33b6 0x9d2b 0xbea 0x35a0 0x9cce 0xc0f 0x378b 0x9c6c 0xc1c 0x3975 0x9c0a 0xc32 0x3b5f 0x9ba8 0xc4e 0x3d4a 0x9b3e 0xc4e 0x3f34 0x9ac1 0xc32 0x411e 0x9a34 0xbe8 0x4309 0x99a4 0xb9e 0x44f3 0x9921 0xb65 0x46dd 0x98b2 0xb54 0x48c8 0x9855 0xb54 0x4ab2 0x9807 0xb54 0x4c9c 0x97bb 0xb5a 0x4e86 0x9776 0xb6d 0x5071 0x9734 0xb72 0x525b 0x96f9 0xb8b 0x5445 0x96be 0xba3 0x5630 0x9685 0xbbc 0x581a 0x9652 0xbd1 0x5a04 0x9619 0xbd4 0x5bef 0x95e8 0xbec 0x5dd9 0x95b7 0xc08 0x5fc3 0x958f 0xc4e 0x61ad 0x955f 0xc4f 0x6398 0x9538 0xc67 0x6582 0x9510 0xc80 0x676c 0x94e9 0xc98 0x6957 0x94c2 0xcb1 0x6b41 0x94a3 0xce2 0x6d2b 0x947d 0xcfb 0x6f16 0x945f 0xd2b 0x7100 0x9441 0xd2f 0x72ea 0x9424 0xd5b 0x74d4 0x940f 0xd8c 0x76bf 0x93f3 0xd93 0x78a9 0x93de 0xdbc 0x7a93 0x93ca 0xded 0x7c7e 0x93b6 0xe1e 0x7e68 0x939b 0xe3c 0x8052 0x937e 0xe67 0x823d 0x9359 0xe86 0x8427 0x932b 0xe9f 0x8611 0x9301 0xed9 0x87fc 0x92d3 0xf12 0x89e6 0x92a8 0xf53 0x8bd0 0x927b 0xfac 0x8dba 0x9244 0x100e 0x8fa5 0x9203 0x1071 0x918f 0x91b9 0x10d3 0x9379 0x9175 0x115e 0x9564 0x9130 0x11fc 0x974e 0x90dc 0x12a9 0x9938 0x9089 0x1379 0x9b23 0x9049 0x1456 0x9d0d 0x9021 0x155f 0x9ef7 0x8fff 0x16b3 0xa0e1 0x8fdc 0x1861 0xa2cc 0x8fb6 0x1a9e 0xa4b6 0x8f77 0x1d91 0xa6a0 0x8ef7 0x21bb 0xa88b 0x8ddd 0x2855 0xaa75 0x8be7 0x3723 0xac5f 0x894c 0x520e 0xae4a 0x8582 0x5049 0xb034 0x8462 0x4d26 0xb21e 0x8462 0x4d26 0xb408 0x8462 0x4d26 0xb5f3 0x8462 0x4d26 0xb7dd 0x8462 0x4d26 0xb9c7 0x8462 0x4d26 0xbbb2 0x8462 0x4d26 0xbd9c 0x8462 0x4d26>;
			battery2_profile_t4_num = <0x64>;
			battery2_profile_t4_col = <0x03>;
			battery2_profile_t4 = <0x00 0xa6c2 0x13ec 0x1ea 0xa5b9 0x13ec 0x3d5 0xa4f4 0x150c 0x5bf 0xa44c 0x15bd 0x7a9 0xa3b8 0x1623 0x994 0xa32b 0x1687 0xb7e 0xa2ab 0x16d3 0xd68 0xa222 0x16f0 0xf52 0xa1aa 0x171e 0x113d 0xa135 0x174f 0x1327 0xa0bf 0x1780 0x1511 0xa049 0x1789 0x16fc 0x9fd4 0x179d 0x18e6 0x9f66 0x17c8 0x1ad0 0x9efa 0x17e7 0x1cbb 0x9e8c 0x1812 0x1ea5 0x9e20 0x1831 0x208f 0x9db4 0x184a 0x2279 0x9d4f 0x1874 0x2464 0x9ce6 0x1894 0x264e 0x9c81 0x18ac 0x2838 0x9c18 0x18c5 0x2a23 0x9bb3 0x18ed 0x2c0d 0x9b4b 0x190f 0x2df7 0x9ad9 0x190b 0x2fe2 0x9a5c 0x1900 0x31cc 0x99d6 0x18d6 0x33b6 0x9952 0x18b5 0x35a0 0x98d8 0x18a8 0x378b 0x986c 0x189c 0x3975 0x980a 0x189c 0x3b5f 0x97b1 0x189c 0x3d4a 0x9767 0x18b2 0x3f34 0x9723 0x18d8 0x411e 0x96dd 0x18f1 0x4309 0x969c 0x190a 0x44f3 0x9661 0x192c 0x46dd 0x962a 0x195d 0x48c8 0x95f9 0x198e 0x4ab2 0x95c8 0x19bf 0x4c9c 0x9597 0x19f0 0x4e86 0x9569 0x1a21 0x5071 0x953f 0x1a45 0x525b 0x9510 0x1a51 0x5445 0x94e9 0x1a7d 0x5630 0x94c3 0x1aa1 0x581a 0x94a6 0x1ae5 0x5a04 0x9488 0x1b1b 0x5bef 0x946d 0x1b65 0x5dd9 0x9458 0x1bae 0x5fc3 0x943b 0x1bfb 0x61ad 0x9428 0x1c5a 0x6398 0x9414 0x1ca6 0x6582 0x9401 0x1d08 0x676c 0x93ec 0x1d69 0x6957 0x93cf 0x1db5 0x6b41 0x93bb 0x1e18 0x6d2b 0x939e 0x1e92 0x6f16 0x9380 0x1ef5 0x7100 0x9363 0x1f6f 0x72ea 0x9345 0x2019 0x74d4 0x931f 0x20ae 0x76bf 0x92ee 0x212a 0x78a9 0x92c6 0x21e8 0x7a93 0x9295 0x2299 0x7c7e 0x925b 0x235b 0x7e68 0x9220 0x2434 0x8052 0x91dd 0x2511 0x823d 0x91a1 0x2617 0x8427 0x915e 0x2725 0x8611 0x9111 0x2880 0x87fc 0x90bb 0x29f0 0x89e6 0x906b 0x2b85 0x8bd0 0x902b 0x2d4a 0x8dba 0x8ff6 0x2f8f 0x8fa5 0x8fcc 0x3284 0x918f 0x8fa5 0x3614 0x9379 0x8f77 0x3aca 0x9564 0x8f3f 0x41bb 0x974e 0x8edf 0x4d04 0x9938 0x8e12 0x605e 0x9b23 0x8c87 0x61b6 0x9d0d 0x8a00 0x5b43 0x9ef7 0x8619 0x53cf 0xa0e1 0x84c6 0x4ee8 0xa2cc 0x84c6 0x4ee8 0xa4b6 0x84c6 0x4ee8 0xa6a0 0x84c6 0x4ee8 0xa88b 0x84c6 0x4ee8 0xaa75 0x84c6 0x4ee8 0xac5f 0x84c6 0x4ee8 0xae4a 0x84c6 0x4ee8 0xb034 0x84c6 0x4ee8 0xb21e 0x84c6 0x4ee8 0xb408 0x84c6 0x4ee8 0xb5f3 0x84c6 0x4ee8 0xb7dd 0x84c6 0x4ee8 0xb9c7 0x84c6 0x4ee8 0xbbb2 0x84c6 0x4ee8 0xbd9c 0x84c6 0x4ee8>;
			battery2_profile_t5_num = <0x64>;
			battery2_profile_t5_col = <0x03>;
			battery2_profile_t5 = <0x00 0xa38e 0x1e5f 0x1ea 0xa27b 0x1e5f 0x3d5 0xa186 0x2028 0x5bf 0xa0a3 0x2211 0x7a9 0x9ff0 0x23cd 0x994 0x9f4f 0x2716 0xb7e 0x9ec3 0x27f9 0xd68 0x9e3a 0x2862 0xf52 0x9dba 0x28c4 0x113d 0x9d3a 0x2911 0x1327 0x9cc3 0x295b 0x1511 0x9c4d 0x29a5 0x16fc 0x9bd8 0x29ee 0x18e6 0x9b6a 0x2a38 0x1ad0 0x9af6 0x2a5c 0x1cbb 0x9a7f 0x2a87 0x1ea5 0x9a08 0x2a70 0x208f 0x9993 0x2a50 0x2279 0x9924 0x2a9f 0x2464 0x98b8 0x2ad7 0x264e 0x984c 0x2aef 0x2838 0x97ed 0x2af8 0x2a23 0x9795 0x2b17 0x2c0d 0x9742 0x2b48 0x2df7 0x96fa 0x2b79 0x2fe2 0x96b4 0x2b8e 0x31cc 0x9675 0x2bb8 0x33b6 0x963a 0x2be6 0x35a0 0x9604 0x2c0c 0x378b 0x95d8 0x2c56 0x3975 0x95ac 0x2c94 0x3b5f 0x9580 0x2cb8 0x3d4a 0x9558 0x2cf4 0x3f34 0x9531 0x2d48 0x411e 0x950e 0x2da1 0x4309 0x94f0 0x2df5 0x44f3 0x94d3 0x2e57 0x46dd 0x94b5 0x2eb9 0x48c8 0x9498 0x2f13 0x4ab2 0x947e 0x2f6c 0x4c9c 0x9467 0x2fdf 0x4e86 0x9449 0x3041 0x5071 0x942f 0x30b1 0x525b 0x9419 0x313e 0x5445 0x93fd 0x31bf 0x5630 0x93e5 0x324e 0x581a 0x93c0 0x32b9 0x5a04 0x93a2 0x330b 0x5bef 0x9385 0x33ec 0x5dd9 0x9366 0x34da 0x5fc3 0x933f 0x359b 0x61ad 0x9318 0x3649 0x6398 0x92ef 0x3712 0x6582 0x92be 0x3803 0x676c 0x928d 0x38c8 0x6957 0x925b 0x3994 0x6b41 0x9220 0x3aa2 0x6d2b 0x91e5 0x3bc9 0x6f16 0x91a0 0x3d07 0x7100 0x915c 0x3e2e 0x72ea 0x9117 0x3f84 0x74d4 0x90d2 0x410a 0x76bf 0x908e 0x4292 0x78a9 0x905b 0x44b7 0x7a93 0x9029 0x4739 0x7c7e 0x9001 0x4a7d 0x7e68 0x8fd1 0x4eda 0x8052 0x8f98 0x5567 0x823d 0x8f44 0x611c 0x8427 0x8ecb 0x6731 0x8611 0x8de2 0x64eb 0x87fc 0x8bfe 0x6044 0x89e6 0x883c 0x56c8 0x8bd0 0x84a8 0x4dd5 0x8dba 0x84a8 0x4dd5 0x8fa5 0x84a8 0x4dd5 0x918f 0x84a8 0x4dd5 0x9379 0x84a8 0x4dd5 0x9564 0x84a8 0x4dd5 0x974e 0x84a8 0x4dd5 0x9938 0x84a8 0x4dd5 0x9b23 0x84a8 0x4dd5 0x9d0d 0x84a8 0x4dd5 0x9ef7 0x84a8 0x4dd5 0xa0e1 0x84a8 0x4dd5 0xa2cc 0x84a8 0x4dd5 0xa4b6 0x84a8 0x4dd5 0xa6a0 0x84a8 0x4dd5 0xa88b 0x84a8 0x4dd5 0xaa75 0x84a8 0x4dd5 0xac5f 0x84a8 0x4dd5 0xae4a 0x84a8 0x4dd5 0xb034 0x84a8 0x4dd5 0xb21e 0x84a8 0x4dd5 0xb408 0x84a8 0x4dd5 0xb5f3 0x84a8 0x4dd5 0xb7dd 0x84a8 0x4dd5 0xb9c7 0x84a8 0x4dd5 0xbbb2 0x84a8 0x4dd5 0xbd9c 0x84a8 0x4dd5>;
			battery3_profile_t0_num = <0x64>;
			battery3_profile_t0_col = <0x03>;
			battery3_profile_t0 = <0x00 0xabe0 0x226 0x1e5 0xab62 0x226 0x3c9 0xaaed 0x226 0x5ae 0xaa79 0x226 0x792 0xaa0e 0x23c 0x977 0xa99b 0x23f 0xb5b 0xa926 0x22b 0xd40 0xa8ba 0x23a 0xf24 0xa846 0x23f 0x1109 0xa7d1 0x23f 0x12ed 0xa75d 0x251 0x14d2 0xa6e2 0x247 0x16b7 0xa66a 0x23f 0x189b 0xa5f6 0x24e 0x1a80 0xa57c 0x249 0x1c64 0xa503 0x23f 0x1e49 0xa48f 0x23f 0x202d 0xa41b 0x24b 0x2212 0xa3a6 0x258 0x23f6 0xa331 0x258 0x25db 0xa2bb 0x263 0x27bf 0xa247 0x267 0x29a4 0xa1d6 0x258 0x2b89 0xa169 0x258 0x2d6d 0xa0f7 0x25f 0x2f52 0xa08a 0x26a 0x3136 0xa018 0x258 0x331b 0x9faf 0x25d 0x34ff 0x9f4d 0x271 0x36e4 0x9ee4 0x271 0x38c8 0x9e82 0x271 0x3aad 0x9e18 0x271 0x3c91 0x9db7 0x271 0x3e76 0x9d56 0x272 0x405b 0x9cff 0x28a 0x423f 0x9c9e 0x28a 0x4424 0x9c47 0x2a1 0x4608 0x9bef 0x2a3 0x47ed 0x9b98 0x2a3 0x49d1 0x9b41 0x2cd 0x4bb6 0x9aea 0x2d5 0x4d9a 0x9a83 0x2d5 0x4f7f 0x99fb 0x29d 0x5163 0x996e 0x278 0x5348 0x98f4 0x260 0x552d 0x9894 0x258 0x5711 0x9843 0x248 0x58f6 0x97f5 0x23f 0x5ada 0x97b3 0x24d 0x5cbf 0x9774 0x24a 0x5ea3 0x9735 0x23f 0x6088 0x96fb 0x23f 0x626c 0x96c5 0x23f 0x6451 0x9695 0x24a 0x6635 0x9661 0x24e 0x681a 0x962a 0x248 0x69ff 0x95fa 0x258 0x6be3 0x95c9 0x251 0x6dc8 0x959b 0x246 0x6fac 0x9575 0x258 0x7191 0x954e 0x25d 0x7375 0x9527 0x26d 0x755a 0x9500 0x258 0x773e 0x94db 0x25b 0x7923 0x94bd 0x271 0x7b07 0x9496 0x272 0x7cec 0x9479 0x28a 0x7ed1 0x945c 0x28a 0x80b5 0x9436 0x28a 0x829a 0x9418 0x2a1 0x847e 0x93e0 0x276 0x8663 0x938c 0x246 0x8847 0x933c 0x23f 0x8a2c 0x9307 0x254 0x8c10 0x92d6 0x258 0x8df5 0x92a6 0x258 0x8fd9 0x926e 0x246 0x91be 0x9242 0x251 0x93a3 0x9215 0x258 0x9587 0x91f1 0x258 0x976c 0x91ce 0x258 0x9950 0x91a7 0x266 0x9b35 0x9175 0x263 0x9d19 0x913b 0x258 0x9efe 0x90fc 0x24c 0xa0e2 0x90c1 0x256 0xa2c7 0x9088 0x266 0xa4ab 0x903d 0x24e 0xa690 0x8ffb 0x248 0xa875 0x8fe5 0x258 0xaa59 0x8fdb 0x258 0xac3e 0x8fcf 0x258 0xae22 0x8fbb 0x25e 0xb007 0x8fa1 0x277 0xb1eb 0x8f57 0x285 0xb3d0 0x8e86 0x275 0xb5b4 0x8cfc 0x291 0xb799 0x8afc 0x2bc 0xb97d 0x884b 0x2c1 0xbb62 0x84bc 0x307>;
			battery3_profile_t1_num = <0x64>;
			battery3_profile_t1_col = <0x03>;
			battery3_profile_t1 = <0x00 0xab7c 0x339 0x1e5 0xaafe 0x339 0x3c9 0xaa89 0x339 0x5ae 0xaa1e 0x350 0x792 0xa9b4 0x33c 0x977 0xa941 0x339 0xb5b 0xa8d4 0x339 0xd40 0xa85a 0x325 0xf24 0xa7eb 0x346 0x1109 0xa772 0x340 0x12ed 0xa6fb 0x339 0x14d2 0xa687 0x339 0x16b7 0xa60c 0x339 0x189b 0xa594 0x348 0x1a80 0xa51a 0x344 0x1c64 0xa4a2 0x339 0x1e49 0xa42d 0x339 0x202d 0xa3b9 0x345 0x2212 0xa344 0x352 0x23f6 0xa2ce 0x352 0x25db 0xa25a 0x352 0x27bf 0xa1e5 0x349 0x29a4 0xa175 0x342 0x2b89 0xa10a 0x35a 0x2d6d 0xa09f 0x372 0x2f52 0xa035 0x37e 0x3136 0x9fca 0x370 0x331b 0x9f60 0x37f 0x34ff 0x9ef7 0x373 0x36e4 0x9e96 0x39d 0x38c8 0x9e34 0x39d 0x3aad 0x9dca 0x3a0 0x3c91 0x9d73 0x3cf 0x3e76 0x9d12 0x3cf 0x405b 0x9cb1 0x3cf 0x423f 0x9c5a 0x3e6 0x4424 0x9c02 0x3ff 0x4608 0x9ba2 0x3eb 0x47ed 0x9b4a 0x3fd 0x49d1 0x9aeb 0x415 0x4bb6 0x9a7a 0x406 0x4d9a 0x99f7 0x3c9 0x4f7f 0x996f 0x380 0x5163 0x98fc 0x35a 0x5348 0x9898 0x341 0x552d 0x9844 0x339 0x5711 0x97f6 0x32a 0x58f6 0x97ae 0x320 0x5ada 0x9770 0x320 0x5cbf 0x9736 0x320 0x5ea3 0x96fc 0x320 0x6088 0x96c6 0x320 0x626c 0x9695 0x32a 0x6451 0x9661 0x32f 0x6635 0x962d 0x329 0x681a 0x9603 0x339 0x69ff 0x95d3 0x331 0x6be3 0x95a5 0x327 0x6dc8 0x957e 0x339 0x6fac 0x955a 0x33e 0x7191 0x953b 0x352 0x7375 0x9514 0x352 0x755a 0x94ee 0x352 0x773e 0x94d1 0x354 0x7923 0x94b4 0x36b 0x7b07 0x948d 0x36c 0x7cec 0x947a 0x384 0x7ed1 0x9453 0x36c 0x80b5 0x9436 0x36b 0x829a 0x9419 0x36b 0x847e 0x93ea 0x355 0x8663 0x93ba 0x33d 0x8847 0x9389 0x339 0x8a2c 0x9361 0x339 0x8c10 0x9332 0x326 0x8df5 0x9302 0x320 0x8fd9 0x92d8 0x320 0x91be 0x92b2 0x320 0x93a3 0x9291 0x330 0x9587 0x926e 0x32a 0x976c 0x9247 0x32e 0x9950 0x921b 0x339 0x9b35 0x91e6 0x339 0x9d19 0x91ac 0x32d 0x9efe 0x9176 0x32b 0xa0e2 0x913d 0x339 0xa2c7 0x90f5 0x339 0xa4ab 0x90ab 0x339 0xa690 0x9078 0x339 0xa875 0x9067 0x339 0xaa59 0x905b 0x339 0xac3e 0x904a 0x345 0xae22 0x9039 0x36b 0xb007 0x900b 0x36b 0xb1eb 0x8f9c 0x36b 0xb3d0 0x8e65 0x371 0xb5b4 0x8c99 0x3a4 0xb799 0x8a3c 0x3ee 0xb97d 0x86fe 0x455 0xbb62 0x81e2 0x578>;
			battery3_profile_t2_num = <0x64>;
			battery3_profile_t2_col = <0x03>;
			battery3_profile_t2 = <0x00 0xaa78 0x5aa 0x1e5 0xa9e7 0x5aa 0x3c9 0xa95f 0x5c1 0x5ae 0xa8e9 0x5f0 0x792 0xa875 0x5f5 0x977 0xa7f8 0x5e0 0xb5b 0xa77a 0x5dc 0xd40 0xa704 0x5dc 0xf24 0xa688 0x5dc 0x1109 0xa611 0x5ee 0x12ed 0xa596 0x5f5 0x14d2 0xa51f 0x5f5 0x16b7 0xa4a4 0x5e5 0x189b 0xa42b 0x5dc 0x1a80 0xa3b6 0x5eb 0x1c64 0xa341 0x5f5 0x1e49 0xa2cd 0x5f5 0x202d 0xa259 0x5f5 0x2212 0xa1e9 0x601 0x23f6 0xa17a 0x60e 0x25db 0xa10a 0x618 0x27bf 0xa09b 0x61e 0x29a4 0xa02b 0x60e 0x2b89 0x9fc0 0x60e 0x2d6d 0x9f58 0x61c 0x2f52 0x9ef5 0x646 0x3136 0x9e8a 0x659 0x331b 0x9e21 0x662 0x34ff 0x9dc1 0x68b 0x36e4 0x9d60 0x68b 0x38c8 0x9cff 0x68b 0x3aad 0x9c9e 0x68d 0x3c91 0x9c3d 0x6a5 0x3e76 0x9be6 0x6bd 0x405b 0x9b85 0x6bd 0x423f 0x9b24 0x6d4 0x4424 0x9ab1 0x6a9 0x4608 0x9a3d 0x68e 0x47ed 0x99b8 0x64c 0x49d1 0x9936 0x602 0x4bb6 0x98d0 0x5e1 0x4d9a 0x986f 0x5c9 0x4f7f 0x9815 0x5b0 0x5163 0x97cc 0x5aa 0x5348 0x9788 0x5aa 0x552d 0x974b 0x5aa 0x5711 0x970b 0x5aa 0x58f6 0x96cd 0x5aa 0x5ada 0x9698 0x5aa 0x5cbf 0x9662 0x5aa 0x5ea3 0x9632 0x5b6 0x6088 0x9607 0x5c3 0x626c 0x95d6 0x5c3 0x6451 0x95a6 0x5c3 0x6635 0x9579 0x5cc 0x681a 0x9552 0x5e5 0x69ff 0x952c 0x5f5 0x6be3 0x9505 0x5f5 0x6dc8 0x94de 0x5f5 0x6fac 0x94b9 0x5fb 0x7191 0x949c 0x613 0x7375 0x947f 0x62b 0x755a 0x9462 0x640 0x773e 0x9443 0x63d 0x7923 0x941e 0x627 0x7b07 0x9400 0x627 0x7cec 0x93e4 0x627 0x7ed1 0x93d0 0x640 0x80b5 0x93aa 0x610 0x829a 0x938c 0x625 0x847e 0x936f 0x627 0x8663 0x9349 0x627 0x8847 0x9322 0x63c 0x8a2c 0x92f3 0x62b 0x8c10 0x92ca 0x627 0x8df5 0x92ab 0x64d 0x8fd9 0x9287 0x67e 0x91be 0x9259 0x69d 0x93a3 0x9222 0x6c5 0x9587 0x91e8 0x6f6 0x976c 0x91ae 0x726 0x9950 0x9173 0x757 0x9b35 0x9134 0x795 0x9d19 0x90e1 0x7c4 0x9efe 0x9093 0x7f4 0xa0e2 0x906b 0x854 0xa2c7 0x9058 0x8c2 0xa4ab 0x9044 0x937 0xa690 0x902d 0x9d1 0xa875 0x900d 0xa95 0xaa59 0x8fcf 0xb9a 0xac3e 0x8f28 0xcbd 0xae22 0x8dc1 0xe2d 0xb007 0x8baf 0x10b6 0xb1eb 0x88ef 0x14a1 0xb3d0 0x84ec 0x1c0c 0xb5b4 0x7fb2 0x28a0 0xb799 0x7fb2 0x28a0 0xb97d 0x7fb2 0x28a0 0xbb62 0x7fb2 0x28a0>;
			battery3_profile_t3_num = <0x64>;
			battery3_profile_t3_col = <0x03>;
			battery3_profile_t3 = <0x00 0xa942 0x8fc 0x1e5 0xa863 0x8fc 0x3c9 0xa7c6 0x971 0x5ae 0xa734 0x9a6 0x792 0xa6b4 0x9d7 0x977 0xa636 0x9dd 0xb5b 0xa5b8 0xa06 0xd40 0xa53a 0xa0f 0xf24 0xa4ba 0xa0f 0x1109 0xa443 0xa22 0x12ed 0xa3c8 0xa28 0x14d2 0xa350 0xa39 0x16b7 0xa2dc 0xa41 0x189b 0xa268 0xa50 0x1a80 0xa1f4 0xa5a 0x1c64 0xa185 0xa68 0x1e49 0xa115 0xa73 0x202d 0xa0a6 0xa7f 0x2212 0xa036 0xa8c 0x23f6 0x9fcb 0xaac 0x25db 0x9f66 0xad7 0x27bf 0x9efb 0xaea 0x29a4 0x9e91 0xb09 0x2b89 0x9e26 0xb11 0x2d6d 0x9dbe 0xb29 0x2f52 0x9d5b 0xb3b 0x3136 0x9cf2 0xb40 0x331b 0x9c91 0xb54 0x34ff 0x9c31 0xb58 0x36e4 0x9bd0 0xb6d 0x38c8 0x9b6e 0xb6b 0x3aad 0x9b03 0xb52 0x3c91 0x9a8e 0xb39 0x3e76 0x9a10 0xb09 0x405b 0x9992 0xad9 0x423f 0x9914 0xaa8 0x4424 0x98a8 0xa8e 0x4608 0x9846 0xa8c 0x47ed 0x97f6 0xa8c 0x49d1 0x97a9 0xaa0 0x4bb6 0x975b 0xa91 0x4d9a 0x971d 0xa9f 0x4f7f 0x96db 0xab7 0x5163 0x969f 0xacf 0x5348 0x9664 0xad7 0x552d 0x9630 0xae7 0x5711 0x95f9 0xaff 0x58f6 0x95c5 0xb18 0x5ada 0x959a 0xb3e 0x5cbf 0x956e 0xb54 0x5ea3 0x953d 0xb60 0x6088 0x9511 0xb84 0x626c 0x94eb 0xbaa 0x6451 0x94c4 0xbc2 0x6635 0x94a1 0xbe4 0x681a 0x9480 0xc0c 0x69ff 0x945d 0xc24 0x6be3 0x943d 0xc35 0x6dc8 0x941b 0xc41 0x6fac 0x9408 0xc72 0x7191 0x93f4 0xca2 0x7375 0x93e1 0xcd7 0x755a 0x93ce 0xd1f 0x773e 0x93b9 0xd66 0x7923 0x939c 0xd98 0x7b07 0x937f 0xde2 0x7cec 0x9362 0xe5b 0x7ed1 0x9345 0xeec 0x80b5 0x931e 0xf7e 0x829a 0x92ef 0xff8 0x847e 0x92c7 0x10c9 0x8663 0x9298 0x1179 0x8847 0x9267 0x124b 0x8a2c 0x9237 0x1325 0x8c10 0x91f7 0x13ff 0x8df5 0x91bb 0x14d9 0x8fd9 0x917a 0x15c5 0x91be 0x9136 0x16c8 0x93a3 0x90f2 0x17e2 0x9587 0x90a2 0x1904 0x976c 0x9050 0x1a48 0x9950 0x9018 0x1bd5 0x9b35 0x8ff6 0x1dcb 0x9d19 0x8fd4 0x2043 0x9efe 0x8fad 0x238c 0xa0e2 0x8f7e 0x2851 0xa2c7 0x8f30 0x2fad 0xa4ab 0x8e8e 0x3a43 0xa690 0x8d43 0x48b7 0xa875 0x8b36 0x59cd 0xaa59 0x8827 0x568c 0xac3e 0x84c6 0x4e84 0xae22 0x84c6 0x4e84 0xb007 0x84c6 0x4e84 0xb1eb 0x84c6 0x4e84 0xb3d0 0x84c6 0x4e84 0xb5b4 0x84c6 0x4e84 0xb799 0x84c6 0x4e84 0xb97d 0x84c6 0x4e84 0xbb62 0x84c6 0x4e84>;
			battery3_profile_t4_num = <0x64>;
			battery3_profile_t4_col = <0x03>;
			battery3_profile_t4 = <0x00 0xa708 0x1194 0x1e5 0xa5d2 0x1194 0x3c9 0xa4cb 0x12dc 0x5ae 0xa3e9 0x13d5 0x792 0xa32d 0x14b1 0x977 0xa28c 0x1564 0xb5b 0xa1f9 0x15cf 0xd40 0xa16f 0x161c 0xf24 0xa0f0 0x1665 0x1109 0xa079 0x169b 0x12ed 0xa005 0x16dd 0x14d2 0x9f8a 0x1715 0x16b7 0x9f12 0x1745 0x189b 0x9e98 0x1757 0x1a80 0x9e20 0x1774 0x1c64 0x9da6 0x1789 0x1e49 0x9d28 0x1789 0x202d 0x9caa 0x1789 0x2212 0x9c2c 0x177d 0x23f6 0x9bae 0x1765 0x25db 0x9b30 0x1757 0x27bf 0x9ab5 0x1757 0x29a4 0x9a3e 0x1746 0x2b89 0x99c6 0x172d 0x2d6d 0x995b 0x173e 0x2f52 0x98f3 0x1744 0x3136 0x9895 0x175c 0x331b 0x983f 0x1779 0x34ff 0x97ee 0x17a2 0x36e4 0x979a 0x17ad 0x38c8 0x9756 0x17f3 0x3aad 0x9712 0x1823 0x3c91 0x96ce 0x1852 0x3e76 0x968b 0x186b 0x405b 0x9651 0x189b 0x423f 0x9617 0x18e4 0x4424 0x95dc 0x1915 0x4608 0x95a2 0x1946 0x47ed 0x9570 0x198d 0x49d1 0x953f 0x19d6 0x4bb6 0x950f 0x1a0a 0x4d9a 0x94de 0x1a4e 0x4f7f 0x94b6 0x1a97 0x5163 0x948f 0x1ace 0x5348 0x946f 0x1b21 0x552d 0x9452 0x1b71 0x5711 0x9435 0x1bca 0x58f6 0x941e 0x1c49 0x5ada 0x9405 0x1ce9 0x5cbf 0x93e8 0x1d92 0x5ea3 0x93cb 0x1e56 0x6088 0x93ad 0x1f3c 0x626c 0x938c 0x2039 0x6451 0x9365 0x214f 0x6635 0x933e 0x227b 0x681a 0x9314 0x23bf 0x69ff 0x92e4 0x2512 0x6be3 0x92b0 0x2665 0x6dc8 0x9279 0x27bf 0x6fac 0x9246 0x2925 0x7191 0x920c 0x2a78 0x7375 0x91d2 0x2bcb 0x755a 0x9196 0x2d1e 0x773e 0x9153 0x2e71 0x7923 0x9118 0x2fc5 0x7b07 0x90d5 0x311b 0x7cec 0x9099 0x32a5 0x7ed1 0x9055 0x3411 0x80b5 0x901b 0x3594 0x829a 0x8feb 0x3747 0x847e 0x8fba 0x3929 0x8663 0x8f78 0x3ba9 0x8847 0x8f12 0x3e0c 0x8a2c 0x8e76 0x4093 0x8c10 0x8d72 0x4321 0x8df5 0x8bc8 0x46cd 0x8fd9 0x8948 0x4d46 0x91be 0x85ca 0x509c 0x93a3 0x846c 0x4d58 0x9587 0x846c 0x4d58 0x976c 0x846c 0x4d58 0x9950 0x846c 0x4d58 0x9b35 0x846c 0x4d58 0x9d19 0x846c 0x4d58 0x9efe 0x846c 0x4d58 0xa0e2 0x846c 0x4d58 0xa2c7 0x846c 0x4d58 0xa4ab 0x846c 0x4d58 0xa690 0x846c 0x4d58 0xa875 0x846c 0x4d58 0xaa59 0x846c 0x4d58 0xac3e 0x846c 0x4d58 0xae22 0x846c 0x4d58 0xb007 0x846c 0x4d58 0xb1eb 0x846c 0x4d58 0xb3d0 0x846c 0x4d58 0xb5b4 0x846c 0x4d58 0xb799 0x846c 0x4d58 0xb97d 0x846c 0x4d58 0xbb62 0x846c 0x4d58>;
			battery3_profile_t5_num = <0x64>;
			battery3_profile_t5_col = <0x03>;
			battery3_profile_t5 = <0x00 0xa172 0x21ca 0x1e5 0xa03c 0x21ca 0x3c9 0x9f3e 0x2443 0x5ae 0x9e54 0x2605 0x792 0x9d74 0x29c7 0x977 0x9caf 0x2b71 0xb5b 0x9bf5 0x2c9b 0xd40 0x9b55 0x2d83 0xf24 0x9ac1 0x2e4b 0x1109 0x9a37 0x2ed6 0x12ed 0x99bd 0x2f3e 0x14d2 0x9949 0x2f9f 0x16b7 0x98d5 0x2fe0 0x189b 0x9866 0x3011 0x1a80 0x97fc 0x3041 0x1c64 0x979c 0x3072 0x1e49 0x9744 0x30a3 0x202d 0x96f0 0x3105 0x2212 0x96a3 0x318b 0x23f6 0x965a 0x31f9 0x25db 0x961a 0x325a 0x27bf 0x95e0 0x32bb 0x29a4 0x95a6 0x3325 0x2b89 0x956f 0x339e 0x2d6d 0x953e 0x3409 0x2f52 0x9513 0x346a 0x3136 0x94f3 0x350f 0x331b 0x94ce 0x35ad 0x34ff 0x94b1 0x366b 0x36e4 0x9492 0x3714 0x38c8 0x946d 0x37c6 0x3aad 0x944f 0x38bb 0x3c91 0x9427 0x39c6 0x3e76 0x93f7 0x3aea 0x405b 0x93c7 0x3c3d 0x423f 0x9396 0x3dc0 0x4424 0x9366 0x3f44 0x4608 0x9323 0x40c8 0x47ed 0x92e8 0x4261 0x49d1 0x929d 0x43fd 0x4bb6 0x9258 0x4584 0x4d9a 0x9214 0x4708 0x4f7f 0x91c9 0x4879 0x5163 0x917b 0x49af 0x5348 0x912e 0x4ac1 0x552d 0x90e7 0x4bcc 0x5711 0x90a3 0x4c89 0x58f6 0x9065 0x4d29 0x5ada 0x9025 0x4e18 0x5cbf 0x8fe1 0x4ef9 0x5ea3 0x8f8a 0x4f8a 0x6088 0x8f0c 0x501a 0x626c 0x8e47 0x50c4 0x6451 0x8cfd 0x516d 0x6635 0x8af2 0x528f 0x681a 0x87eb 0x5378 0x69ff 0x8408 0x4c45 0x6be3 0x8408 0x4c45 0x6dc8 0x8408 0x4c45 0x6fac 0x8408 0x4c45 0x7191 0x8408 0x4c45 0x7375 0x8408 0x4c45 0x755a 0x8408 0x4c45 0x773e 0x8408 0x4c45 0x7923 0x8408 0x4c45 0x7b07 0x8408 0x4c45 0x7cec 0x8408 0x4c45 0x7ed1 0x8408 0x4c45 0x80b5 0x8408 0x4c45 0x829a 0x8408 0x4c45 0x847e 0x8408 0x4c45 0x8663 0x8408 0x4c45 0x8847 0x8408 0x4c45 0x8a2c 0x8408 0x4c45 0x8c10 0x8408 0x4c45 0x8df5 0x8408 0x4c45 0x8fd9 0x8408 0x4c45 0x91be 0x8408 0x4c45 0x93a3 0x8408 0x4c45 0x9587 0x8408 0x4c45 0x976c 0x8408 0x4c45 0x9950 0x8408 0x4c45 0x9b35 0x8408 0x4c45 0x9d19 0x8408 0x4c45 0x9efe 0x8408 0x4c45 0xa0e2 0x8408 0x4c45 0xa2c7 0x8408 0x4c45 0xa4ab 0x8408 0x4c45 0xa690 0x8408 0x4c45 0xa875 0x8408 0x4c45 0xaa59 0x8408 0x4c45 0xac3e 0x8408 0x4c45 0xae22 0x8408 0x4c45 0xb007 0x8408 0x4c45 0xb1eb 0x8408 0x4c45 0xb3d0 0x8408 0x4c45 0xb5b4 0x8408 0x4c45 0xb799 0x8408 0x4c45 0xb97d 0x8408 0x4c45 0xbb62 0x8408 0x4c45>;
			g_PMIC_MIN_VOL_row = <0x04>;
			g_PMIC_MIN_VOL_col = <0x0a>;
			g_PMIC_MIN_VOL = <0x7fbc 0x7fbc 0x7fbc 0x7fbc 0x7fbc 0x7fbc 0x7fbc 0x7fbc 0x7fbc 0x7fbc 0x7fbc 0x7fbc 0x7dc8 0x7dc8 0x7dc8 0x7dc8 0x7918 0x7918 0x7918 0x7918 0x7b0c 0x7b0c 0x7b0c 0x7b0c 0x7918 0x7918 0x7918 0x7918 0x7918 0x7918 0x7918 0x7918 0x7918 0x7918 0x7918 0x7918 0x7918 0x7918 0x7918 0x79e0>;
			g_PON_SYS_IBOOT_row = <0x04>;
			g_PON_SYS_IBOOT_col = <0x0a>;
			g_PON_SYS_IBOOT = <0x1388 0x1388 0x1388 0x1388 0x1388 0x1388 0x1388 0x1388 0x1388 0x1388 0x1388 0x1388 0x1388 0x1388 0x1388 0x1388 0x1388 0x1388 0x1388 0x1388 0x1388 0x1388 0x1388 0x1388 0x1388 0x1388 0x1388 0x1388 0x1388 0x1388 0x1388 0x1388 0x1388 0x1388 0x1388 0x1388 0x1388 0x1388 0x1388 0x1388>;
			g_QMAX_SYS_VOL_row = <0x04>;
			g_QMAX_SYS_VOL_col = <0x0a>;
			g_QMAX_SYS_VOL = <0x8340 0x8340 0x8340 0x8340 0x8340 0x8340 0x8340 0x8340 0x8340 0x8340 0x8340 0x8340 0x8340 0x8340 0x8340 0x8340 0x8340 0x8340 0x8340 0x8340 0x7ef4 0x7ef4 0x7ef4 0x7ef4 0x8020 0x8020 0x8020 0x8020 0x8020 0x8020 0x8020 0x8020 0x8020 0x8020 0x8020 0x8020 0x8020 0x8020 0x8020 0x8020>;
			g_FG_PSEUDO100_row = <0x04>;
			g_FG_PSEUDO100_col = <0x0a>;
			g_FG_PSEUDO100 = <0x64 0x64 0x5f 0x5f 0x64 0x64 0x5f 0x5f 0x64 0x64 0x5f 0x5f 0x64 0x64 0x5f 0x5f 0x64 0x64 0x5f 0x5f 0x64 0x64 0x5f 0x5f 0x64 0x64 0x5f 0x5f 0x64 0x64 0x5f 0x5f 0x64 0x64 0x5f 0x5f 0x64 0x64 0x5f 0x5f>;
		};
	};

	fragment@1 {
		target = <0xffffffff>;

		__overlay__ {
			status = "ok";
		};
	};

	fragment@2 {
		target = <0xffffffff>;

		__overlay__ {
			status = "ok";
		};
	};

	fragment@3 {
		target = <0xffffffff>;

		__overlay__ {
			atag,videolfb-fb_base_l = "~`P";
			atag,videolfb-fb_base_h = <0x00>;
			atag,videolfb-islcmfound = <0x01>;
			atag,videolfb-islcm_inited = <0x00>;
			atag,videolfb-fps = <0x1770>;
			atag,videolfb-vramSize = <0x1be0000>;
			atag,videolfb-lcmname = "td4330_fhdp_dsi_cmd_auo_rt4831_drv";
		};
	};

	fragment@4 {
		target = <0xffffffff>;

		__overlay__ {
			pinctrl-names = "irtx_gpio_led_default\0irtx_gpio_led_set";
			pinctrl-0 = <0x12>;
			pinctrl-1 = <0x13>;
			status = "okay";
		};
	};

	fragment@5 {
		target = <0xffffffff>;

		__overlay__ {

			irtx_gpio_led_def@gpio139 {
				phandle = <0x12>;

				pins_cmd_dat {
					pinmux = <0x8b00>;
					slew-rate = <0x01>;
					bias-disable;
					output-low;
					input-schmitt-enable = <0x00>;
				};
			};

			irtx_gpio_led_set@gpio139 {
				phandle = <0x13>;

				pins_cmd_dat {
					pinmux = <0x8b02>;
					slew-rate = <0x01>;
					output-high;
				};
			};
		};
	};

	fragment@6 {
		target = <0xffffffff>;

		__overlay__ {

			subpmic_mtk {
				mt6360,intr_gpio_num = <0x04>;
				mt6360,intr_gpio = <0xffffffff 0x04 0x00>;
				disable_lpsd = <0x01>;
			};
		};
	};

	fragment@7 {
		target = <0xffffffff>;

		__overlay__ {
			pwr_off_seq = <0x4000002>;
			sdcard-hlact = <0x00>;
		};
	};

	fragment@8 {
		target = <0xffffffff>;

		__overlay__ {
			mt6360pd,intr_gpio_num = <0x05>;
			mt6360pd,intr_gpio = <0xffffffff 0x05 0x00>;
		};
	};

	fragment@9 {
		target = <0xffffffff>;

		__overlay__ {
			uvlo-level = <0x9f6>;
		};
	};

	fragment@10 {
		target = <0xffffffff>;

		__overlay__ {

			lcm_led_en1_gpio {
				phandle = <0x14>;

				pins_cmd_dat {
					pinmux = <0x6b00>;
					slew-rate = <0x01>;
					output-high;
				};
			};

			lcm_led_en0_gpio {
				phandle = <0x15>;

				pins_cmd_dat {
					pinmux = <0x6b00>;
					slew-rate = <0x01>;
					output-low;
				};
			};

			lcd_bias_enp1_gpio {
				phandle = <0x16>;

				pins_cmd_dat {
					pinmux = <0x6c00>;
					slew-rate = <0x01>;
					output-high;
				};
			};

			lcd_bias_enp0_gpio {
				phandle = <0x17>;

				pins_cmd_dat {
					pinmux = <0x6c00>;
					slew-rate = <0x01>;
					output-low;
				};
			};

			lcd_bias_enn1_gpio {
				phandle = <0x18>;

				pins_cmd_dat {
					pinmux = <0x6f00>;
					slew-rate = <0x01>;
					output-high;
				};
			};

			lcd_bias_enn0_gpio {
				phandle = <0x19>;

				pins_cmd_dat {
					pinmux = <0x6f00>;
					slew-rate = <0x01>;
					output-low;
				};
			};

			lcm_rst_out1_gpio {
				phandle = <0x1a>;

				pins_cmd_dat {
					pinmux = <0x2800>;
					slew-rate = <0x01>;
					output-high;
				};
			};

			lcm_rst_out0_gpio {
				phandle = <0x1b>;

				pins_cmd_dat {
					pinmux = <0x2800>;
					slew-rate = <0x01>;
					output-low;
				};
			};

			lcm_dsi_te {
				phandle = <0x1c>;

				pins_cmd_dat {
					pinmux = <0x2701>;
				};
			};
		};
	};

	fragment@11 {
		target = <0xffffffff>;

		__overlay__ {
			pinctrl-names = "lcm_led_en1_gpio\0lcm_led_en0_gpio\0lcd_bias_enp1_gpio\0lcd_bias_enp0_gpio\0lcd_bias_enn1_gpio\0lcd_bias_enn0_gpio\0lcm_rst_out1_gpio\0lcm_rst_out0_gpio\0mode_te_te";
			pinctrl-0 = <0x14>;
			pinctrl-1 = <0x15>;
			pinctrl-2 = <0x16>;
			pinctrl-3 = <0x17>;
			pinctrl-4 = <0x18>;
			pinctrl-5 = <0x19>;
			pinctrl-6 = <0x1a>;
			pinctrl-7 = <0x1b>;
			pinctrl-8 = <0x1c>;
			status = "okay";
		};
	};

	fragment@12 {
		target = <0xffffffff>;

		__overlay__ {
			pinctrl-names = "lcm_rst_out1_gpio\0lcm_rst_out0_gpio\0mode_te_te";
			pinctrl-0 = <0x1a>;
			pinctrl-1 = <0x1b>;
			pinctrl-2 = <0x1c>;
			status = "okay";
		};
	};

	fragment@13 {
		target = <0xffffffff>;

		__overlay__ {
			status = "okay";
			#address-cells = <0x01>;
			#size-cells = <0x00>;

			panel@0 {
				compatible = "s6e8fc5,fhdp,cmd";
				reg = <0x00>;
				reset-gpios = <0xffffffff 0x28 0x00>;
				lcd-3p0-en-gpios = <0xffffffff 0x77 0x00>;
				pinctrl-names = "default";

				port {

					endpoint {
						remote-endpoint = <0x1d>;
						phandle = <0x1e>;
					};
				};
			};

			ports {

				port {

					endpoint {
						remote-endpoint = <0x1e>;
						phandle = <0x1d>;
					};
				};
			};
		};
	};

	fragment@14 {
		target = <0xffffffff>;

		__overlay__ {

			led@0 {
				compatible = "mediatek,red";
				led_mode = <0x00>;
				data = <0x01>;
				pwm_config = <0x00 0x00 0x00 0x00 0x00>;
			};

			led@1 {
				compatible = "mediatek,green";
				led_mode = <0x00>;
				data = <0x01>;
				pwm_config = <0x00 0x00 0x00 0x00 0x00>;
			};

			led@2 {
				compatible = "mediatek,blue";
				led_mode = <0x00>;
				data = <0x01>;
				pwm_config = <0x00 0x00 0x00 0x00 0x00>;
			};

			led@3 {
				compatible = "mediatek,jogball-backlight";
				led_mode = <0x00>;
				data = <0x01>;
				pwm_config = <0x00 0x00 0x00 0x00 0x00>;
			};

			led@4 {
				compatible = "mediatek,keyboard-backlight";
				led_mode = <0x00>;
				data = <0x01>;
				pwm_config = <0x00 0x00 0x00 0x00 0x00>;
			};

			led@5 {
				compatible = "mediatek,button-backlight";
				led_mode = <0x00>;
				data = <0x01>;
				pwm_config = <0x00 0x00 0x00 0x00 0x00>;
			};

			led@6 {
				compatible = "mediatek,lcd-backlight";
				led_mode = <0x06>;
				data = <0x01>;
				led_config = <0x08 0x0b>;
			};

			vibrator@0 {
				compatible = "mediatek,vibrator";
				vib_timer = <0x19>;
				vib_limit = <0x09>;
				vib_vol = <0x09>;
			};
		};
	};

	fragment@15 {
		target = <0xffffffff>;

		__overlay__ {

			gps_default {
				phandle = <0x1f>;
			};

			gps_l1_lna@0 {
				phandle = <0x20>;

				pins_cmd_dat {
					pinmux = <0xbc00>;
					output-low;
				};
			};

			gps_l1_lna@1 {
				phandle = <0x21>;

				pins_cmd_dat {
					pinmux = <0xbc04>;
				};
			};

			gps_l1_lna@2 {
				phandle = <0x22>;

				pins_cmd_dat {
					pinmux = <0xbc00>;
					output-high;
				};
			};

			gps_l5_lna@0 {
				phandle = <0x23>;

				pins_cmd_dat {
					pinmux = <0x1a00>;
					output-low;
				};
			};

			gps_l5_lna@1 {
				phandle = <0x24>;

				pins_cmd_dat {
					pinmux = <0x1a02>;
				};
			};

			gps_l5_lna@2 {
				phandle = <0x25>;

				pins_cmd_dat {
					pinmux = <0x1a00>;
					output-high;
				};
			};
		};
	};

	fragment@16 {
		target = <0xffffffff>;

		__overlay__ {
			pinctrl-names = "default\0gps_l1_lna_disable\0gps_l1_lna_dsp_ctrl\0gps_l1_lna_enable\0gps_l5_lna_disable\0gps_l5_lna_dsp_ctrl\0gps_l5_lna_enable";
			pinctrl-0 = <0x1f>;
			pinctrl-1 = <0x20>;
			pinctrl-2 = <0x21>;
			pinctrl-3 = <0x22>;
			pinctrl-4 = <0x23>;
			pinctrl-5 = <0x24>;
			pinctrl-6 = <0x25>;
			status = "okay";
		};
	};

	fragment@17 {
		target = <0xffffffff>;

		__overlay__ {
			status = "disabled";
		};
	};

	fragment@18 {
		target = <0xffffffff>;

		__overlay__ {
			pinctrl-names = "default";
			pinctrl-0 = <0x26>;
		};
	};

	fragment@19 {
		target = <0xffffffff>;

		__overlay__ {

			kpdgpiodefault {
				phandle = <0x26>;

				pins_cmd_dat {
					pinmux = <0x7401>;
					bias-pull-up = <0x66>;
					input-enable;
					input-schmitt-enable;
				};
			};
		};
	};

	fragment@20 {
		target = <0xffffffff>;

		__overlay__ {
			compatible = "mediatek,snd_audio_dsp";
			mtk_dsp_voip = <0x00 0xffffffff 0xffffffff 0xffffffff 0x30000>;
			mtk_dsp_primary = <0x1f 0xffffffff 0xffffffff 0xffffffff 0x30000>;
			mtk_dsp_offload = <0x00 0xffffffff 0xffffffff 0xffffffff 0x400000>;
			mtk_dsp_deep = <0x05 0xffffffff 0xffffffff 0xffffffff 0x30000>;
			mtk_dsp_playback = <0x01 0x04 0xffffffff 0x14 0x30000>;
			mtk_dsp_music = <0x01 0xffffffff 0xffffffff 0xffffffff 0x00>;
			mtk_dsp_capture1 = <0x01 0xffffffff 0x0d 0x13 0x20000>;
			mtk_dsp_a2dp = <0x00 0xffffffff 0xffffffff 0xffffffff 0x40000>;
			mtk_dsp_dataprovider = <0x00 0xffffffff 0x0f 0xffffffff 0x30000>;
			mtk_dsp_call_final = <0x05 0x04 0x10 0x14 0x18000>;
			mtk_dsp_fast = <0x05 0xffffffff 0xffffffff 0xffffffff 0x5000>;
			mtk_dsp_ktv = <0x00 0x08 0x12 0xffffffff 0x10000>;
			mtk_dsp_capture_raw = <0x00 0xffffffff 0xffffffff 0xffffffff 0x20000>;
			mtk_dsp_fm = <0x01 0xffffffff 0x10 0xffffffff 0x10000>;
			mtk_dsp_ver = <0x01>;
			swdsp_smartpa_process_enable = <0x05>;
			mtk_dsp_mem_afe = <0x01 0x40000>;
		};
	};

	fragment@21 {
		target = <0xffffffff>;

		__overlay__ {
			fixed_thermal;
		};
	};

	fragment@22 {
		target = <0xffffffff>;

		__overlay__ {
			status = "disabled";
		};
	};

	fragment@23 {
		target = <0xffffffff>;

		__overlay__ {

			MTEE {
				compatible = "mediatek,mtk_svp_on_mtee_support";
			};

			SecureVideoPath {
				compatible = "mediatek,mtk_sec_video_path_support";
			};
		};
	};

	fragment@24 {
		target = <0xffffffff>;

		__overlay__ {
			status = "disabled";
		};
	};

	fragment@25 {
		target = <0xffffffff>;

		__overlay__ {
			status = "disabled";
		};
	};

	fragment@26 {
		target = <0xffffffff>;

		__overlay__ {
			status = "disabled";
		};
	};

	fragment@27 {
		target = <0xffffffff>;

		__overlay__ {
			status = "disabled";
		};
	};

	fragment@28 {
		target = <0xffffffff>;

		__overlay__ {

			adc_channel@ {
				compatible = "mediatek,adc_channel";
				mediatek,temperature0 = <0x00>;
				mediatek,temperature1 = <0x01>;
				mediatek,adc_fdd_rf_params_dynamic_custom_ch = <0x06>;
				status = "okay";
			};
		};
	};

	fragment@29 {
		target = <0xffffffff>;

		__overlay__ {
			io-channels = <0xffffffff 0x06>;
		};
	};

	fragment@30 {
		target = <0xffffffff>;

		__overlay__ {
			mediatek,clkbuf-quantity = <0x07>;
			mediatek,clkbuf-config = <0x02 0x01 0x01 0x02 0x00 0x00 0x01>;
			mediatek,clkbuf-output-impedance = <0x03 0x04 0x03 0x04 0x00 0x00 0x03>;
			mediatek,clkbuf-controls-for-desense = <0x00 0x04 0x00 0x04 0x00 0x00 0x00>;
			status = "okay";
		};
	};

	fragment@31 {
		target = <0xffffffff>;

		__overlay__ {
			#address-cells = <0x01>;
			#size-cells = <0x00>;
			clock-frequency = <0x61a80>;
			mediatek,use-open-drain;
		};
	};

	fragment@32 {
		target = <0xffffffff>;

		__overlay__ {
			#address-cells = <0x01>;
			#size-cells = <0x00>;
			clock-frequency = <0x61a80>;
			mediatek,use-open-drain;
		};
	};

	fragment@33 {
		target = <0xffffffff>;

		__overlay__ {
			#address-cells = <0x01>;
			#size-cells = <0x00>;
			clock-frequency = <0x61a80>;
			mediatek,use-open-drain;
		};
	};

	fragment@34 {
		target = <0xffffffff>;

		__overlay__ {
			#address-cells = <0x01>;
			#size-cells = <0x00>;
			clock-frequency = <0x61a80>;
			mediatek,use-open-drain;
		};
	};

	fragment@35 {
		target = <0xffffffff>;

		__overlay__ {
			#address-cells = <0x01>;
			#size-cells = <0x00>;
			clock-frequency = <0x61a80>;
			mediatek,use-open-drain;
		};
	};

	fragment@36 {
		target = <0xffffffff>;

		__overlay__ {
			#address-cells = <0x01>;
			#size-cells = <0x00>;
			clock-frequency = <0x61a80>;
			mediatek,use-open-drain;

			i2c_lcd_bias@11 {
				compatible = "mediatek,i2c_lcd_bias";
				reg = <0x11>;
				status = "okay";
			};
		};
	};

	fragment@37 {
		target = <0xffffffff>;

		__overlay__ {
			#address-cells = <0x01>;
			#size-cells = <0x00>;
			clock-frequency = <0x61a80>;
			mediatek,use-open-drain;
		};
	};

	fragment@38 {
		target = <0xffffffff>;

		__overlay__ {
			#address-cells = <0x01>;
			#size-cells = <0x00>;
			clock-frequency = <0x61a80>;
			mediatek,use-open-drain;
		};
	};

	fragment@39 {
		target = <0xffffffff>;

		__overlay__ {
			#address-cells = <0x01>;
			#size-cells = <0x00>;
			clock-frequency = <0x61a80>;
			mediatek,use-open-drain;
		};
	};

	fragment@40 {
		target = <0xffffffff>;

		__overlay__ {
			#address-cells = <0x01>;
			#size-cells = <0x00>;
			clock-frequency = <0x61a80>;
			mediatek,use-open-drain;
		};
	};

	fragment@41 {
		target = <0xffffffff>;

		__overlay__ {
			#address-cells = <0x01>;
			#size-cells = <0x00>;
			clock-frequency = <0x61a80>;
			mediatek,use-open-drain;
		};
	};

	fragment@42 {
		target = <0xffffffff>;

		__overlay__ {
			GPIO_RF_PWREN_RST_PIN = <0xffffffff 0x4b 0x00>;
			GPIO_SIM2_SIO = <0xffffffff 0xaa 0x00>;
			GPIO_SIM2_SCLK = <0xffffffff 0xab 0x00>;
			GPIO_SIM2_SRST = <0xffffffff 0xac 0x00>;
			GPIO_SIM1_SRST = <0xffffffff 0xad 0x00>;
			GPIO_SIM1_SCLK = <0xffffffff 0xae 0x00>;
			GPIO_SIM1_SIO = <0xffffffff 0xaf 0x00>;
			GPIO_SIM1_HOT_PLUG = <0xffffffff 0xb0 0x00>;
		};
	};

	fragment@43 {
		target = <0xffffffff>;

		__overlay__ {
			gpio_init_default = <0x00 0x03 0x00 0x00 0x01 0x00 0x01 0x01 0x00 0x00 0x00 0x01 0x00 0x00 0x02 0x00 0x00 0x00 0x00 0x00 0x01 0x03 0x00 0x00 0x00 0x00 0x00 0x01 0x04 0x00 0x00 0x00 0x01 0x01 0x01 0x05 0x00 0x00 0x00 0x01 0x01 0x01 0x06 0x00 0x00 0x00 0x00 0x00 0x00 0x07 0x00 0x01 0x00 0x01 0x00 0x01 0x08 0x00 0x00 0x00 0x01 0x00 0x00 0x09 0x00 0x00 0x00 0x00 0x00 0x00 0x0a 0x00 0x00 0x00 0x01 0x00 0x00 0x0b 0x00 0x00 0x00 0x01 0x00 0x00 0x0c 0x00 0x00 0x00 0x00 0x00 0x00 0x0d 0x00 0x00 0x00 0x01 0x00 0x00 0x0e 0x00 0x00 0x00 0x00 0x00 0x01 0x0f 0x00 0x00 0x00 0x00 0x00 0x01 0x10 0x00 0x00 0x00 0x01 0x01 0x00 0x11 0x00 0x00 0x00 0x00 0x00 0x00 0x12 0x00 0x00 0x00 0x01 0x00 0x00 0x13 0x00 0x01 0x00 0x01 0x00 0x00 0x14 0x00 0x00 0x00 0x01 0x00 0x00 0x15 0x00 0x00 0x00 0x01 0x01 0x00 0x16 0x00 0x00 0x00 0x01 0x01 0x00 0x17 0x07 0x00 0x00 0x01 0x00 0x00 0x18 0x00 0x00 0x00 0x01 0x00 0x00 0x19 0x00 0x00 0x00 0x01 0x00 0x00 0x1a 0x00 0x00 0x00 0x01 0x00 0x00 0x1b 0x00 0x01 0x01 0x01 0x00 0x00 0x1c 0x00 0x00 0x00 0x01 0x00 0x00 0x1d 0x00 0x00 0x00 0x01 0x00 0x00 0x1e 0x00 0x00 0x00 0x01 0x00 0x00 0x1f 0x00 0x00 0x00 0x01 0x00 0x00 0x20 0x00 0x00 0x00 0x01 0x00 0x00 0x21 0x00 0x00 0x00 0x01 0x00 0x00 0x22 0x00 0x00 0x00 0x01 0x00 0x00 0x23 0x00 0x00 0x00 0x01 0x00 0x00 0x24 0x03 0x00 0x00 0x01 0x01 0x01 0x25 0x03 0x00 0x00 0x01 0x01 0x01 0x26 0x00 0x00 0x00 0x01 0x00 0x01 0x27 0x01 0x00 0x00 0x01 0x00 0x01 0x28 0x00 0x01 0x00 0x00 0x02 0x00 0x29 0x01 0x00 0x00 0x00 0x00 0x01 0x2a 0x01 0x00 0x00 0x00 0x00 0x01 0x2b 0x01 0x00 0x00 0x01 0x00 0x01 0x2c 0x01 0x00 0x00 0x01 0x00 0x01 0x2d 0x01 0x00 0x00 0x01 0x00 0x01 0x2e 0x01 0x00 0x00 0x00 0x00 0x00 0x2f 0x01 0x00 0x00 0x00 0x00 0x00 0x30 0x01 0x00 0x00 0x00 0x00 0x00 0x31 0x01 0x00 0x00 0x00 0x00 0x00 0x32 0x01 0x00 0x00 0x01 0x00 0x00 0x33 0x01 0x00 0x00 0x01 0x00 0x00 0x34 0x01 0x00 0x00 0x01 0x00 0x00 0x35 0x01 0x00 0x00 0x01 0x00 0x00 0x36 0x01 0x00 0x00 0x01 0x00 0x01 0x37 0x01 0x00 0x00 0x01 0x00 0x00 0x38 0x01 0x00 0x00 0x01 0x00 0x00 0x39 0x01 0x00 0x00 0x01 0x00 0x00 0x3a 0x01 0x00 0x00 0x01 0x00 0x00 0x3b 0x01 0x00 0x00 0x01 0x00 0x00 0x3c 0x01 0x00 0x00 0x00 0x00 0x01 0x3d 0x01 0x00 0x00 0x00 0x00 0x01 0x3e 0x00 0x00 0x00 0x01 0x00 0x01 0x3f 0x00 0x00 0x00 0x01 0x00 0x01 0x40 0x01 0x00 0x00 0x01 0x01 0x01 0x41 0x01 0x00 0x00 0x01 0x01 0x01 0x42 0x01 0x00 0x00 0x01 0x00 0x01 0x43 0x01 0x00 0x00 0x01 0x00 0x01 0x44 0x00 0x00 0x00 0x01 0x00 0x00 0x45 0x00 0x00 0x00 0x01 0x00 0x00 0x46 0x01 0x00 0x00 0x01 0x00 0x01 0x47 0x00 0x00 0x00 0x00 0x00 0x01 0x48 0x00 0x00 0x00 0x00 0x00 0x01 0x49 0x01 0x00 0x00 0x01 0x00 0x00 0x4a 0x00 0x00 0x00 0x01 0x00 0x01 0x4b 0x00 0x01 0x01 0x01 0x00 0x01 0x4c 0x00 0x01 0x00 0x01 0x00 0x01 0x4d 0x00 0x00 0x00 0x01 0x00 0x01 0x4e 0x01 0x00 0x00 0x01 0x00 0x00 0x4f 0x01 0x00 0x00 0x01 0x00 0x00 0x50 0x00 0x00 0x00 0x01 0x00 0x00 0x51 0x00 0x00 0x00 0x01 0x00 0x01 0x52 0x01 0x00 0x00 0x00 0x00 0x00 0x53 0x01 0x00 0x00 0x01 0x00 0x00 0x54 0x01 0x00 0x00 0x00 0x00 0x00 0x55 0x01 0x00 0x00 0x01 0x00 0x00 0x56 0x01 0x00 0x00 0x01 0x00 0x01 0x57 0x00 0x00 0x00 0x01 0x00 0x01 0x58 0x00 0x00 0x00 0x01 0x00 0x01 0x59 0x00 0x00 0x00 0x01 0x00 0x01 0x5a 0x00 0x00 0x00 0x00 0x00 0x01 0x5b 0x00 0x00 0x00 0x01 0x00 0x01 0x5c 0x00 0x00 0x00 0x01 0x00 0x01 0x5d 0x00 0x00 0x00 0x01 0x00 0x01 0x5e 0x00 0x00 0x00 0x01 0x00 0x00 0x5f 0x00 0x00 0x00 0x01 0x00 0x01 0x60 0x00 0x01 0x00 0x01 0x00 0x01 0x61 0x00 0x01 0x00 0x01 0x00 0x01 0x62 0x01 0x00 0x00 0x00 0x00 0x00 0x63 0x01 0x00 0x00 0x00 0x00 0x00 0x64 0x01 0x00 0x00 0x01 0x00 0x00 0x65 0x01 0x00 0x00 0x00 0x00 0x00 0x66 0x00 0x00 0x00 0x01 0x00 0x00 0x67 0x01 0x00 0x00 0x00 0x00 0x00 0x68 0x01 0x00 0x00 0x00 0x00 0x00 0x69 0x01 0x00 0x00 0x01 0x00 0x00 0x6a 0x01 0x00 0x00 0x00 0x00 0x00 0x6b 0x00 0x01 0x00 0x01 0x00 0x01 0x6c 0x00 0x01 0x00 0x01 0x00 0x01 0x6d 0x00 0x00 0x00 0x01 0x00 0x00 0x6e 0x00 0x01 0x00 0x01 0x00 0x00 0x6f 0x00 0x00 0x00 0x01 0x00 0x00 0x70 0x01 0x00 0x00 0x00 0x00 0x00 0x71 0x00 0x00 0x00 0x01 0x00 0x00 0x72 0x01 0x00 0x00 0x01 0x01 0x00 0x73 0x02 0x00 0x00 0x01 0x00 0x00 0x74 0x01 0x00 0x00 0x01 0x01 0x01 0x75 0x00 0x01 0x00 0x01 0x00 0x00 0x76 0x00 0x00 0x00 0x00 0x02 0x00 0x77 0x00 0x01 0x00 0x00 0x02 0x00 0x78 0x00 0x00 0x00 0x01 0x00 0x00 0x79 0x00 0x01 0x00 0x01 0x00 0x00 0x7a 0x07 0x00 0x00 0x01 0x00 0x01 0x7b 0x07 0x00 0x00 0x01 0x00 0x00 0x7c 0x07 0x00 0x00 0x01 0x00 0x00 0x7d 0x07 0x00 0x00 0x01 0x00 0x00 0x7e 0x02 0x00 0x00 0x00 0x00 0x00 0x7f 0x02 0x00 0x00 0x00 0x00 0x00 0x80 0x02 0x00 0x00 0x00 0x00 0x01 0x81 0x02 0x00 0x00 0x01 0x00 0x01 0x82 0x02 0x00 0x00 0x01 0x01 0x01 0x83 0x02 0x00 0x00 0x01 0x01 0x01 0x84 0x01 0x00 0x00 0x01 0x01 0x01 0x85 0x01 0x00 0x00 0x01 0x01 0x01 0x86 0x01 0x00 0x00 0x01 0x01 0x01 0x87 0x01 0x00 0x00 0x01 0x01 0x01 0x88 0x01 0x00 0x00 0x01 0x01 0x01 0x89 0x01 0x00 0x00 0x01 0x01 0x01 0x8a 0x00 0x00 0x00 0x01 0x00 0x00 0x8b 0x00 0x00 0x00 0x01 0x00 0x00 0x8c 0x00 0x01 0x00 0x01 0x00 0x01 0x8d 0x00 0x01 0x00 0x01 0x00 0x01 0x8e 0x00 0x00 0x00 0x01 0x00 0x00 0x8f 0x01 0x00 0x00 0x01 0x01 0x01 0x90 0x01 0x00 0x00 0x01 0x01 0x01 0x91 0x01 0x00 0x00 0x00 0x00 0x01 0x92 0x01 0x00 0x00 0x00 0x00 0x01 0x93 0x01 0x00 0x00 0x01 0x01 0x01 0x94 0x01 0x00 0x00 0x01 0x01 0x01 0x95 0x00 0x01 0x00 0x00 0x00 0x00 0x96 0x00 0x01 0x00 0x00 0x00 0x00 0x97 0x00 0x01 0x00 0x00 0x00 0x00 0x98 0x00 0x00 0x00 0x01 0x00 0x00 0x99 0x00 0x01 0x00 0x00 0x00 0x00 0x9a 0x00 0x01 0x00 0x01 0x00 0x00 0x9b 0x00 0x01 0x00 0x01 0x00 0x00 0x9c 0x03 0x00 0x00 0x00 0x00 0x00 0x9d 0x03 0x00 0x00 0x00 0x00 0x00 0x9e 0x00 0x01 0x00 0x01 0x00 0x00 0x9f 0x00 0x01 0x00 0x01 0x00 0x00 0xa0 0x00 0x00 0x00 0x01 0x00 0x00 0xa1 0x00 0x00 0x00 0x01 0x00 0x00 0xa2 0x00 0x00 0x00 0x01 0x00 0x00 0xa3 0x00 0x00 0x00 0x01 0x00 0x00 0xa4 0x01 0x00 0x00 0x01 0x01 0x00 0xa5 0x01 0x00 0x00 0x00 0x00 0x00 0xa6 0x01 0x00 0x00 0x01 0x01 0x00 0xa7 0x01 0x00 0x00 0x01 0x01 0x00 0xa8 0x01 0x00 0x00 0x01 0x01 0x00 0xa9 0x01 0x00 0x00 0x01 0x01 0x00 0xaa 0x01 0x00 0x00 0x01 0x01 0x01 0xab 0x01 0x00 0x00 0x00 0x00 0x01 0xac 0x01 0x00 0x00 0x00 0x00 0x01 0xad 0x01 0x00 0x00 0x00 0x00 0x01 0xae 0x01 0x00 0x00 0x00 0x00 0x01 0xaf 0x01 0x00 0x00 0x01 0x01 0x01 0xb0 0x01 0x00 0x00 0x00 0x00 0x01 0xb1 0x00 0x00 0x00 0x01 0x00 0x01 0xb2 0x01 0x00 0x00 0x00 0x00 0x00 0xb3 0x01 0x00 0x00 0x01 0x01 0x00 0xb4 0x00 0x00 0x00 0x01 0x00 0x00 0xb5 0x00 0x00 0x00 0x01 0x00 0x00 0xb6 0x02 0x00 0x00 0x00 0x00 0x00 0xb7 0x02 0x00 0x00 0x00 0x00 0x00 0xb8 0x02 0x00 0x00 0x00 0x00 0x01 0xb9 0x02 0x00 0x00 0x01 0x00 0x01 0xba 0x01 0x00 0x00 0x01 0x01 0x01 0xbb 0x01 0x00 0x00 0x01 0x01 0x01 0xbc 0x04 0x00 0x00 0x01 0x00 0x00 0xbd 0x00 0x00 0x00 0x01 0x00 0x00 0xbe 0x00 0x00 0x00 0x01 0x00 0x00 0xbf 0x05 0x00 0x00 0x00 0x00 0x00 0xc0 0x05 0x00 0x00 0x00 0x00 0x00 0xc1 0x00 0x00 0x00 0x01 0x00 0x00 0xc2 0x00 0x00 0x00 0x01 0x00 0x00 0xc3 0x00 0x01 0x00 0x01 0x00 0x00 0xc4 0x01 0x00 0x00 0x01 0x00 0x00 0xc5 0x01 0x00 0x00 0x01 0x00 0x00 0xc6 0x01 0x00 0x00 0x01 0x00 0x00 0xc7 0x01 0x00 0x00 0x01 0x00 0x00 0xc8 0x01 0x00 0x00 0x01 0x00 0x00 0xc9 0x01 0x00 0x00 0x01 0x00 0x00 0xca 0x01 0x00 0x00 0x01 0x00 0x00 0xcb 0x01 0x00 0x00 0x01 0x00 0x00 0xcc 0x01 0x00 0x00 0x01 0x00 0x00 0xcd 0x01 0x00 0x00 0x01 0x00 0x00 0xce 0x01 0x00 0x00 0x01 0x00 0x00 0xcf 0x00 0x00 0x00 0x01 0x00 0x00 0xd0 0x00 0x00 0x00 0x01 0x00 0x00>;
		};
	};

	fragment@44 {
		target = <0xffffffff>;

		__overlay__ {
			interrupt-parent = <0xffffffff>;
			interrupts = <0x00 0x08>;
			status = "okay";
		};
	};

	fragment@45 {
		target = <0xffffffff>;

		__overlay__ {
			interrupt-parent = <0xffffffff>;
			interrupts = <0x03 0x08>;
			status = "okay";
		};
	};

	fragment@46 {
		target = <0xffffffff>;

		__overlay__ {
			interrupt-parent = <0xffffffff>;
			interrupts = <0x04 0x02>;
			status = "okay";
		};
	};

	fragment@47 {
		target = <0xffffffff>;

		__overlay__ {
			interrupt-parent = <0xffffffff>;
			interrupts = <0x08 0x04>;
			status = "okay";
		};
	};

	fragment@48 {
		target = <0xffffffff>;

		__overlay__ {
			interrupt-parent = <0xffffffff>;
			interrupts = <0x0e 0x08>;
			status = "okay";
		};
	};

	fragment@49 {
		target = <0xffffffff>;

		__overlay__ {
			interrupt-parent = <0xffffffff>;
			interrupts = <0x25 0x01>;
			status = "okay";
		};
	};

	fragment@50 {
		target = <0xffffffff>;

		__overlay__ {
			compatible = "mediatek,md1_sim1_hot_plug_eint-eint";
			interrupts = <0x00 0x08>;
			debounce = <0x00 0xc350>;
			dedicated = <0x00 0x00>;
			src_pin = <0x00 0x01>;
			sockettype = <0x00 0x00>;
			status = "okay";
		};
	};

	fragment@51 {
		target = <0xffffffff>;

		__overlay__ {
			compatible = "mediatek,md1_sim2_hot_plug_eint-eint";
			interrupts = <0x01 0x08>;
			debounce = <0x01 0xc350>;
			dedicated = <0x01 0x00>;
			src_pin = <0x01 0x02>;
			sockettype = <0x01 0x00>;
			status = "okay";
		};
	};

	fragment@52 {
		target = <0xffffffff>;

		__overlay__ {
			cd-gpios = <0xffffffff 0x09 0x00>;
		};
	};

	fragment@53 {
		target = <0xffffffff>;

		__overlay__ {
			regulator-name = "vcamio";
			regulator-default-on = <0x01>;
			status = "okay";
		};
	};

	fragment@54 {
		target = <0xffffffff>;

		__overlay__ {
			regulator-name = "vtp";
			regulator-default-on = <0x01>;
			status = "okay";
		};
	};

	fragment@55 {
		target = <0xffffffff>;

		__overlay__ {
			vcamio-supply = <0xffffffff>;
			status = "okay";
		};
	};

	fragment@56 {
		target = <0xffffffff>;

		__overlay__ {
			vtouch-supply = <0xffffffff>;
			status = "okay";
		};
	};

	fragment@57 {
		target = <0xffffffff>;

		__overlay__ {
			mediatek,long-press-mode = <0x02>;

			home {
				linux,keycodes = <0x72>;
			};
		};
	};

	fragment@58 {
		target = <0xffffffff>;

		__overlay__ {
			mediatek,key-debounce = <0x400>;
			mediatek,sw-pwrkey = <0x74>;
			mediatek,hw-pwrkey = <0x08>;
			mediatek,sw-rstkey = <0x72>;
			mediatek,hw-rstkey = <0x11>;
			mediatek,use-extend-type = <0x00>;
			mediatek,hw-map-num = <0x48>;
			mediatek,hw-init-map = <0x00 0x73 0x00 0x00 0x00 0x00 0x00 0x00 0x00 0x00 0x00 0x00 0x00 0x00 0x00 0x00 0x00 0x00 0x00 0x00 0x00 0x00 0x00 0x00 0x00 0x00 0x00 0x00 0x00 0x00 0x00 0x00 0x00 0x00 0x00 0x00 0x00 0x00 0x00 0x00 0x00 0x00 0x00 0x00 0x00 0x00 0x00 0x00 0x00 0x00 0x00 0x00 0x00 0x00 0x00 0x00 0x00 0x00 0x00 0x00 0x00 0x00 0x00 0x00 0x00 0x00 0x00 0x00 0x00 0x00 0x00 0x00>;
			mediatek,pwrkey-eint-gpio = <0x00>;
			mediatek,pwkey-gpio-din = <0x00>;
			mediatek,hw-dl-key0 = <0x11>;
			mediatek,hw-dl-key1 = <0x00>;
			mediatek,hw-dl-key2 = <0x08>;
			mediatek,hw-recovery-key = <0x11>;
			mediatek,hw-factory-key = <0x00>;
			status = "okay";
		};
	};

	fragment@59 {
		target = <0xffffffff>;

		__overlay__ {

			gpio_i2c_0_sda {

				gpio_i2c_0_sda_default {
					phandle = <0x27>;

					pins_cmd_dat {
						pinmux = <0x6600>;
						bias-disable;
						input-enable;
						drive-strength = <0x02>;
					};
				};
			};
		};
	};

	fragment@60 {
		target = <0xffffffff>;

		__overlay__ {

			gpio_i2c_0_scl {

				gpio_i2c_0_scl_default {
					phandle = <0x28>;

					pins_cmd_dat {
						pinmux = <0x7500>;
						bias-disable;
						input-enable;
						drive-strength = <0x02>;
					};
				};
			};
		};
	};

	fragment@model {
		target-path = "/";

		__overlay__ {

			aliases {
				i2c50 = "/i2c@50";
			};

			i2c@50 {
				cell-index = <0x32>;
				compatible = "i2c-gpio";
				gpios = <0xffffffff 0x66 0x00 0xffffffff 0x75 0x00>;
				#i2c-gpio,delay-us = <0x02>;
				#address-cells = <0x01>;
				#size-cells = <0x00>;
				pinctrl-names = "default";
				pinctrl-0 = <0x27 0x28>;
				status = "okay";

				s2mpb03_pmic@56 {
					compatible = "samsung,s2mpb03pmic";
					reg = <0x56>;
					s2mpb03,wakeup;

					regulators {

						s2mpb03-ldo1 {
							regulator-name = "CAM0_s2mpb03-l1";
							regulator-min-microvolt = <0x10c8e0>;
							regulator-max-microvolt = <0x124f80>;
							phandle = <0x62>;
						};

						s2mpb03-ldo2 {
							regulator-name = "CAM0_s2mpb03-l2";
							regulator-min-microvolt = <0x10c8e0>;
							regulator-max-microvolt = <0x124f80>;
							phandle = <0x5e>;
						};

						s2mpb03-ldo3 {
							regulator-name = "CAM0_s2mpb03-l3";
							regulator-min-microvolt = <0x1b7740>;
							regulator-max-microvolt = <0x1b7740>;
							phandle = <0x5f>;
						};

						s2mpb03-ldo4 {
							regulator-name = "CAM0_s2mpb03-l4";
							regulator-min-microvolt = <0x124f80>;
							regulator-max-microvolt = <0x124f80>;
							phandle = <0x63>;
						};

						s2mpb03-ldo5 {
							regulator-name = "CAM0_s2mpb03-l5";
							regulator-min-microvolt = <0x2c4020>;
							regulator-max-microvolt = <0x2c4020>;
							phandle = <0x5d>;
						};

						s2mpb03-ldo6 {
							regulator-name = "CAM0_s2mpb03-l6";
							regulator-min-microvolt = <0x2ab980>;
							regulator-max-microvolt = <0x2ab980>;
							phandle = <0x61>;
						};

						s2mpb03-ldo7 {
							regulator-name = "CAM0_s2mpb03-l7";
							regulator-min-microvolt = <0x2ab980>;
							regulator-max-microvolt = <0x2ab980>;
							phandle = <0x60>;
						};
					};
				};
			};

			shub {
				compatible = "shub";
				acc-motor-coef = <0x05>;
				acc-lsm6dsotr-position = <0x07>;
				mag-ak09918c-position = <0x07>;
				mag-ak09918c-array = [00 00 00 00 00 00 00 00 00 00 00 00 00 00 00 00 00 00 00 00 00 00 00 00 00 00 00];
				mag-mxg4300s-position = <0x04>;
				mag-mxg4300s-array = [28 32 04 b0 00 b4 04 b0 22 38 fe fc 00 b4 fe fc 2a b2 00 00 00 00 00 00 00 00 00];
				fcd-axis = <0x01>;
				fcd-threshold = <0x1f4>;
				light-position = <0x1a 0x34 0x03 0x43 0x02 0x00>;
				brightness-array-len = <0x0b>;
				brightness-array = <0x13 0x30 0x36 0x3a 0x3f 0x43 0x46 0x49 0x4b 0x4d 0x64>;
				pinctrl-names = "default";
				sensor-vdd-regulator = "VDD_SENSOR_1P8";
			};

			sec-audio-sysfs {
				compatible = "samsung,audio-sysfs";
				status = "okay";
				audio,no-earjack;
				audio,num-amp = <0x02>;
			};

			snd-debug-proc {
				compatible = "samsung,snd-debug-proc";
				status = "okay";
			};
		};
	};

	fragment@61 {
		target = <0xffffffff>;

		__overlay__ {
			status = "okay";

			sm5451@63 {
				compatible = "siliconmitus,sm5451";
				reg = <0x63>;
				sm5451,freq_byp = <0x01>;
				sm5451,freq = <0x02>;
				sm5451,r_ttl = <0x7ef40>;
				sm5451,topoff = <0x17c>;
				sm5451,en_vbatreg = <0x01>;
			};
		};
	};

	fragment@62 {
		target = <0xffffffff>;

		__overlay__ {

			motor_pwm {

				motor_pwm_active {
					pinmux = <0x03>;
					bias-disable;
					output-low;
					phandle = <0x01>;
				};
			};
		};
	};

	fragment@63 {
		target = <0xffffffff>;

		__overlay__ {

			vib_en_gpio {
				phandle = <0x02>;

				pins_cmd_dat {
					pinmux = <0xc300>;
					slew-rate = <0x01>;
					bias-disable;
					output-low;
				};
			};
		};
	};

	fragment@64 {
		target = <0xffffffff>;

		__overlay__ {

			hall_irq {
				pinmux = <0x600>;
				bias-disable;
				phandle = <0x03>;
			};
		};
	};

	fragment@65 {
		target = <0xffffffff>;

		__overlay__ {

			btp_sleep_enable {
				phandle = <0x04>;

				pins_cmd_dat {
					pinmux = <0x7900>;
					bias-pull-down;
					drive-strength = <0x01>;
				};
			};
		};
	};

	fragment@66 {
		target = <0xffffffff>;

		__overlay__ {

			btp_ldo_enable {
				phandle = <0x05>;

				pins_cmd_dat {
					pinmux = <0x6000>;
					bias-pull-down;
					drive-strength = <0x01>;
				};
			};
		};
	};

	fragment@67 {
		target = <0xffffffff>;

		__overlay__ {

			set_miso {
				phandle = <0x06>;

				pins_cmd_dat {
					pinmux = <0x6401>;
					drive-strength = <0x04>;
				};
			};

			set_cs {
				phandle = <0x07>;

				pins_cmd_dat {
					pinmux = <0x6301>;
					drive-strength = <0x04>;
				};
			};

			set_mosi {
				phandle = <0x08>;

				pins_cmd_dat {
					pinmux = <0x6501>;
					drive-strength = <0x04>;
				};
			};

			set_clk {
				phandle = <0x09>;

				pins_cmd_dat {
					pinmux = <0x6201>;
					drive-strength = <0x04>;
				};
			};

			clr_miso {
				phandle = <0x0a>;

				pins_cmd_dat {
					pinmux = <0x6400>;
					slew-rate = <0x00>;
					bias-pull-down;
					input-enable;
					drive-strength = <0x01>;
				};
			};

			clr_cs {
				phandle = <0x0b>;

				pins_cmd_dat {
					pinmux = <0x6300>;
					slew-rate = <0x00>;
					bias-pull-down;
					output-low;
					drive-strength = <0x01>;
				};
			};

			clr_mosi {
				phandle = <0x0c>;

				pins_cmd_dat {
					pinmux = <0x6500>;
					slew-rate = <0x00>;
					bias-pull-down;
					output-low;
					drive-strength = <0x01>;
				};
			};

			clr_clk {
				phandle = <0x0d>;

				pins_cmd_dat {
					pinmux = <0x6200>;
					slew-rate = <0x00>;
					bias-pull-down;
					output-low;
					drive-strength = <0x01>;
				};
			};
		};
	};

	fragment@68 {
		target = <0xffffffff>;

		__overlay__ {

			sec-mst,mst-pwr-gpio {
				phandle = <0x0e>;

				pins_cmd_dat {
					pinmux = <0x6d00>;
					bias-pull-down;
					output-low;
				};
			};
		};
	};

	fragment@69 {
		target = <0xffffffff>;

		__overlay__ {
			regulator-min-microvolt = <0x325aa0>;
			regulator-max-microvolt = <0x325aa0>;
			regulator-always-on;
			regulator-boot-on;
		};
	};

	fragment@70 {
		target = <0xffffffff>;

		__overlay__ {
			regulator-min-microvolt = <0x2dc6c0>;
			regulator-max-microvolt = <0x2dc6c0>;
		};
	};

	fragment@71 {
		target = <0xffffffff>;

		__overlay__ {
			regulator-min-microvolt = <0x1b7740>;
			regulator-max-microvolt = <0x1b7740>;
		};
	};

	fragment@72 {
		target = <0xffffffff>;

		__overlay__ {
			regulator-min-microvolt = <0x1b7740>;
			regulator-max-microvolt = <0x1b7740>;
			regulator-always-on;
			regulator-boot-on;
		};
	};

	fragment@73 {
		target = <0xffffffff>;

		__overlay__ {

			afc_output {
				phandle = <0x10>;

				pins_cmd_dat {
					pinmux = <0xc00>;
					slew-rate = <0x01>;
					output-enable;
					bias-disable;
				};
			};
		};
	};

	fragment@74 {
		target = <0xffffffff>;

		__overlay__ {

			afc_switch {
				phandle = <0x0f>;

				pins_cmd_dat {
					pinmux = <0x4c00>;
					slew-rate = <0x01>;
					output-enable;
					bias-disable;
				};
			};
		};
	};

	fragment@75 {
		target = <0xffffffff>;

		__overlay__ {

			hiccup_switch {
				phandle = <0x11>;

				pins_cmd_dat {
					pinmux = <0x6100>;
					slew-rate = <0x01>;
					output-enable;
					bias-disable;
				};
			};
		};
	};

	fragment@76 {
		target = <0xffffffff>;

		__overlay__ {
			regulator-name = "VDD_SENSOR_1P8";
		};
	};

	fragment@77 {
		target = <0xffffffff>;

		__overlay__ {

			nfc_ven {
				phandle = <0x29>;

				pins_cmd_dat {
					pinmux = <0x6b00>;
					output-low;
					bias-disable;
				};
			};

			ven_nc {
				phandle = <0x2e>;

				pins_cmd_dat {
					pinmux = <0x6b00>;
					input-enable;
					bias-pull-down;
				};
			};
		};
	};

	fragment@78 {
		target = <0xffffffff>;

		__overlay__ {

			nfc_firm {
				phandle = <0x2a>;

				pins_cmd_dat {
					pinmux = <0x6c00>;
					output-low;
					bias-disable;
				};
			};

			firm_nc {
				phandle = <0x2f>;

				pins_cmd_dat {
					pinmux = <0x6c00>;
					input-enable;
					bias-pull-down;
				};
			};
		};
	};

	fragment@79 {
		target = <0xffffffff>;

		__overlay__ {

			nfc_clk_req {
				phandle = <0x2b>;

				pins_cmd_dat {
					pinmux = <0xd00>;
					input-enable;
					bias-pull-down;
				};
			};

			clk_req_nc {
				phandle = <0x30>;

				pins_cmd_dat {
					pinmux = <0xd00>;
					input-enable;
					bias-pull-down;
				};
			};
		};
	};

	fragment@80 {
		target = <0xffffffff>;

		__overlay__ {

			nfc_irq {
				phandle = <0x2c>;

				pins_cmd_dat {
					pinmux = <0xb00>;
					input-enable;
					bias-pull-down;
				};
			};

			irq_nc {
				phandle = <0x31>;

				pins_cmd_dat {
					pinmux = <0xb00>;
					input-enable;
					bias-pull-down;
				};
			};
		};
	};

	fragment@81 {
		target = <0xffffffff>;

		__overlay__ {

			nfc_check {
				phandle = <0x2d>;

				pins_cmd_dat {
					pinmux = <0x5a00>;
					input-enable;
					bias-disable;
				};
			};
		};
	};

	fragment@82 {
		target = <0xffffffff>;

		__overlay__ {
			status = "ok";
			clock-frequency = <0x61a80>;
			mediatek,use-open-drain;

			sec-nfc@27 {
				compatible = "sec-nfc";
				reg = <0x27>;
				interrupt-parent = <0xffffffff>;
				interrupts = <0x0b 0x01 0x0b 0x00>;
				sec-nfc,irq-gpio = <0xffffffff 0x0b 0x00>;
				sec-nfc,ven-gpio = <0xffffffff 0x6b 0x00>;
				sec-nfc,firm-gpio = <0xffffffff 0x6c 0x00>;
				sec-nfc,clk_req-gpio = <0xffffffff 0x0d 0x00>;
				nfc_pvdd-supply = <0xffffffff>;
				sec-nfc,check_nfc = <0xffffffff 0x5a 0x00>;
				sec-nfc,clk_req_wake;
				sec-nfc,ldo_control;
				sec-nfc,nfc_ic_type = "SN4V_RN4V";
				pinctrl-names = "default\0nfc_nc";
				pinctrl-0 = <0x29 0x2a 0x2b 0x2c 0x2d>;
				pinctrl-1 = <0x2e 0x2f 0x30 0x31>;
			};
		};
	};

	fragment@83 {
		target = <0xffffffff>;

		__overlay__ {

			berlin_attn_irq {
				phandle = <0x32>;

				pins_cmd_dat {
					pinmux = <0xe00>;
					bias-disable;
					input-enable;
				};
			};

			berlin_attn_irq_suspend {
				phandle = <0x33>;

				pins_cmd_dat {
					pinmux = <0xe00>;
					bias-disable;
					input-enable;
				};
			};
		};
	};

	fragment@84 {
		target = <0xffffffff>;

		__overlay__ {
			#address-cells = <0x01>;
			#size-cells = <0x00>;
			status = "okay";
			clock-frequency = <0x61a80>;

			touchscreen@5d {
				status = "okay";
				compatible = "goodix,berlin";
				reg = <0x5d>;
				pinctrl-names = "on_state\0off_state";
				pinctrl-0 = <0x32>;
				pinctrl-1 = <0x33>;
				tsp_avdd_ldo-supply = <0xffffffff>;
				sec,irq_gpio = <0xffffffff 0x0e 0x00>;
				sec,irq_flag = <0x2002>;
				support_dex_mode;
				sec,enable_sysinput_enabled;
				support_open_short_test;
				not_support_io_ldo;
				support_ear_detect_mode;
				support_fod;
				support_fod_lp_mode;
				enable_settings_aot;
				sec,bitmask_unload = <0x0c 0x804>;
				sec,refresh_rate_enable;
				sec,enable_esd_check;
				sec,max_coords = <0x438 0x924>;
				sec,firmware_name = "tsp_goodix/gt9895_a34x.bin";
				sec,bringup = <0x00>;
				sec,ic_type = <0x02>;
				sec,max_drv_num = <0x11>;
				sec,max_sen_num = <0x23>;
				sec,drv_map = <0x23 0x24 0x25 0x26 0x27 0x28 0x29 0x2a 0x2b 0x2c 0x2d 0x2e 0x2f 0x30 0x31 0x32 0x33>;
				sec,sen_map = <0x00 0x01 0x02 0x03 0x04 0x05 0x06 0x07 0x08 0x09 0x0a 0x0b 0x0c 0x0d 0x0e 0x0f 0x10 0x11 0x12 0x13 0x14 0x15 0x16 0x17 0x18 0x19 0x1a 0x1b 0x1c 0x1d 0x1e 0x1f 0x20 0x21 0x22>;
				sec,short_test_time_reg = <0x1479e>;
				sec,short_test_status_reg = <0x13400>;
				sec,short_test_result_reg = <0x13408>;
				sec,drv_drv_reg = <0x13446>;
				sec,sen_sen_reg = <0x136ee>;
				sec,drv_sen_reg = <0x14152>;
				sec,diff_code_reg = <0x14734>;
				sec,production_test_addr = <0x15d4c>;
				sec,switch_freq_cmd = <0xb1>;
				sec,switch_cfg_cmd = <0x64>;
				sec,snr_cmd = <0x65>;
				sec,sensitive_cmd = <0x66>;
				sec,isp_ram_reg = <0x23800>;
				sec,flash_cmd_reg = <0x12400>;
				sec,isp_buffer_reg = <0x12410>;
				sec,config_data_reg = <0x3e000>;
				sec,misctl_reg = <0xd804>;
				sec,watch_dog_reg = <0xd040>;
				sec,config_id_reg = <0x10076>;
				sec,enable_misctl_val = " p\0";
				goodix,edgehandler_direction_max = <0x05>;
			};
		};
	};

	fragment@85 {
		target = <0xffffffff>;

		__overlay__ {
			#address-cells = <0x01>;
			#size-cells = <0x00>;
			status = "okay";
			clock-frequency = <0x61a80>;
			pinctrl-names = "default";

			isg5320a-i2c@2C {
				compatible = "isg5320a";
				status = "okay";
				reg = <0x28>;
				pinctrl-names = "default";
				pinctrl-0 = <0x34>;
				interrupt-parent = <0xffffffff>;
				interrupts = <0x11 0x00>;
				isg5320a,irq-gpio = <0xffffffff 0x11 0x00>;
				isg5320a,hallic_detect = <0x00>;
				isg5320a,hallic_cert_detect = <0x00>;
				isg5320a,reg_num;
				isg5320a,set_reg = [05 fc 06 f0 07 13 08 01 09 80 0a 20 0b 00 0c 00 12 89 19 8a 1b 22 1d 19 1e 00 1f 18 20 05 21 10 22 10 23 00 24 00 25 05 26 05 27 10 28 19 29 00 2a 19 2b 00 2c 00 2d 19 2f 18 30 c0 41 11 60 f0 61 8f 62 07 63 00 64 00 65 44 66 3c 67 01 68 00 69 00 6a 10 6b 00 6c 10 6d 40 6e 22 6f 00 70 01 71 60 72 ff 73 ff 74 ff 7b 08 7c 00 7d 0c 7e 00 7f f8 80 f8 81 00 82 f0 83 f0 84 f0 85 f0 86 f0 87 f0 88 00 89 00 8a 08 8b 00 8c 02 8d 00 99 21 9a 3c 9b 01 9c 2c 9d 00 9e 00 9f 00 a0 96 a1 c0 a2 22 a3 00 a4 08 a5 60 a6 ff a7 ff a8 ff a9 00 af 40 b0 00 b1 60 b2 00 b3 d0 b4 10 b5 28 b6 fd b7 f6 b8 fd b9 de ba fd bb f0 bc 00 bd ff be 01 bf 5e c0 00 c1 6e c2 f0 c3 00 c4 00 c5 00 13 ba 18 f9 1c 18 35 00 36 00 3a 0a 3b 50 3c 0a 3d 50 3e 60 94 10 95 b0 96 06 2e 15 0e e0 0f 1e 10 00 11 c1 d0 e0 d1 02 d2 00 d3 ff d4 ff d5 10 d6 3c d7 ff d8 1e d9 60 da 7f db e0 dc 00 db ff 76 08 77 00 79 02 7a 00 aa 32 ab c8 ad 04 ae 00];
				isg6320,reg_num = <0x97>;
			};
		};
	};

	fragment@86 {
		target = <0xffffffff>;

		__overlay__ {

			grip-int {
				phandle = <0x34>;

				pins_cmd_dat {
					pinmux = <0x1100>;
					slew-rate = <0x00>;
					bias-disable;
				};
			};
		};
	};

	fragment@disp_leds {
		target-path = "/disp_leds/";

		__overlay__ {
			compatible;
		};
	};

	fragment@pwmleds {
		target-path = "/pwmleds/";

		__overlay__ {
			compatible;
		};
	};

	fragment@i2c_leds {
		target-path = "/i2c_leds/";

		__overlay__ {
			compatible;
		};
	};

	fragment@lcd {
		target-path = "/";

		__overlay__ {

			panel {
				compatible = "samsung,mtk-dsi-panel";
				smcdsd_panel = <0x35>;
			};

			smcdsd_board_s6e3fc5 {
				gpio_con = <0xffffffff 0x76 0x00>;
				gpio_pcd = <0xffffffff 0x12 0x01>;
				gpio_det = <0xffffffff 0x01 0x01>;
				gpio_err = <0xffffffff 0x08 0x01>;
				gpio_lcd_3p0_en = <0xffffffff 0x77 0x00>;
				gpio_octa_rst_n = <0xffffffff 0x28 0x00>;
				phandle = <0x37>;

				panel_power_enable {
					type = "regulator,enable\0vcamio\0delay,usleep\02000\0gpio,high\0gpio_lcd_3p0_en\0delay,usleep\011000";
				};

				panel_reset_enable {
					type = "delay,usleep\02000\0gpio,high\0gpio_octa_rst_n\0delay,usleep\01000\0gpio,low\0gpio_octa_rst_n\0delay,usleep\01000\0gpio,high\0gpio_octa_rst_n\0delay,usleep\010000";
				};

				panel_reset_disable {
					type = "gpio,low\0gpio_octa_rst_n\0delay,usleep\02000";
				};

				panel_power_disable {
					type = "gpio,low\0gpio_lcd_3p0_en\0delay,usleep\01000\0regulator,disable\0vcamio\0delay,usleep\01000";
				};

				panel_regulator_init {
					type = "regulator,enable\0vcamio";
				};
			};

			__s6e3fc5_sdc_120 {
				drm_params-vrefresh = <0x78>;
				phandle = <0x36>;
			};

			s6e3fc5_sdc {
				id_match = <0xfffff0 0x800000>;
				lcm_params-dsi-mode = <0x00>;
				lcm_params-dsi-lane_num = <0x04>;
				lcm_params-resolution = <0x438 0x924>;
				lcm_params-physical_width = <0x46>;
				lcm_params-physical_height = <0x97>;
				lcm_params-dsi-horizontal_backporch = <0x02>;
				lcm_params-dsi-horizontal_frontporch = <0x02>;
				lcm_params-dsi-horizontal_sync_active = <0x02>;
				lcm_params-dsi-vertical_backporch = <0x02>;
				lcm_params-dsi-vertical_frontporch = <0x02>;
				lcm_params-dsi-vertical_sync_active = <0x02>;
				lcm_params-dsi-data_rate = <0x326 0x336 0x338>;
				lcm_params-dsi-ssc_disable = <0x01>;
				drm_params-vrefresh = <0x3c>;
				ext_params-dyn_fps-vact_timing_fps = <0x78>;
				vrr_info = <0x35 0x36>;
				dsc_params-enable = <0x01>;
				dsc_params-ver = <0x11>;
				dsc_params-slice_mode = <0x01>;
				dsc_params-rgb_swap = <0x00>;
				dsc_params-dsc_cfg = <0x22>;
				dsc_params-rct_on = <0x01>;
				dsc_params-bit_per_channel = <0x08>;
				dsc_params-dsc_line_buf_depth = <0x09>;
				dsc_params-bp_enable = <0x01>;
				dsc_params-bit_per_pixel = <0x80>;
				dsc_params-pic_height = <0x924>;
				dsc_params-pic_width = <0x438>;
				dsc_params-slice_height = <0x1e>;
				dsc_params-slice_width = <0x21c>;
				dsc_params-chunk_size = <0x21c>;
				dsc_params-xmit_delay = <0x200>;
				dsc_params-dec_delay = <0x20e>;
				dsc_params-scale_value = <0x20>;
				dsc_params-increment_interval = <0x2e3>;
				dsc_params-decrement_interval = <0x07>;
				dsc_params-line_bpg_offset = <0x0c>;
				dsc_params-nfl_bpg_offset = <0x350>;
				dsc_params-slice_bpg_offset = <0x364>;
				dsc_params-initial_offset = <0x1800>;
				dsc_params-final_offset = <0x10f0>;
				dsc_params-flatness_minqp = <0x03>;
				dsc_params-flatness_maxqp = <0x0c>;
				dsc_params-rc_model_size = <0x2000>;
				dsc_params-rc_edge_factor = <0x06>;
				dsc_params-rc_quant_incr_limit0 = <0x0b>;
				dsc_params-rc_quant_incr_limit1 = <0x0b>;
				dsc_params-rc_tgt_offset_hi = <0x03>;
				dsc_params-rc_tgt_offset_lo = <0x03>;
				smcdsd_board = <0x37>;
				phandle = <0x35>;
			};
		};
	};

	fragment@87 {
		target = <0xffffffff>;

		__overlay__ {
			regulator-boot-on;
		};
	};

	fragment@88 {
		target = <0xffffffff>;

		__overlay__ {

			panel@0 {
				compatible = "smcdsd_panel";
			};
		};
	};

	fragment@89 {
		target = <0xffffffff>;

		__overlay__ {
			helper-value = <0x00 0x01 0x01 0x01 0x01 0x00 0x01 0x00 0x01 0x00 0x00 0x01 0x01 0x00 0x01 0x01 0x01 0x01 0x01 0x01 0x01 0x01 0x00 0x01 0x00 0x01 0x00 0x00 0x00 0x00 0x01 0x00 0x00 0x00 0x00 0x00 0x01 0x00 0x00 0x01 0x01 0x00 0x01 0x00 0x00 0x00 0x00 0x00 0x00 0x00 0x01>;
		};
	};

	fragment@sec_wakeup_cpu_allocator {
		target-path = "/";

		__overlay__ {

			sec_wakeup_cpu_allocator {
				compatible = "samsung,sec_wakeup_cpu_allocator";
				start_cpu_num = <0x06>;
				end_cpu_num = <0x07>;
			};
		};
	};

	fragment@90 {
		target = <0xffffffff>;

		__overlay__ {

			spk-amp-en {
				phandle = <0x39>;

				pins_cmd_dat {
					pinmux = <0x1300>;
					slew-rate = <0x00>;
					bias-disable;
					output-low;
				};
			};

			rcv-amp-int {
				phandle = <0x3b>;

				pins_cmd_dat {
					pinmux = <0xf00>;
					slew-rate = <0x00>;
					bias-disable;
					output-low;
				};
			};

			spk-amp-int {
				phandle = <0x3a>;

				pins_cmd_dat {
					pinmux = <0x1000>;
					slew-rate = <0x00>;
					bias-disable;
					output-low;
				};
			};

			i2c-amp-bus {
				phandle = <0x38>;

				pins_cmd_dat {
					pinmux = <0x9c03 0x9d03>;
					slew-rate = <0x00>;
					output-low;
				};
			};
		};
	};

	fragment@91 {
		target = <0xffffffff>;

		__overlay__ {
			status = "okay";
			id = <0x12>;
			clock-frequency = <0x61a80>;
			#address-cells = <0x01>;
			#size-cells = <0x00>;
			pinctrl-names = "default";
			pinctrl-0 = <0x38>;

			tfa98xx@34 {
				#sound-dai-cells = <0x00>;
				compatible = "tfa,tfa98xx";
				reg = <0x34>;
				pinctrl-names = "default";
				pinctrl-0 = <0x39 0x3a>;
				reset-gpio = <0xffffffff 0x13 0x00>;
				irq-gpio = <0xffffffff 0x10 0x00>;
				dummy-cal = <0x1576>;
				inchannel = <0x01>;
				phandle = <0x3c>;
			};

			tfa98xx@35 {
				#sound-dai-cells = <0x00>;
				compatible = "tfa,tfa98xx";
				reg = <0x35>;
				pinctrl-names = "default";
				pinctrl-0 = <0x3b>;
				irq-gpio = <0xffffffff 0x0f 0x00>;
				dummy-cal = <0x1719>;
				inchannel = <0x00>;
				phandle = <0x3d>;
			};
		};
	};

	fragment@92 {
		target = <0xffffffff>;

		__overlay__ {
			mediatek,spk-i2s = <0x03 0x09>;

			mediatek,speaker-codec {
				#sound-dai-cells = <0x02>;
				sound-dai = <0x3c 0x3d>;
			};
		};
	};

	fragment@93 {
		target = <0xffffffff>;

		__overlay__ {

			pins_cmd_dat {
				pinmux = <0x3a00>;
				input-enable;
				bias-pull-down;
			};
		};
	};

	fragment@94 {
		target = <0xffffffff>;

		__overlay__ {

			pins_cmd_dat {
				pinmux = <0x6700 0x6800 0x6a00>;
				slew-rate = <0x01>;
				bias-disable;
			};
		};
	};

	fragment@95 {
		target = <0xffffffff>;

		__overlay__ {
			mtk-dsp-voip = <0x1f 0xffffffff 0xffffffff 0xffffffff 0x30000>;
			mtk-dsp-primary = <0x1f 0xffffffff 0xffffffff 0xffffffff 0x30000>;
			mtk-dsp-offload = <0x00 0xffffffff 0xffffffff 0xffffffff 0x400000>;
			mtk-dsp-deep = <0x07 0xffffffff 0xffffffff 0xffffffff 0x30000>;
			mtk-dsp-playback = <0x01 0x04 0xffffffff 0x14 0x30000>;
			mtk-dsp-music = <0x01 0xffffffff 0xffffffff 0xffffffff 0x00>;
			mtk-dsp-capture1 = <0x01 0xffffffff 0x0d 0x13 0x20000>;
			mtk-dsp-a2dp = <0x01 0xffffffff 0xffffffff 0xffffffff 0x40000>;
			mtk-dsp-dataprovider = <0x00 0xffffffff 0x0f 0xffffffff 0x30000>;
			mtk-dsp-call-final = <0x05 0x04 0x10 0x14 0x18000>;
			mtk-dsp-fast = <0x05 0xffffffff 0xffffffff 0xffffffff 0x5000>;
			mtk-dsp-ktv = <0x01 0x08 0x12 0xffffffff 0x10000>;
			mtk-dsp-capture-raw = <0x00 0xffffffff 0xffffffff 0xffffffff 0x20000>;
			mtk-dsp-fm = <0x01 0xffffffff 0x10 0xffffffff 0x10000>;
			mtk-dsp-ver = <0x01>;
			swdsp-smartpa-process-enable = <0x05>;
			mtk-dsp-mem-afe = <0x01 0x40000>;
		};
	};

	fragment@96 {
		target = <0xffffffff>;

		__overlay__ {

			pd-data {
				pd,vid = <0x4e8>;
				pd,pid = <0x6860>;
				pd,id-vdo-data = <0xd14004e8 0x00 0x68600e01 0x41800000 0x00 0x21800000>;
			};

			dpm_caps {
				attempt-discover-id-dfp;
			};
		};
	};

	fragment@97 {
		target = <0xffffffff>;

		__overlay__ {
			mediatek,discth = <0x08>;
			mediatek,rx-sqth = <0x00>;
			mediatek,eye-src = <0x00>;
			mediatek,intr = <0x19>;
			mediatek,rev4 = <0x01>;
			mediatek,rev6 = <0x03>;
			mediatek,eye-vrt = <0x07>;
			mediatek,eye-term = <0x03>;
			mediatek,disc-host = <0x08>;
			mediatek,eye-src-host = <0x00>;
			mediatek,eye-vrt-host = <0x07>;
			mediatek,eye-term-host = <0x03>;
			mediatek,rev6-host = <0x03>;
		};
	};

	fragment@98 {
		target = <0xffffffff>;

		__overlay__ {

			camera0_mclk_2mA@gpio149 {
				phandle = <0x44>;

				pins_cmd_dat {
					pinmux = <0x9501>;
					drive-strength = <0x00>;
				};
			};

			camera0_mclk_4mA@gpio149 {
				phandle = <0x45>;

				pins_cmd_dat {
					pinmux = <0x9501>;
					drive-strength = <0x01>;
				};
			};

			camera0_mclk_6mA@gpio149 {
				phandle = <0x46>;

				pins_cmd_dat {
					pinmux = <0x9501>;
					drive-strength = <0x02>;
				};
			};

			camera0_mclk_8mA@gpio149 {
				phandle = <0x47>;

				pins_cmd_dat {
					pinmux = <0x9501>;
					drive-strength = <0x03>;
				};
			};

			camera0_mclk_gpio_mode@gpio149 {
				phandle = <0x43>;

				pins_cmd_dat {
					pinmux = <0x9500>;
					drive-strength = <0x03>;
				};
			};

			camera0_rst_output_low@gpio155 {
				phandle = <0x3f>;

				pins_cmd_dat {
					pinmux = <0x9b00>;
					output-low;
				};
			};

			camera0_rst_output_high@gpio155 {
				phandle = <0x40>;

				pins_cmd_dat {
					pinmux = <0x9b00>;
					output-high;
				};
			};

			camera0_vcama1_output_low@gpio110 {
				phandle = <0x41>;

				pins_cmd_dat {
					pinmux = <0x6e00>;
					slew-rate = <0x01>;
					output-low;
				};
			};

			camera0_vcama1_output_high@gpio110 {
				phandle = <0x42>;

				pins_cmd_dat {
					pinmux = <0x6e00>;
					slew-rate = <0x01>;
					output-high;
				};
			};

			camera1_mclk_2mA@gpio153 {
				phandle = <0x4b>;

				pins_cmd_dat {
					pinmux = <0x9901>;
					drive-strength = <0x00>;
				};
			};

			camera1_mclk_4mA@gpio153 {
				phandle = <0x4c>;

				pins_cmd_dat {
					pinmux = <0x9901>;
					drive-strength = <0x01>;
				};
			};

			camera1_mclk_6mA@gpio153 {
				phandle = <0x4d>;

				pins_cmd_dat {
					pinmux = <0x9901>;
					drive-strength = <0x02>;
				};
			};

			camera1_mclk_8mA@gpio153 {
				phandle = <0x4e>;

				pins_cmd_dat {
					pinmux = <0x9901>;
					drive-strength = <0x03>;
				};
			};

			camera1_mclk_gpio_mode@gpio153 {
				phandle = <0x4a>;

				pins_cmd_dat {
					pinmux = <0x9900>;
					drive-strength = <0x02>;
				};
			};

			camera1_rst_output_low@gpio154 {
				phandle = <0x48>;

				pins_cmd_dat {
					pinmux = <0x9a00>;
					output-low;
				};
			};

			camera1_rst_output_high@gpio154 {
				phandle = <0x49>;

				pins_cmd_dat {
					pinmux = <0x9a00>;
					output-high;
				};
			};

			camera2_mclk_2mA@gpio151 {
				phandle = <0x52>;

				pins_cmd_dat {
					pinmux = <0x9701>;
					drive-strength = <0x00>;
				};
			};

			camera2_mclk_4mA@gpio151 {
				phandle = <0x53>;

				pins_cmd_dat {
					pinmux = <0x9701>;
					drive-strength = <0x01>;
				};
			};

			camera2_mclk_6mA@gpio151 {
				phandle = <0x54>;

				pins_cmd_dat {
					pinmux = <0x9701>;
					drive-strength = <0x02>;
				};
			};

			camera2_mclk_8mA@gpio151 {
				phandle = <0x55>;

				pins_cmd_dat {
					pinmux = <0x9701>;
					drive-strength = <0x03>;
				};
			};

			camera2_mclk_gpio_mode@gpio151 {
				phandle = <0x51>;

				pins_cmd_dat {
					pinmux = <0x9700>;
					drive-strength = <0x02>;
				};
			};

			camera2_rst_output_low@gpio158 {
				phandle = <0x4f>;

				pins_cmd_dat {
					pinmux = <0x9e00>;
					output-low;
				};
			};

			camera2_rst_output_high@gpio158 {
				phandle = <0x50>;

				pins_cmd_dat {
					pinmux = <0x9e00>;
					output-high;
				};
			};

			camera3_mclk_2mA@gpio150 {
				phandle = <0x59>;

				pins_cmd_dat {
					pinmux = <0x9601>;
					drive-strength = <0x00>;
				};
			};

			camera3_mclk_4mA@gpio150 {
				phandle = <0x5a>;

				pins_cmd_dat {
					pinmux = <0x9601>;
					drive-strength = <0x01>;
				};
			};

			camera3_mclk_6mA@gpio150 {
				phandle = <0x5b>;

				pins_cmd_dat {
					pinmux = <0x9601>;
					drive-strength = <0x02>;
				};
			};

			camera3_mclk_8mA@gpio150 {
				phandle = <0x5c>;

				pins_cmd_dat {
					pinmux = <0x9601>;
					drive-strength = <0x03>;
				};
			};

			camera3_mclk_gpio_mode@gpio150 {
				phandle = <0x58>;

				pins_cmd_dat {
					pinmux = <0x9600>;
					drive-strength = <0x02>;
				};
			};

			camera3_rst_output_low@gpio159 {
				phandle = <0x56>;

				pins_cmd_dat {
					pinmux = <0x9f00>;
					output-low;
				};
			};

			camera3_rst_output_high@gpio159 {
				phandle = <0x57>;

				pins_cmd_dat {
					pinmux = <0x9f00>;
					output-high;
				};
			};

			camdefault {
				phandle = <0x3e>;
			};
		};
	};

	fragment@99 {
		target = <0xffffffff>;

		__overlay__ {
			pinctrl-names = "default\0cam0_rst0\0cam0_rst1\0cam0_vcama1_off\0cam0_vcama1_on\0cam0_mclk_off\0cam0_mclk_2mA\0cam0_mclk_4mA\0cam0_mclk_6mA\0cam0_mclk_8mA\0cam1_rst0\0cam1_rst1\0cam1_mclk_off\0cam1_mclk_2mA\0cam1_mclk_4mA\0cam1_mclk_6mA\0cam1_mclk_8mA\0cam2_rst0\0cam2_rst1\0cam2_mclk_off\0cam2_mclk_2mA\0cam2_mclk_4mA\0cam2_mclk_6mA\0cam2_mclk_8mA\0cam3_rst0\0cam3_rst1\0cam3_mclk_off\0cam3_mclk_2mA\0cam3_mclk_4mA\0cam3_mclk_6mA\0cam3_mclk_8mA";
			pinctrl-0 = <0x3e>;
			pinctrl-1 = <0x3f>;
			pinctrl-2 = <0x40>;
			pinctrl-3 = <0x41>;
			pinctrl-4 = <0x42>;
			pinctrl-5 = <0x43>;
			pinctrl-6 = <0x44>;
			pinctrl-7 = <0x45>;
			pinctrl-8 = <0x46>;
			pinctrl-9 = <0x47>;
			pinctrl-10 = <0x48>;
			pinctrl-11 = <0x49>;
			pinctrl-12 = <0x4a>;
			pinctrl-13 = <0x4b>;
			pinctrl-14 = <0x4c>;
			pinctrl-15 = <0x4d>;
			pinctrl-16 = <0x4e>;
			pinctrl-17 = <0x4f>;
			pinctrl-18 = <0x50>;
			pinctrl-19 = <0x51>;
			pinctrl-20 = <0x52>;
			pinctrl-21 = <0x53>;
			pinctrl-22 = <0x54>;
			pinctrl-23 = <0x55>;
			pinctrl-24 = <0x56>;
			pinctrl-25 = <0x57>;
			pinctrl-26 = <0x58>;
			pinctrl-27 = <0x59>;
			pinctrl-28 = <0x5a>;
			pinctrl-29 = <0x5b>;
			pinctrl-30 = <0x5c>;
			cam0_vcama-supply = <0x5d>;
			cam0_vcamd-supply = <0x5e>;
			cam0_vcamio-supply = <0x5f>;
			cam0_vcamaf-supply = <0x60>;
			cam1_vcama-supply = <0x61>;
			cam1_vcamd-supply = <0x62>;
			cam1_vcamio-supply = <0x5f>;
			cam2_vcama-supply = <0x61>;
			cam2_vcamd-supply = <0x63>;
			cam2_vcamio-supply = <0x5f>;
			cam3_vcama-supply = <0x61>;
			cam3_vcamd-supply = <0x63>;
			cam3_vcamio-supply = <0x5f>;
			status = "okay";

			vendor {
				rear_sensor_id = <0x78>;
				front_sensor_id = <0x79>;
				rear2_sensor_id = <0xd2>;
				rear3_sensor_id = <0xd2>;
				use_dualcam_set_cal;
				use_module_check;
				max_supported_camera = <0x04>;
				supported_cameraId = <0x00 0x01 0x32 0x36>;
				max_camera_num = <0x05>;

				camera_info0 {
					isp = <0x00>;
					cal_memory = <0x02>;
					read_version = <0x00>;
					core_voltage = <0x00>;
					upgrade = <0x00>;
					companion = <0x00>;
					ois = <0x01>;
					valid = <0x01>;
					dual_open = <0x00>;
					position = <0x00>;
					afcal_type = <0x14>;
					use_adaptive_mipi = <0x00>;
				};

				camera_info1 {
					isp = <0x00>;
					cal_memory = <0x02>;
					read_version = <0x00>;
					core_voltage = <0x00>;
					upgrade = <0x00>;
					companion = <0x00>;
					ois = <0x00>;
					valid = <0x01>;
					dual_open = <0x00>;
					position = <0x01>;
					use_adaptive_mipi = <0x01>;
				};

				camera_info2 {
					isp = <0x00>;
					cal_memory = <0x03>;
					read_version = <0x00>;
					core_voltage = <0x00>;
					upgrade = <0x00>;
					companion = <0x00>;
					ois = <0x00>;
					valid = <0x01>;
					dual_open = <0x00>;
					position = <0x02>;
					use_adaptive_mipi = <0x00>;
				};

				camera_info3 {
					isp = <0x00>;
					cal_memory = <0x03>;
					read_version = <0x00>;
					core_voltage = <0x00>;
					upgrade = <0x00>;
					companion = <0x00>;
					ois = <0x00>;
					valid = <0x01>;
					dual_open = <0x00>;
					position = <0x04>;
					use_adaptive_mipi = <0x00>;
				};
			};
		};
	};

	fragment@cam_ois_drv {
		target-path = "/";

		__overlay__ {

			camera_ois_hw_node {
				compatible = "mediatek,camera_ois_hw";
				pinctrl-names = "default";
				pinctrl-0 = <0x3e>;
				cam0_vcamaf-supply = <0x60>;
				status = "okay";
			};
		};
	};

	fragment@100 {
		target = <0xffffffff>;

		__overlay__ {
			torch_current = <0x0f>;
			flash_current = <0x5dc>;
			factory_current = <0x190>;
			flashlight_current = <0x03 0x05 0x06 0x0d 0x11>;
		};
	};

	fragment@101 {
		target = <0xffffffff>;

		__overlay__ {
			#address-cells = <0x01>;
			#size-cells = <0x00>;
			clock-frequency = <0xf4240>;
			mediatek,use-open-drain;

			camera_main@5A {
				compatible = "mediatek,camera_main";
				reg = <0x2d>;
				status = "okay";
			};
		};
	};

	fragment@102 {
		target = <0xffffffff>;

		__overlay__ {
			#address-cells = <0x01>;
			#size-cells = <0x00>;
			clock-frequency = <0xf4240>;
			mediatek,use-open-drain;

			camera_sub@34 {
				compatible = "mediatek,camera_sub";
				reg = <0x1a>;
				status = "okay";
			};
		};
	};

	fragment@103 {
		target = <0xffffffff>;

		__overlay__ {
			#address-cells = <0x01>;
			#size-cells = <0x00>;
			clock-frequency = <0x61a80>;
			mediatek,use-open-drain;

			camera_main_ois@62 {
				compatible = "mediatek,camera_main_ois";
				reg = <0x62>;
				status = "okay";
			};
		};
	};

	fragment@104 {
		target = <0xffffffff>;

		__overlay__ {
			#address-cells = <0x01>;
			#size-cells = <0x00>;
			clock-frequency = <0x61a80>;
			mediatek,use-open-drain;

			camera_main_two@34 {
				compatible = "mediatek,camera_main_two";
				reg = <0x1a>;
				status = "okay";
			};

			camera_sub_two@6E {
				compatible = "mediatek,camera_sub_two";
				reg = <0x37>;
				status = "okay";
			};
		};
	};

	fragment@105 {
		target = <0xffffffff>;

		__overlay__ {
			#address-cells = <0x01>;
			#size-cells = <0x00>;
			clock-frequency = <0x61a80>;
			mediatek,use-open-drain;

			camera-eeprom0@A0 {
				compatible = "mediatek,camera_eeprom";
				reg = <0x50>;
				status = "okay";
			};

			camera-eeprom2@5A {
				compatible = "mediatek,camera_eeprom";
				reg = <0x2d>;
				status = "okay";
			};

			camera-eeprom3@7E {
				compatible = "mediatek,camera_eeprom";
				reg = <0x3f>;
				status = "okay";
			};

			camera-eeprom1@A2 {
				compatible = "mediatek,camera_eeprom";
				reg = <0x51>;
				status = "okay";
			};

			camera_main_af@18 {
				compatible = "mediatek,camera_main_af";
				reg = <0x0c>;
				status = "okay";
			};
		};
	};

	__fixups__ {
		pio = "/fragment@smd/__overlay__/samsung_mobile_device/sec-mtk-charger:charger,gpio_chgenb:0\0/fragment@smd/__overlay__/samsung_mobile_device/isa1000_vibrator:isa1000,gpio_en:0\0/fragment@smd/__overlay__/samsung_mobile_device/hall_ic/hall:gpios:0\0/fragment@smd/__overlay__/samsung_mobile_device/etspi-spi@0:etspi-sleepPin:0\0/fragment@smd/__overlay__/samsung_mobile_device/etspi-spi@0:etspi-ldoPin:0\0/fragment@smd/__overlay__/samsung_mobile_device/sec-mst:sec-mst,mst-pwr-gpio:0\0/fragment@smd/__overlay__/samsung_mobile_device/gpio_afc:gpio_afc_data:0\0/fragment@smd/__overlay__/samsung_mobile_device/gpio_afc:gpio_afc_switch:0\0/fragment@smd/__overlay__/samsung_mobile_device/gpio_afc:gpio_hiccup:0\0/fragment@0/__overlay__:batteryid-gpio1:0\0/fragment@0/__overlay__:batteryid-gpio:0\0/fragment@5:target:0\0/fragment@6/__overlay__/subpmic_mtk:mt6360,intr_gpio:0\0/fragment@8/__overlay__:mt6360pd,intr_gpio:0\0/fragment@10:target:0\0/fragment@13/__overlay__/panel@0:reset-gpios:0\0/fragment@13/__overlay__/panel@0:lcd-3p0-en-gpios:0\0/fragment@15:target:0\0/fragment@19:target:0\0/fragment@42/__overlay__:GPIO_RF_PWREN_RST_PIN:0\0/fragment@42/__overlay__:GPIO_SIM2_SIO:0\0/fragment@42/__overlay__:GPIO_SIM2_SCLK:0\0/fragment@42/__overlay__:GPIO_SIM2_SRST:0\0/fragment@42/__overlay__:GPIO_SIM1_SRST:0\0/fragment@42/__overlay__:GPIO_SIM1_SCLK:0\0/fragment@42/__overlay__:GPIO_SIM1_SIO:0\0/fragment@42/__overlay__:GPIO_SIM1_HOT_PLUG:0\0/fragment@44/__overlay__:interrupt-parent:0\0/fragment@45/__overlay__:interrupt-parent:0\0/fragment@46/__overlay__:interrupt-parent:0\0/fragment@47/__overlay__:interrupt-parent:0\0/fragment@48/__overlay__:interrupt-parent:0\0/fragment@49/__overlay__:interrupt-parent:0\0/fragment@52/__overlay__:cd-gpios:0\0/fragment@59:target:0\0/fragment@60:target:0\0/fragment@model/__overlay__/i2c@50:gpios:0\0/fragment@model/__overlay__/i2c@50:gpios:12\0/fragment@62:target:0\0/fragment@63:target:0\0/fragment@64:target:0\0/fragment@65:target:0\0/fragment@66:target:0\0/fragment@67:target:0\0/fragment@68:target:0\0/fragment@73:target:0\0/fragment@74:target:0\0/fragment@75:target:0\0/fragment@77:target:0\0/fragment@78:target:0\0/fragment@79:target:0\0/fragment@80:target:0\0/fragment@81:target:0\0/fragment@82/__overlay__/sec-nfc@27:interrupt-parent:0\0/fragment@82/__overlay__/sec-nfc@27:sec-nfc,irq-gpio:0\0/fragment@82/__overlay__/sec-nfc@27:sec-nfc,ven-gpio:0\0/fragment@82/__overlay__/sec-nfc@27:sec-nfc,firm-gpio:0\0/fragment@82/__overlay__/sec-nfc@27:sec-nfc,clk_req-gpio:0\0/fragment@82/__overlay__/sec-nfc@27:sec-nfc,check_nfc:0\0/fragment@83:target:0\0/fragment@84/__overlay__/touchscreen@5d:sec,irq_gpio:0\0/fragment@85/__overlay__/isg5320a-i2c@2C:interrupt-parent:0\0/fragment@85/__overlay__/isg5320a-i2c@2C:isg5320a,irq-gpio:0\0/fragment@86:target:0\0/fragment@lcd/__overlay__/smcdsd_board_s6e3fc5:gpio_con:0\0/fragment@lcd/__overlay__/smcdsd_board_s6e3fc5:gpio_pcd:0\0/fragment@lcd/__overlay__/smcdsd_board_s6e3fc5:gpio_det:0\0/fragment@lcd/__overlay__/smcdsd_board_s6e3fc5:gpio_err:0\0/fragment@lcd/__overlay__/smcdsd_board_s6e3fc5:gpio_lcd_3p0_en:0\0/fragment@lcd/__overlay__/smcdsd_board_s6e3fc5:gpio_octa_rst_n:0\0/fragment@90:target:0\0/fragment@91/__overlay__/tfa98xx@34:reset-gpio:0\0/fragment@91/__overlay__/tfa98xx@34:irq-gpio:0\0/fragment@91/__overlay__/tfa98xx@35:irq-gpio:0\0/fragment@98:target:0";
		auxadc = "/fragment@smd/__overlay__/samsung_mobile_device/battery:io-channels:0\0/fragment@smd/__overlay__/samsung_mobile_device/sec_thermistor@0:io-channels:0\0/fragment@smd/__overlay__/samsung_mobile_device/sec_thermistor@1:io-channels:0\0/fragment@smd/__overlay__/samsung_mobile_device/sec_thermistor@2:io-channels:0\0/fragment@smd/__overlay__/samsung_mobile_device/sec_thermistor@3:io-channels:0\0/fragment@28:target:0\0/fragment@29/__overlay__:io-channels:0";
		topckgen_clk = "/fragment@smd/__overlay__/samsung_mobile_device/etspi-spi@0:clocks:0\0/fragment@smd/__overlay__/samsung_mobile_device/etspi-spi@0:clocks:8";
		infracfg_ao_clk = "/fragment@smd/__overlay__/samsung_mobile_device/etspi-spi@0:clocks:16";
		mtk_gauge = "/fragment@0:target:0";
		mtkheap_region_svp = "/fragment@1:target:0";
		mtkheap_region_wfd = "/fragment@2:target:0";
		chosen = "/fragment@3:target:0";
		irtx_pwm = "/fragment@4:target:0";
		i2c5 = "/fragment@6:target:0";
		mt6360_regulator = "/fragment@7:target:0";
		mt6360_typec = "/fragment@8:target:0\0/fragment@96:target:0";
		mt6359p_dynamic_loading_throttling = "/fragment@9:target:0";
		mtkfb = "/fragment@11:target:0";
		dispsys_config = "/fragment@12:target:0\0/fragment@89:target:0";
		dsi0 = "/fragment@13:target:0\0/fragment@88:target:0";
		odm = "/fragment@14:target:0";
		gps = "/fragment@16:target:0";
		accdet = "/fragment@17:target:0";
		keypad = "/fragment@18:target:0\0/fragment@58:target:0";
		snd_audio_dsp = "/fragment@20:target:0\0/fragment@95:target:0";
		tboard_thermistor1 = "/fragment@21:target:0";
		mmc0 = "/fragment@22:target:0";
		mtee_svp = "/fragment@23:target:0";
		rt5133_gpio1 = "/fragment@24:target:0";
		rt5133_gpio2 = "/fragment@25:target:0";
		rt5133_gpio3 = "/fragment@26:target:0";
		rt5133 = "/fragment@27:target:0";
		md_auxadc = "/fragment@29:target:0";
		pmic_clock_buffer_ctrl = "/fragment@30:target:0";
		i2c0 = "/fragment@31:target:0\0/fragment@84:target:0";
		i2c1 = "/fragment@32:target:0";
		i2c2 = "/fragment@33:target:0\0/fragment@101:target:0";
		i2c3 = "/fragment@34:target:0\0/fragment@82:target:0";
		i2c4 = "/fragment@35:target:0\0/fragment@102:target:0";
		i2c6 = "/fragment@36:target:0\0/fragment@103:target:0";
		i2c7 = "/fragment@37:target:0\0/fragment@85:target:0";
		i2c8 = "/fragment@38:target:0\0/fragment@104:target:0";
		i2c9 = "/fragment@39:target:0\0/fragment@105:target:0";
		i2c10 = "/fragment@40:target:0\0/fragment@61:target:0";
		i2c11 = "/fragment@41:target:0\0/fragment@91:target:0";
		gpio_usage_mapping = "/fragment@42:target:0";
		gpio = "/fragment@43:target:0";
		mrdump_ext_rst = "/fragment@44:target:0";
		msdc1_ins = "/fragment@45:target:0";
		subpmic_pmu_eint = "/fragment@46:target:0";
		irq_nfc = "/fragment@47:target:0";
		touch_panel = "/fragment@48:target:0";
		dsi_te = "/fragment@49:target:0";
		md1_sim1_hot_plug_eint = "/fragment@50:target:0";
		md1_sim2_hot_plug_eint = "/fragment@51:target:0";
		mmc1 = "/fragment@52:target:0";
		mt6359p_vcamio_reg = "/fragment@53:target:0\0/fragment@55/__overlay__:vcamio-supply:0\0/fragment@87:target:0";
		mt_pmic_vtp_ldo_reg = "/fragment@54:target:0\0/fragment@56/__overlay__:vtouch-supply:0\0/fragment@72:target:0\0/fragment@76:target:0";
		kd_camera_hw1 = "/fragment@55:target:0\0/fragment@99:target:0";
		touch = "/fragment@56:target:0";
		mt6359keys = "/fragment@57:target:0";
		mt6359p_vibr_reg = "/fragment@69:target:0";
		mt6359p_vio28_reg = "/fragment@70:target:0\0/fragment@84/__overlay__/touchscreen@5d:tsp_avdd_ldo-supply:0";
		mt_pmic_vfp_ldo_reg = "/fragment@71:target:0\0/fragment@82/__overlay__/sec-nfc@27:nfc_pvdd-supply:0";
		sound = "/fragment@92:target:0";
		aud_dat_miso1_off = "/fragment@93:target:0";
		aud_gpio_i2s3_off = "/fragment@94:target:0";
		u2port0 = "/fragment@97:target:0";
		mt6360_flash0 = "/fragment@100:target:0";
	};

	__local_fixups__ {

		fragment@smd {

			__overlay__ {

				samsung_mobile_device {

					isa1000_vibrator {
						pinctrl-0 = <0x00 0x04>;
					};

					hall_ic {
						pinctrl-0 = <0x00>;
					};

					etspi-spi@0 {
						pinctrl-0 = <0x00 0x04>;
						pinctrl-1 = <0x00 0x04 0x08 0x0c>;
						pinctrl-2 = <0x00 0x04 0x08 0x0c>;
					};

					sec-mst {
						pinctrl-0 = <0x00>;
					};

					gpio_afc {
						pinctrl-0 = <0x00 0x04 0x08>;
					};
				};
			};
		};

		fragment@4 {

			__overlay__ {
				pinctrl-0 = <0x00>;
				pinctrl-1 = <0x00>;
			};
		};

		fragment@11 {

			__overlay__ {
				pinctrl-0 = <0x00>;
				pinctrl-1 = <0x00>;
				pinctrl-2 = <0x00>;
				pinctrl-3 = <0x00>;
				pinctrl-4 = <0x00>;
				pinctrl-5 = <0x00>;
				pinctrl-6 = <0x00>;
				pinctrl-7 = <0x00>;
				pinctrl-8 = <0x00>;
			};
		};

		fragment@12 {

			__overlay__ {
				pinctrl-0 = <0x00>;
				pinctrl-1 = <0x00>;
				pinctrl-2 = <0x00>;
			};
		};

		fragment@13 {

			__overlay__ {

				panel@0 {

					port {

						endpoint {
							remote-endpoint = <0x00>;
						};
					};
				};

				ports {

					port {

						endpoint {
							remote-endpoint = <0x00>;
						};
					};
				};
			};
		};

		fragment@16 {

			__overlay__ {
				pinctrl-0 = <0x00>;
				pinctrl-1 = <0x00>;
				pinctrl-2 = <0x00>;
				pinctrl-3 = <0x00>;
				pinctrl-4 = <0x00>;
				pinctrl-5 = <0x00>;
				pinctrl-6 = <0x00>;
			};
		};

		fragment@18 {

			__overlay__ {
				pinctrl-0 = <0x00>;
			};
		};

		fragment@model {

			__overlay__ {

				i2c@50 {
					pinctrl-0 = <0x00 0x04>;
				};
			};
		};

		fragment@82 {

			__overlay__ {

				sec-nfc@27 {
					pinctrl-0 = <0x00 0x04 0x08 0x0c 0x10>;
					pinctrl-1 = <0x00 0x04 0x08 0x0c>;
				};
			};
		};

		fragment@84 {

			__overlay__ {

				touchscreen@5d {
					pinctrl-0 = <0x00>;
					pinctrl-1 = <0x00>;
				};
			};
		};

		fragment@85 {

			__overlay__ {

				isg5320a-i2c@2C {
					pinctrl-0 = <0x00>;
				};
			};
		};

		fragment@lcd {

			__overlay__ {

				panel {
					smcdsd_panel = <0x00>;
				};

				s6e3fc5_sdc {
					vrr_info = <0x00 0x04>;
					smcdsd_board = <0x00>;
				};
			};
		};

		fragment@91 {

			__overlay__ {
				pinctrl-0 = <0x00>;

				tfa98xx@34 {
					pinctrl-0 = <0x00 0x04>;
				};

				tfa98xx@35 {
					pinctrl-0 = <0x00>;
				};
			};
		};

		fragment@92 {

			__overlay__ {

				mediatek,speaker-codec {
					sound-dai = <0x00 0x04>;
				};
			};
		};

		fragment@99 {

			__overlay__ {
				pinctrl-0 = <0x00>;
				pinctrl-1 = <0x00>;
				pinctrl-2 = <0x00>;
				pinctrl-3 = <0x00>;
				pinctrl-4 = <0x00>;
				pinctrl-5 = <0x00>;
				pinctrl-6 = <0x00>;
				pinctrl-7 = <0x00>;
				pinctrl-8 = <0x00>;
				pinctrl-9 = <0x00>;
				pinctrl-10 = <0x00>;
				pinctrl-11 = <0x00>;
				pinctrl-12 = <0x00>;
				pinctrl-13 = <0x00>;
				pinctrl-14 = <0x00>;
				pinctrl-15 = <0x00>;
				pinctrl-16 = <0x00>;
				pinctrl-17 = <0x00>;
				pinctrl-18 = <0x00>;
				pinctrl-19 = <0x00>;
				pinctrl-20 = <0x00>;
				pinctrl-21 = <0x00>;
				pinctrl-22 = <0x00>;
				pinctrl-23 = <0x00>;
				pinctrl-24 = <0x00>;
				pinctrl-25 = <0x00>;
				pinctrl-26 = <0x00>;
				pinctrl-27 = <0x00>;
				pinctrl-28 = <0x00>;
				pinctrl-29 = <0x00>;
				pinctrl-30 = <0x00>;
				cam0_vcama-supply = <0x00>;
				cam0_vcamd-supply = <0x00>;
				cam0_vcamio-supply = <0x00>;
				cam0_vcamaf-supply = <0x00>;
				cam1_vcama-supply = <0x00>;
				cam1_vcamd-supply = <0x00>;
				cam1_vcamio-supply = <0x00>;
				cam2_vcama-supply = <0x00>;
				cam2_vcamd-supply = <0x00>;
				cam2_vcamio-supply = <0x00>;
				cam3_vcama-supply = <0x00>;
				cam3_vcamd-supply = <0x00>;
				cam3_vcamio-supply = <0x00>;
			};
		};

		fragment@cam_ois_drv {

			__overlay__ {

				camera_ois_hw_node {
					pinctrl-0 = <0x00>;
					cam0_vcamaf-supply = <0x00>;
				};
			};
		};
	};
};
